VERSION "HNNBNNNYNNNNNNNNNNNNNNNNNNNNNNNNNNNNNNNNNN/4/%%%/4/'%**4NNN///"

NS_ :

BS_:

BU_: BAP_Tester Gateway_Max Getriebe_DQ Motor_konv Parksperre Schaltbetaetigung

BO_ 270 Getriebe_50: 48 Getriebe_DQ
 SG_ Getriebe_50_CRC : 0|8@1+ (1,0) [0|255] ""  Gateway_Max,Motor_konv
 SG_ Getriebe_50_BZ : 8|4@1+ (1,0) [0|15] ""  Gateway_Max,Motor_konv
 SG_ GE_MMom_Soll_02 : 12|10@1+ (1,-509) [-509|509] ""  Gateway_Max,Motor_konv
 SG_ GE_MMom_Vorhalt_02 : 22|10@1+ (1,-509) [-509|509] ""  Gateway_Max,Motor_konv
 SG_ GE_Uefkt : 32|10@1+ (0.1,0) [0.0|102.2] ""  Gateway_Max,Motor_konv
 SG_ GE2_Fahrstufe : 42|4@1+ (1.0,0.0) [0.0|15] ""  Gateway_Max,Motor_konv
 SG_ GE2_Ursache_Fahrstufe_N : 46|1@1+ (1.0,0.0) [0.0|1] ""  Gateway_Max
 SG_ GE_Schaltablauf : 47|2@1+ (1.0,0.0) [0.0|3] ""  Gateway_Max,Motor_konv
 SG_ GE_Uefkt_unplausibel : 49|1@1+ (1.0,0.0) [0.0|1] ""  Gateway_Max
 SG_ GE_MMom_Status_02 : 50|3@1+ (1.0,0.0) [0.0|7] ""  Gateway_Max,Motor_konv
 SG_ GE_Status_Kraftschluss : 53|3@1+ (1.0,0.0) [0.0|7] ""  Gateway_Max,Motor_konv
 SG_ GE_MMom_Status : 56|2@1+ (1.0,0.0) [0.0|3] ""  Gateway_Max,Motor_konv
 SG_ GE_Freig_MMom_Vorhalt : 58|1@1+ (1.0,0.0) [0.0|1] ""  Gateway_Max,Motor_konv
 SG_ GE_Verbot_Ausblendung : 59|1@1+ (1.0,0.0) [0.0|1] ""  Gateway_Max,Motor_konv
 SG_ GE_Zielgang : 60|4@1+ (1.0,0.0) [0.0|15] ""  Gateway_Max,Motor_konv
 SG_ GE_Fahrstufenwunsch : 72|4@1+ (1.0,0.0) [0.0|15] ""  Gateway_Max,Motor_konv
 SG_ GE_Drehzahlmesser_Daempfung : 76|1@1+ (1.0,0.0) [0.0|1] ""  Gateway_Max,Motor_konv
 SG_ GE_Schubabschalt_Unt : 77|1@1+ (1.0,0.0) [0.0|1] ""  Gateway_Max,Motor_konv
 SG_ GE_Freigabe_Synchro : 78|1@1+ (1.0,0.0) [0.0|1] ""  Gateway_Max,Motor_konv
 SG_ GE_Synchro_Wunschdrehz : 79|9@1+ (25,0) [25|12750] "Unit_MinutInver"  Gateway_Max,Motor_konv
 SG_ GE_Synchro_Zeit : 88|8@1+ (20,0) [0|5080] "Unit_MilliSecon"  Gateway_Max,Motor_konv
 SG_ GE_Mom_Begr_Gradient : 96|8@1+ (10,0) [0|2540] "Unit_NewtoMeterPerSecon"  Gateway_Max,Motor_konv
 SG_ GE_Anheb_Solldrehz_Leerlauf : 104|8@1+ (10,0) [0|2540] "Unit_MinutInver"  Gateway_Max,Motor_konv
 SG_ GE_Aufnahmemoment : 112|10@1+ (1,-509) [-509|509] ""  Gateway_Max,Motor_konv
 SG_ GE_Synchro_Status_02 : 122|4@1+ (1.0,0.0) [0.0|15] ""  Gateway_Max,Motor_konv
 SG_ GE_StartStopp_Info : 140|2@1+ (1.0,0.0) [0.0|3] ""  Gateway_Max,Motor_konv
 SG_ GE_Langfr_Schutzmom_02 : 142|9@1+ (1,0) [0|509] ""  Gateway_Max,Motor_konv
 SG_ GE_Entkopplung_Status : 151|2@1+ (1.0,0.0) [0.0|3] ""  Gateway_Max
 SG_ GE_Verlustmoment : 160|8@1+ (1,0) [0|254] ""  Gateway_Max,Motor_konv
 SG_ GE_Anf_Zylabsch : 168|2@1+ (1.0,0.0) [0.0|3] ""  Gateway_Max,Motor_konv
 SG_ GE_Grenzkriechmoment : 170|6@1+ (2,0) [0|122] ""  Gateway_Max
 SG_ GE_Eingangsdrehz : 176|14@1+ (1,0) [0|16381] "Unit_MinutInver"  Gateway_Max,Motor_konv
 SG_ GE_Notlauf : 190|1@1+ (1.0,0.0) [0.0|1] ""  Gateway_Max,Motor_konv
 SG_ GE_Freig_Langfr_Schutzmom : 191|1@1+ (1.0,0.0) [0.0|1] ""  Gateway_Max,Motor_konv
 SG_ GE_HYB_Fehlerstatus : 204|2@1+ (1.0,0.0) [0.0|3] ""  Gateway_Max
 SG_ GE_HYB_DZ_Eingriff : 206|2@1+ (1.0,0.0) [0.0|3] ""  Gateway_Max
 SG_ GE_HYB_Freigabe_K0 : 208|1@1+ (1.0,0.0) [0.0|1] ""  Gateway_Max
 SG_ GE_HYB_MaxMomK0 : 209|2@1+ (1.0,0.0) [0.0|3] ""  Gateway_Max
 SG_ GE_HYB_Freig_VM_EM_Stop : 211|1@1+ (1.0,0.0) [0.0|1] ""  Gateway_Max
 SG_ GE_HYB_Wiederstart : 212|1@1+ (1.0,0.0) [0.0|1] ""  Gateway_Max
 SG_ GE_HYB_Filt_MomAufbau : 213|3@1+ (1.0,0.0) [0.0|7] ""  Gateway_Max
 SG_ GE_HYB_nK0 : 216|8@1+ (25,0) [0|6350] "Unit_MinutInver"  Gateway_Max
 SG_ GE_HYB_EM_KompMom : 224|7@1+ (2,0) [0|254] "Unit_NewtoMeter"  Gateway_Max
 SG_ GE_HYB_IstStatus_K0 : 231|2@1+ (1.0,0.0) [0.0|3] ""  Gateway_Max
 SG_ GE_HYB_Wiederstartreserve : 233|7@1+ (2,0) [0|254] "Unit_NewtoMeter"  Gateway_Max
 SG_ GE_HYB_VM_Soll_Moment : 240|8@1+ (1.186,-50) [-50.000|250.058] "Unit_NewtoMeter"  Gateway_Max
 SG_ GE_HYB_Sportfaktor : 248|4@1+ (1.0,0.0) [0.0|15] ""  Gateway_Max
 SG_ GE_HYB_Freigabe_LL_Reg : 252|1@1+ (1.0,0.0) [0.0|1] ""  Gateway_Max
 SG_ GE_HYB_VM_akt_halten : 253|1@1+ (1.0,0.0) [0.0|1] ""  Gateway_Max
 SG_ GE_HYB_StartAnf : 254|1@1+ (1.0,0.0) [0.0|1] ""  Gateway_Max
 SG_ GE_HYB_VM_Startkontr : 255|1@1+ (1.0,0.0) [0.0|1] ""  Gateway_Max
 SG_ GE_Radmoment : 256|16@1+ (0.5,-16383) [-16383.0|16383.5] "Unit_NewtoMeter"  Gateway_Max,Motor_konv
 SG_ GE_Abtriebsdrehzahl : 272|16@1+ (0.1,-3276.65) [-3276.65|3276.65] "Unit_MinutInver"  Gateway_Max,Motor_konv
 SG_ GE_Eingangswellengradient : 288|16@1+ (0.25,-8191.5) [-8191.50|8191.75] "Unit_MeterInver"  Gateway_Max,Motor_konv

BO_ 509 Getriebe_51: 32 Getriebe_DQ
 SG_ Getriebe_51_CRC : 0|8@1+ (1,0) [0|255] ""  Gateway_Max,Motor_konv
 SG_ Getriebe_51_BZ : 8|4@1+ (1,0) [0|15] ""  Gateway_Max,Motor_konv
 SG_ GE_OBD_AbsperrVent : 12|4@1+ (1.0,0.0) [0.0|15] ""  Gateway_Max,Motor_konv
 SG_ GE_amax_moeglich : 16|9@1+ (0.024,-2.016) [-2.016|10.224] "Unit_MeterPerSeconSquar"  Gateway_Max,Motor_konv
 SG_ GE_Charisma_FahrPr : 25|4@1+ (1.0,0.0) [0.0|15] ""  Gateway_Max
 SG_ GE_Charisma_Status : 29|2@1+ (1.0,0.0) [0.0|3] ""  Gateway_Max
 SG_ GE_Freigabe_Verfallsinfo_WFS : 31|1@1+ (1.0,0.0) [0.0|1] ""  Gateway_Max,Motor_konv
 SG_ Freilauf_Charisma_FahrPr : 40|4@1+ (1.0,0.0) [0.0|15] ""  Gateway_Max
 SG_ Freilauf_Charisma_Status : 44|2@1+ (1.0,0.0) [0.0|3] ""  Gateway_Max
 SG_ GE_Freigabe_Info_WFS : 46|1@1+ (1.0,0.0) [0.0|1] ""  Gateway_Max,Motor_konv
 SG_ GE_Sperr_Info_WFS : 47|1@1+ (1.0,0.0) [0.0|1] ""  Gateway_Max,Motor_konv
 SG_ GE_Zustand_Kuppltemp : 48|2@1+ (1.0,0.0) [0.0|3] ""  Gateway_Max
 SG_ GE_Codierung_MSG : 50|1@1+ (1.0,0.0) [0.0|1] ""  Gateway_Max
 SG_ GE_LaunchControl : 51|1@1+ (1.0,0.0) [0.0|1] ""  Gateway_Max,Motor_konv
 SG_ GE_Heizwunsch : 52|2@1+ (1.0,0.0) [0.0|3] ""  Gateway_Max,Motor_konv
 SG_ GE_OBD_Status : 54|1@1+ (1.0,0.0) [0.0|1] ""  Gateway_Max,Motor_konv
 SG_ GE_LFR_Adaption : 55|1@1+ (1.0,0.0) [0.0|1] ""  Gateway_Max,Motor_konv
 SG_ GE_Sumpftemperatur : 56|8@1+ (1,-58) [-58|196] "Unit_DegreCelsi"  Gateway_Max,Motor_konv
 SG_ GE_Schleuderoeltemperatur : 64|8@1+ (1,-58) [-58|195] "Unit_DegreCelsi"  Gateway_Max
 SG_ GE_Weckleitung_aktiv : 72|1@1+ (1.0,0.0) [0.0|1] ""  Gateway_Max
 SG_ GE_Fahrprogramm : 76|4@1+ (1.0,0.0) [0.0|15] ""  Gateway_Max,Motor_konv
 SG_ GE_TippZustand : 80|2@1+ (1.0,0.0) [0.0|3] ""  Gateway_Max,Motor_konv
 SG_ GE_Freilauf_Status : 82|3@1+ (1.0,0.0) [0.0|7] ""  Gateway_Max,Motor_konv
 SG_ GE_Grundeinstellung : 85|1@1+ (1.0,0.0) [0.0|1] ""  Gateway_Max
 SG_ GE_Anschleppstart_Freigabe : 86|1@1+ (1.0,0.0) [0.0|1] ""  Gateway_Max,Motor_konv
 SG_ GE_Strombedarf_erh : 87|1@1+ (1.0,0.0) [0.0|1] ""  Gateway_Max
 SG_ GE_Parken_WFS_Status : 88|2@1+ (1.0,0.0) [0.0|3] ""  Gateway_Max
 SG_ FSA_Fehlerstatus_Parksperre : 90|2@1+ (1.0,0.0) [0.0|3] ""  Gateway_Max
 SG_ GE_SpannungsAnf : 97|2@1+ (1.0,0.0) [0.0|3] ""  Gateway_Max
 SG_ GE_QBit_Sumpftemperatur : 99|1@1+ (1.0,0.0) [0.0|1] ""  Gateway_Max
 SG_ GE_Grundeinstell_Drehrichtung_EM : 100|1@1+ (1.0,0.0) [0.0|1] ""  Gateway_Max
 SG_ GE_Veto_Rollfaehigkeit : 101|1@1+ (1.0,0.0) [0.0|1] ""  Gateway_Max
 SG_ GE_Parken_beibehalten_HMS : 102|2@1+ (1.0,0.0) [0.0|3] ""  Gateway_Max
 SG_ GE_Anforderung_HMS : 104|3@1+ (1.0,0.0) [0.0|7] ""  Gateway_Max
 SG_ GE_Betaetigung_Hold : 107|1@1+ (1.0,0.0) [0.0|1] ""  Gateway_Max

BO_ 2589283964 Getriebe_52: 16 Getriebe_DQ
 SG_ GE_OBD_Status_Auth : 12|1@1+ (1.0,0.0) [0.0|1] ""  Motor_konv
 SG_ GE_Indc_StChk : 13|1@1+ (1.0,0.0) [0.0|1] ""  Motor_konv
 SG_ GE_Indc_StFail : 14|1@1+ (1.0,0.0) [0.0|1] ""  Motor_konv
 SG_ SOK_Getriebe_52_Signatur : 64|64@1+ (1,0) [1|18446744073709551615] "Unit_None"  Motor_konv

BO_ 299 GRA_ACC_01: 8 Gateway_Max
 SG_ GRA_ACC_01_CRC : 0|8@1+ (1,0) [0|255] ""  Motor_konv
 SG_ GRA_ACC_01_BZ : 8|4@1+ (1,0) [0|15] ""  Motor_konv
 SG_ GRA_Hauptschalter : 12|1@1+ (1.0,0.0) [0.0|1] ""  Motor_konv
 SG_ GRA_Abbrechen : 13|1@1+ (1.0,0.0) [0.0|1] ""  Motor_konv
 SG_ GRA_Typ_Hauptschalter : 14|1@1+ (1.0,0.0) [0.0|1] ""  Motor_konv
 SG_ GRA_Limiter : 15|1@1+ (1.0,0.0) [0.0|1] ""  Motor_konv
 SG_ GRA_Tip_Setzen : 16|1@1+ (1.0,0.0) [0.0|1] ""  Motor_konv
 SG_ GRA_Tip_Hoch : 17|1@1+ (1.0,0.0) [0.0|1] ""  Motor_konv
 SG_ GRA_Tip_Runter : 18|1@1+ (1.0,0.0) [0.0|1] ""  Motor_konv
 SG_ GRA_Tip_Wiederaufnahme : 19|1@1+ (1.0,0.0) [0.0|1] ""  Motor_konv
 SG_ GRA_Verstellung_Zeitluecke : 20|2@1+ (1.0,0.0) [0.0|3] ""  Motor_konv
 SG_ GRA_Codierung : 22|2@1+ (1.0,0.0) [0.0|3] ""  Motor_konv
 SG_ GRA_Fehler : 24|1@1+ (1.0,0.0) [0.0|1] ""  Motor_konv
 SG_ GRA_LIM_Taste_verfuegbar : 25|1@1+ (1.0,0.0) [0.0|1] ""  Motor_konv
 SG_ GRA_Tip_Stufe_2 : 26|1@1+ (1.0,0.0) [0.0|1] ""  Motor_konv
 SG_ GRA_Typ_Bedienteil : 27|3@1+ (1.0,0.0) [0.0|7] ""  Motor_konv
 SG_ GRA_TravelAssist : 30|1@1+ (1.0,0.0) [0.0|1] ""  Vector__XXX
 SG_ GRA_PIT_Limiter : 31|1@1+ (1.0,0.0) [0.0|1] ""  Motor_konv
 SG_ GRA_reserveByte5 : 32|8@1+ (1.0,0.0) [0.0|255] ""  Vector__XXX
 SG_ GRA_reserveByte6 : 40|8@1+ (1.0,0.0) [0.0|255] ""  Vector__XXX
 SG_ GRA_reserveByte7 : 48|8@1+ (1.0,0.0) [0.0|255] ""  Vector__XXX
 SG_ GRA_reserveByte8 : 56|8@1+ (1.0,0.0) [0.0|255] ""  Vector__XXX

BO_ 18 GSG_WFS_Anfrage: 8 Getriebe_DQ
 SG_ WFS_GSG_RND : 0|32@1+ (1.0,0.0) [0.0|4294967295] ""  Gateway_Max
 SG_ WFS_GSG_CRC : 32|32@1+ (1.0,0.0) [0.0|4294967295] ""  Gateway_Max

BO_ 2589283397 GW_CVN_Komponentenfehler_02: 32 Gateway_Max
 SG_ GW_CAL_ID_Index_01 : 0|8@1+ (1.0,0.0) [0.0|255] ""  Motor_konv
 SG_ GW_CAL_ID_Index_02 : 8|8@1+ (1.0,0.0) [0.0|255] ""  Motor_konv
 SG_ GW_CAL_ID_Index_03 : 16|8@1+ (1.0,0.0) [0.0|255] ""  Motor_konv
 SG_ GW_CAL_ID_Index_04 : 24|8@1+ (1.0,0.0) [0.0|255] ""  Motor_konv
 SG_ GW_CAL_ID_Index_05 : 32|8@1+ (1.0,0.0) [0.0|255] ""  Motor_konv
 SG_ GW_CAL_ID_Index_06 : 40|8@1+ (1.0,0.0) [0.0|255] ""  Motor_konv
 SG_ GW_CAL_ID_Index_07 : 48|8@1+ (1.0,0.0) [0.0|255] ""  Motor_konv
 SG_ GW_CAL_ID_Index_08 : 56|8@1+ (1.0,0.0) [0.0|255] ""  Motor_konv
 SG_ GW_CAL_ID_Index_09 : 64|8@1+ (1.0,0.0) [0.0|255] ""  Motor_konv
 SG_ GW_CAL_ID_Index_10 : 72|8@1+ (1.0,0.0) [0.0|255] ""  Motor_konv
 SG_ GW_CAL_ID_Index_11 : 80|8@1+ (1.0,0.0) [0.0|255] ""  Motor_konv
 SG_ GW_CAL_ID_Index_12 : 88|8@1+ (1.0,0.0) [0.0|255] ""  Motor_konv
 SG_ GW_CAL_ID_Index_13 : 96|8@1+ (1.0,0.0) [0.0|255] ""  Motor_konv
 SG_ GW_CAL_ID_Index_14 : 104|8@1+ (1.0,0.0) [0.0|255] ""  Motor_konv
 SG_ GW_CAL_ID_Index_15 : 112|8@1+ (1.0,0.0) [0.0|255] ""  Motor_konv
 SG_ GW_CAL_ID_Index_16 : 120|8@1+ (1.0,0.0) [0.0|255] ""  Motor_konv
 SG_ GW_KomponentenFehler_01 : 128|2@1+ (1.0,0.0) [0.0|3] ""  Motor_konv
 SG_ GW_Komponentenfehler_02 : 130|2@1+ (1.0,0.0) [0.0|3] ""  Motor_konv
 SG_ GW_Komponentenfehler_03 : 132|2@1+ (1.0,0.0) [0.0|3] ""  Motor_konv
 SG_ GW_Komponentenfehler_04 : 134|2@1+ (1.0,0.0) [0.0|3] ""  Motor_konv
 SG_ GW_Komponentenfehler_05 : 136|2@1+ (1.0,0.0) [0.0|3] ""  Motor_konv
 SG_ GW_Komponentenfehler_06 : 138|2@1+ (1.0,0.0) [0.0|3] ""  Motor_konv
 SG_ GW_Komponentenfehler_07 : 140|2@1+ (1.0,0.0) [0.0|3] ""  Motor_konv
 SG_ GW_Komponentenfehler_08 : 142|2@1+ (1.0,0.0) [0.0|3] ""  Motor_konv
 SG_ GW_Komponentenfehler_09 : 144|2@1+ (1.0,0.0) [0.0|3] ""  Motor_konv
 SG_ GW_Komponentenfehler_10 : 146|2@1+ (1.0,0.0) [0.0|3] ""  Motor_konv
 SG_ GW_Komponentenfehler_11 : 148|2@1+ (1.0,0.0) [0.0|3] ""  Motor_konv
 SG_ GW_Komponentenfehler_12 : 150|2@1+ (1.0,0.0) [0.0|3] ""  Motor_konv
 SG_ GW_Komponentenfehler_13 : 152|2@1+ (1.0,0.0) [0.0|3] ""  Getriebe_DQ,Motor_konv
 SG_ GW_Komponentenfehler_14 : 154|2@1+ (1.0,0.0) [0.0|3] ""  Motor_konv
 SG_ GW_Komponentenfehler_15 : 156|2@1+ (1.0,0.0) [0.0|3] ""  Motor_konv
 SG_ GW_Komponentenfehler_16 : 158|2@1+ (1.0,0.0) [0.0|3] ""  Motor_konv
 SG_ GW_CVN : 160|32@1+ (1.0,0.0) [0.0|4294967295] ""  Motor_konv
 SG_ GW_Komponentenfehler_17 : 192|2@1+ (1.0,0.0) [0.0|3] ""  Motor_konv
 SG_ GW_Komponentenfehler_18 : 194|2@1+ (1.0,0.0) [0.0|3] ""  Motor_konv
 SG_ GW_Komponentenfehler_19 : 196|2@1+ (1.0,0.0) [0.0|3] ""  Motor_konv
 SG_ GW_Komponentenfehler_20 : 198|2@1+ (1.0,0.0) [0.0|3] ""  Motor_konv
 SG_ GW_Komponentenfehler_21 : 200|2@1+ (1.0,0.0) [0.0|3] ""  Motor_konv
 SG_ GW_Komponentenfehler_22 : 202|2@1+ (1.0,0.0) [0.0|3] ""  Motor_konv
 SG_ GW_Komponentenfehler_23 : 204|2@1+ (1.0,0.0) [0.0|3] ""  Motor_konv
 SG_ GW_Komponentenfehler_24 : 206|2@1+ (1.0,0.0) [0.0|3] ""  Motor_konv
 SG_ GW_Komponentenfehler_25 : 208|2@1+ (1.0,0.0) [0.0|3] ""  Motor_konv
 SG_ GW_Komponentenfehler_26 : 210|2@1+ (1.0,0.0) [0.0|3] ""  Motor_konv
 SG_ GW_Komponentenfehler_27 : 212|2@1+ (1.0,0.0) [0.0|3] ""  Motor_konv
 SG_ GW_Komponentenfehler_28 : 214|2@1+ (1.0,0.0) [0.0|3] ""  Motor_konv
 SG_ GW_Komponentenfehler_29 : 216|2@1+ (1.0,0.0) [0.0|3] ""  Motor_konv
 SG_ GW_Komponentenfehler_30 : 218|2@1+ (1.0,0.0) [0.0|3] ""  Motor_konv
 SG_ GW_Komponentenfehler_31 : 220|2@1+ (1.0,0.0) [0.0|3] ""  Motor_konv
 SG_ GW_Komponentenfehler_32 : 222|2@1+ (1.0,0.0) [0.0|3] ""  Motor_konv
 SG_ GW_Komponentenfehler_33 : 224|2@1+ (1.0,0.0) [0.0|3] ""  Motor_konv
 SG_ GW_Komponentenfehler_34 : 226|2@1+ (1.0,0.0) [0.0|3] ""  Motor_konv
 SG_ GW_Komponentenfehler_35 : 228|2@1+ (1.0,0.0) [0.0|3] ""  Motor_konv
 SG_ GW_Komponentenfehler_36 : 230|2@1+ (1.0,0.0) [0.0|3] ""  Motor_konv
 SG_ GW_Komponentenfehler_37 : 232|2@1+ (1.0,0.0) [0.0|3] ""  Motor_konv
 SG_ GW_Komponentenfehler_38 : 234|2@1+ (1.0,0.0) [0.0|3] ""  Motor_konv
 SG_ GW_Komponentenfehler_39 : 236|2@1+ (1.0,0.0) [0.0|3] ""  Motor_konv
 SG_ GW_Komponentenfehler_40 : 238|2@1+ (1.0,0.0) [0.0|3] ""  Motor_konv
 SG_ GW_Komponentenfehler_41 : 240|2@1+ (1.0,0.0) [0.0|3] ""  Motor_konv
 SG_ GW_Komponentenfehler_42 : 242|2@1+ (1.0,0.0) [0.0|3] ""  Motor_konv
 SG_ GW_Komponentenfehler_43 : 244|2@1+ (1.0,0.0) [0.0|3] ""  Motor_konv
 SG_ GW_Komponentenfehler_44 : 246|2@1+ (1.0,0.0) [0.0|3] ""  Motor_konv
 SG_ GW_Komponentenfehler_45 : 248|2@1+ (1.0,0.0) [0.0|3] ""  Motor_konv
 SG_ GW_Komponentenfehler_46 : 250|2@1+ (1.0,0.0) [0.0|3] ""  Motor_konv
 SG_ GW_Komponentenfehler_47 : 252|2@1+ (1.0,0.0) [0.0|3] ""  Motor_konv
 SG_ GW_Komponentenfehler_VLD : 254|1@1+ (1.0,0.0) [0.0|1] ""  Motor_konv
 SG_ GW_CVN_VLD : 255|1@1+ (1.0,0.0) [0.0|1] ""  Motor_konv

BO_ 2589283454 GW_CVN_Komponentenfehler_02_S000: 8 Gateway_Max
 SG_ SOK_GW_CVN_Komp_02_Signatur : 0|64@1+ (1,0) [1|18446744073709551615] "Unit_None"  Motor_konv

BO_ 2589284072 GW_CVN_Komponentenfehler_03: 32 Gateway_Max
 SG_ GW_Komponentenfehler_48 : 0|2@1+ (1.0,0.0) [0.0|3] ""  Motor_konv
 SG_ GW_Komponentenfehler_49 : 2|2@1+ (1.0,0.0) [0.0|3] ""  Motor_konv
 SG_ GW_Komponentenfehler_50 : 4|2@1+ (1.0,0.0) [0.0|3] ""  Motor_konv
 SG_ GW_Komponentenfehler_51 : 6|2@1+ (1.0,0.0) [0.0|3] ""  Motor_konv
 SG_ GW_Komponentenfehler_52 : 8|2@1+ (1.0,0.0) [0.0|3] ""  Motor_konv
 SG_ GW_Komponentenfehler_53 : 10|2@1+ (1.0,0.0) [0.0|3] ""  Motor_konv
 SG_ GW_Komponentenfehler_54 : 12|2@1+ (1.0,0.0) [0.0|3] ""  Motor_konv
 SG_ GW_Komponentenfehler_55 : 14|2@1+ (1.0,0.0) [0.0|3] ""  Motor_konv
 SG_ GW_Komponentenfehler_56 : 16|2@1+ (1.0,0.0) [0.0|3] ""  Motor_konv
 SG_ GW_Komponentenfehler_57 : 18|2@1+ (1.0,0.0) [0.0|3] ""  Motor_konv
 SG_ GW_Komponentenfehler_58 : 20|2@1+ (1.0,0.0) [0.0|3] ""  Motor_konv
 SG_ GW_Komponentenfehler_59 : 22|2@1+ (1.0,0.0) [0.0|3] ""  Motor_konv
 SG_ GW_Komponentenfehler_60 : 24|2@1+ (1.0,0.0) [0.0|3] ""  Motor_konv
 SG_ GW_Komponentenfehler_61 : 26|2@1+ (1.0,0.0) [0.0|3] ""  Motor_konv
 SG_ GW_Komponentenfehler_62 : 28|2@1+ (1.0,0.0) [0.0|3] ""  Motor_konv
 SG_ GW_Komponentenfehler_63 : 30|2@1+ (1.0,0.0) [0.0|3] ""  Motor_konv
 SG_ GW_Komponentenfehler_64 : 32|2@1+ (1.0,0.0) [0.0|3] ""  Motor_konv
 SG_ SOK_GW_CVN_Komp_03_Signatur : 192|64@1+ (1,0) [1|18446744073709551615] "Unit_None"  Motor_konv

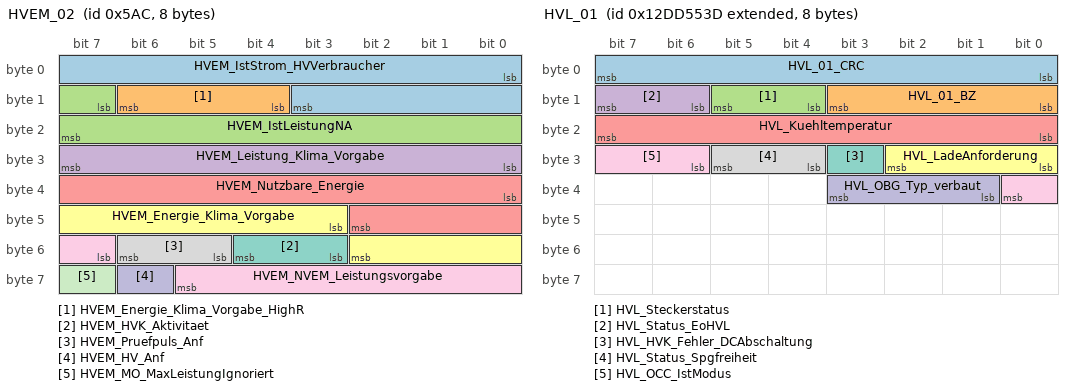
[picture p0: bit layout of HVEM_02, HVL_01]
BO_ 1452 HVEM_02: 8 Gateway_Max
 SG_ HVEM_IstStrom_HVVerbraucher : 0|12@1+ (0.1,-204.7) [-204.7|204.6] "Unit_Amper"  Vector__XXX
 SG_ HVEM_Energie_Klima_Vorgabe_HighR : 12|3@1+ (10,0) [0|50] "Unit_WattHour"  Vector__XXX
 SG_ HVEM_IstLeistungNA : 15|9@1+ (50,0) [0|25450] "Unit_Watt"  Vector__XXX
 SG_ HVEM_Leistung_Klima_Vorgabe : 24|8@1+ (50,0) [0|12650] "Unit_Watt"  Vector__XXX
 SG_ HVEM_Nutzbare_Energie : 32|11@1+ (50,0) [0|102200] "Unit_WattHour"  Vector__XXX
 SG_ HVEM_Energie_Klima_Vorgabe : 43|8@1+ (50,0) [0|12650] "Unit_WattHour"  Vector__XXX
 SG_ HVEM_HVK_Aktivitaet : 51|2@1+ (1.0,0.0) [0.0|3] ""  Vector__XXX
 SG_ HVEM_Pruefpuls_Anf : 53|2@1+ (1.0,0.0) [0.0|3] ""  Vector__XXX
 SG_ HVEM_NVEM_Leistungsvorgabe : 55|7@1+ (50,0) [0|6250] "Unit_Watt"  Vector__XXX
 SG_ HVEM_HV_Anf : 62|1@1+ (1.0,0.0) [0.0|1] ""  Vector__XXX
 SG_ HVEM_MO_MaxLeistungIgnoriert : 63|1@1+ (1.0,0.0) [0.0|1] ""  Vector__XXX

BO_ 1385 HVEM_04: 8 Gateway_Max
 SG_ HVEM_ZusatzMinLeistungNA_Anf : 0|9@1+ (50,0) [0|25450] "Unit_Watt"  Vector__XXX
 SG_ HVEM_Betriebsart : 9|3@1+ (1.0,0.0) [0.0|7] ""  Vector__XXX
 SG_ HVEM_NVLeistungEmpf : 12|4@1+ (100,0) [0|1500] "Unit_Watt"  Vector__XXX
 SG_ HVEM_DCDC_Freigabe : 16|1@1+ (1.0,0.0) [0.0|1] ""  Vector__XXX
 SG_ HVEM_KlimaMaxHVStrom : 17|5@1+ (1,0) [0|31] "Unit_Amper"  Vector__XXX
 SG_ HVEM_Ladesteckerentr_Anf : 23|1@1+ (1.0,0.0) [0.0|1] ""  Vector__XXX
 SG_ HVEM_LeistungsAnf : 24|1@1+ (1.0,0.0) [0.0|1] ""  Vector__XXX
 SG_ HVEM_Nachlad_Status : 25|2@1+ (1.0,0.0) [0.0|3] ""  Vector__XXX
 SG_ HVEM_Abschaltstatus : 27|3@1+ (1.0,0.0) [0.0|7] ""  Vector__XXX
 SG_ HVEM_Anf_ReichweiteNV : 30|2@1+ (1.0,0.0) [0.0|3] ""  Vector__XXX
 SG_ HVEM_WunschLeistungNA_Anf : 32|9@1+ (50,0) [0|25450] "Unit_Watt"  Vector__XXX
 SG_ HVEM_Text_1 : 41|1@1+ (1.0,0.0) [0.0|1] ""  Vector__XXX
 SG_ HVEM_Nachladen_Anf : 42|1@1+ (1.0,0.0) [0.0|1] ""  Vector__XXX
 SG_ HVEM_FreigabeKlimatisierung : 43|2@1+ (1.0,0.0) [0.0|3] ""  Vector__XXX
 SG_ HVEM_FreigabeBattHeizung : 45|2@1+ (1.0,0.0) [0.0|3] ""  Vector__XXX
 SG_ HVEM_MinLeistungNA_Anf : 47|9@1+ (50,0) [0|25450] "Unit_Watt"  Vector__XXX
 SG_ HVEM_Leistung_Bat_Kond_Vorgabe : 56|8@1+ (50,0) [0|12650] "Unit_Watt"  Vector__XXX

BO_ 1283 HVK_01: 8 Vector__XXX
 SG_ HVK_01_CRC : 0|8@1+ (1,0) [0|255] ""  Gateway_Max
 SG_ HVK_01_BZ : 8|4@1+ (1,0) [0|15] ""  Gateway_Max
 SG_ HVK_Istmodus_Anf : 12|1@1+ (1.0,0.0) [0.0|1] ""  Gateway_Max
 SG_ HVK_TN1_Sollmodus : 13|2@1+ (1.0,0.0) [0.0|3] ""  Gateway_Max
 SG_ HVK_Vorladung_aktiv : 15|1@1+ (1.0,0.0) [0.0|1] ""  Gateway_Max
 SG_ HVK_BMS_Sollmodus : 24|3@1+ (1.0,0.0) [0.0|7] ""  Gateway_Max
 SG_ HVK_DCDC_Sollmodus : 27|3@1+ (1.0,0.0) [0.0|7] ""  Gateway_Max
 SG_ HVK_EKK_Sollmodus : 30|3@1+ (1.0,0.0) [0.0|7] ""  Gateway_Max
 SG_ HVK_HVPTC_Sollmodus : 33|3@1+ (1.0,0.0) [0.0|7] ""  Gateway_Max
 SG_ HVK_HVLM_Sollmodus : 36|3@1+ (1.0,0.0) [0.0|7] ""  Gateway_Max
 SG_ HVK_HV_Netz_Warnungen : 39|2@1+ (1.0,0.0) [0.0|3] ""  Gateway_Max
 SG_ HV_Bordnetz_aktiv : 41|1@1+ (1.0,0.0) [0.0|1] ""  Gateway_Max
 SG_ HV_Bordnetz_Fehler : 42|1@1+ (1.0,0.0) [0.0|1] ""  Gateway_Max
 SG_ HVK_Gesamtst_Spgfreiheit : 43|2@1+ (1.0,0.0) [0.0|3] ""  Gateway_Max
 SG_ HVK_AktiveEntladung_Anf : 45|1@1+ (1.0,0.0) [0.0|1] ""  Gateway_Max
 SG_ HVK_HVEM_Freigabe : 46|2@1+ (1.0,0.0) [0.0|3] ""  Gateway_Max
 SG_ HVK_Notabschaltung_Anf : 48|2@1+ (1.0,0.0) [0.0|3] ""  Gateway_Max
 SG_ HVK_Iso_Messung_Start : 50|3@1+ (1.0,0.0) [0.0|7] ""  Gateway_Max
 SG_ HVK_Ladebereit : 53|3@1+ (1.0,0.0) [0.0|7] ""  Gateway_Max
 SG_ HVK_PPulsFreigabe : 56|2@1+ (1.0,0.0) [0.0|3] ""  Gateway_Max

BO_ 2331595857 HVK_04: 24 Vector__XXX
 SG_ HVK_BMS_DC_Ladeschuetze_Soll : 12|3@1+ (1.0,0.0) [0.0|7] ""  Gateway_Max
 SG_ HVK_BMS_Hauptschuetze_Soll : 15|3@1+ (1.0,0.0) [0.0|7] ""  Gateway_Max
 SG_ HVK_DC_PruefpulsStatus : 18|2@1+ (1.0,0.0) [0.0|3] ""  Gateway_Max

BO_ 2463978813 HVL_01: 8 Gateway_Max
 SG_ HVL_01_CRC : 0|8@1+ (1,0) [0|255] ""  Vector__XXX
 SG_ HVL_01_BZ : 8|4@1+ (1,0) [0|15] ""  Vector__XXX
 SG_ HVL_Steckerstatus : 12|2@1+ (1.0,0.0) [0.0|3] ""  Vector__XXX
 SG_ HVL_Status_EoHVL : 14|2@1+ (1.0,0.0) [0.0|3] ""  Vector__XXX
 SG_ HVL_Kuehltemperatur : 16|8@1+ (1,-40) [-40|213] "Unit_DegreCelsi"  Vector__XXX
 SG_ HVL_LadeAnforderung : 24|3@1+ (1.0,0.0) [0.0|7] ""  Vector__XXX
 SG_ HVL_HVK_Fehler_DCAbschaltung : 27|1@1+ (1.0,0.0) [0.0|1] ""  Vector__XXX
 SG_ HVL_Status_Spgfreiheit : 28|2@1+ (1.0,0.0) [0.0|3] ""  Vector__XXX
 SG_ HVL_OCC_IstModus : 30|3@1+ (1.0,0.0) [0.0|7] ""  Vector__XXX
 SG_ HVL_OBG_Typ_verbaut : 33|3@1+ (1.0,0.0) [0.0|7] ""  Vector__XXX

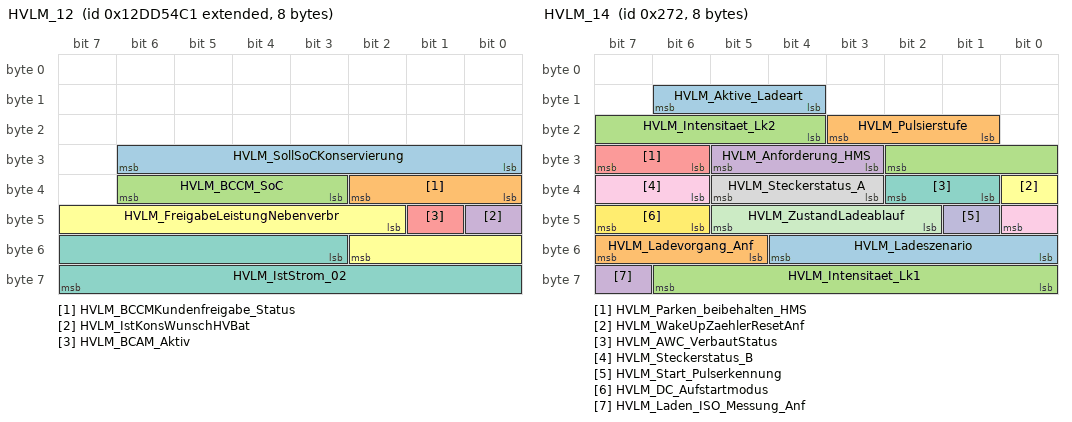
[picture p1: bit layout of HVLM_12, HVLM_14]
BO_ 2463978689 HVLM_12: 8 Gateway_Max
 SG_ HVLM_SollSoCKonservierung : 24|7@1+ (1,0) [0|100] "Unit_PerCent"  Vector__XXX
 SG_ HVLM_BCCMKundenfreigabe_Status : 32|3@1+ (1.0,0.0) [0.0|7] ""  Vector__XXX
 SG_ HVLM_BCCM_SoC : 35|4@1+ (5,50) [50|100] "Unit_PerCent"  Vector__XXX
 SG_ HVLM_IstKonsWunschHVBat : 40|1@1+ (1.0,0.0) [0.0|1] ""  Vector__XXX
 SG_ HVLM_BCAM_Aktiv : 41|1@1+ (1.0,0.0) [0.0|1] ""  Vector__XXX
 SG_ HVLM_FreigabeLeistungNebenverbr : 42|9@1+ (50,0) [0|25500] "Unit_Watt"  Vector__XXX
 SG_ HVLM_IstStrom_02 : 51|13@1+ (0.1,-409.4) [-409.4|409.5] "Unit_Amper"  Vector__XXX

BO_ 626 HVLM_14: 8 Gateway_Max
 SG_ HVLM_Aktive_Ladeart : 12|3@1+ (1.0,0.0) [0.0|7] ""  Vector__XXX
 SG_ HVLM_Pulsierstufe : 17|3@1+ (1.0,0.0) [0.0|7] ""  Vector__XXX
 SG_ HVLM_Intensitaet_Lk2 : 20|7@1+ (1,0) [0|100] "Unit_PerCent"  Vector__XXX
 SG_ HVLM_Anforderung_HMS : 27|3@1+ (1.0,0.0) [0.0|7] ""  Vector__XXX
 SG_ HVLM_Parken_beibehalten_HMS : 30|2@1+ (1.0,0.0) [0.0|3] ""  Vector__XXX
 SG_ HVLM_WakeUpZaehlerResetAnf : 32|1@1+ (1.0,0.0) [0.0|1] ""  Vector__XXX
 SG_ HVLM_AWC_VerbautStatus : 33|2@1+ (1.0,0.0) [0.0|3] ""  Vector__XXX
 SG_ HVLM_Steckerstatus_A : 35|3@1+ (1.0,0.0) [0.0|7] ""  Vector__XXX
 SG_ HVLM_Steckerstatus_B : 38|3@1+ (1.0,0.0) [0.0|7] ""  Vector__XXX
 SG_ HVLM_Start_Pulserkennung : 41|1@1+ (1.0,0.0) [0.0|1] ""  Vector__XXX
 SG_ HVLM_ZustandLadeablauf : 42|4@1+ (1.0,0.0) [0.0|15] ""  Vector__XXX
 SG_ HVLM_DC_Aufstartmodus : 46|2@1+ (1.0,0.0) [0.0|3] ""  Vector__XXX
 SG_ HVLM_Ladeszenario : 48|5@1+ (1.0,0.0) [0.0|31] ""  Vector__XXX
 SG_ HVLM_Ladevorgang_Anf : 53|3@1+ (1.0,0.0) [0.0|7] ""  Vector__XXX
 SG_ HVLM_Intensitaet_Lk1 : 56|7@1+ (1,0) [0|100] "Unit_PerCent"  Vector__XXX
 SG_ HVLM_Laden_ISO_Messung_Anf : 63|1@1+ (1.0,0.0) [0.0|1] ""  Vector__XXX

BO_ 268 IMMO_CORD_01: 8 Motor_konv
 SG_ ImoCord_Auth_Aufforderung_WFS : 63|1@1+ (1.0,0.0) [0.0|1] ""  Getriebe_DQ

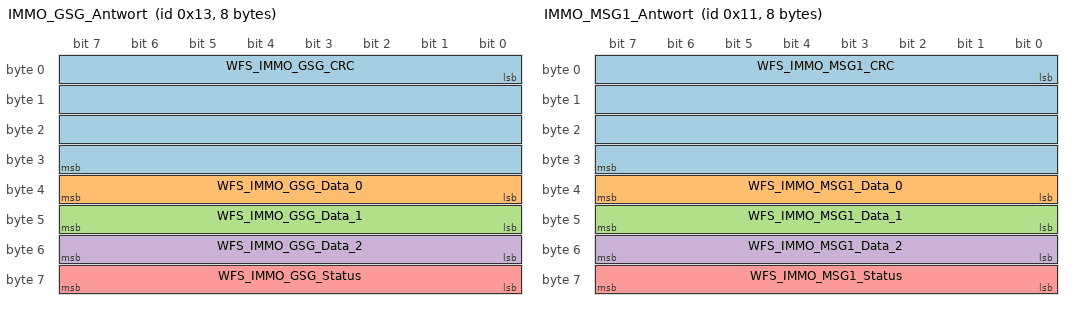
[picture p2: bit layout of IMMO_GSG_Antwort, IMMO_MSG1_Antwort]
BO_ 19 IMMO_GSG_Antwort: 8 Gateway_Max
 SG_ WFS_IMMO_GSG_CRC : 0|32@1+ (1.0,0.0) [0.0|4294967295] ""  Getriebe_DQ
 SG_ WFS_IMMO_GSG_Data_0 : 32|8@1+ (1.0,0.0) [0.0|255] ""  Getriebe_DQ
 SG_ WFS_IMMO_GSG_Data_1 : 40|8@1+ (1.0,0.0) [0.0|255] ""  Getriebe_DQ
 SG_ WFS_IMMO_GSG_Data_2 : 48|8@1+ (1.0,0.0) [0.0|255] ""  Getriebe_DQ
 SG_ WFS_IMMO_GSG_Status : 56|8@1+ (1,0) [0|255] ""  Getriebe_DQ

BO_ 17 IMMO_MSG1_Antwort: 8 Gateway_Max
 SG_ WFS_IMMO_MSG1_CRC : 0|32@1+ (1.0,0.0) [0.0|4294967295] ""  Motor_konv
 SG_ WFS_IMMO_MSG1_Data_0 : 32|8@1+ (1.0,0.0) [0.0|255] ""  Motor_konv
 SG_ WFS_IMMO_MSG1_Data_1 : 40|8@1+ (1.0,0.0) [0.0|255] ""  Motor_konv
 SG_ WFS_IMMO_MSG1_Data_2 : 48|8@1+ (1.0,0.0) [0.0|255] ""  Motor_konv
 SG_ WFS_IMMO_MSG1_Status : 56|8@1+ (1,0) [0|255] ""  Motor_konv

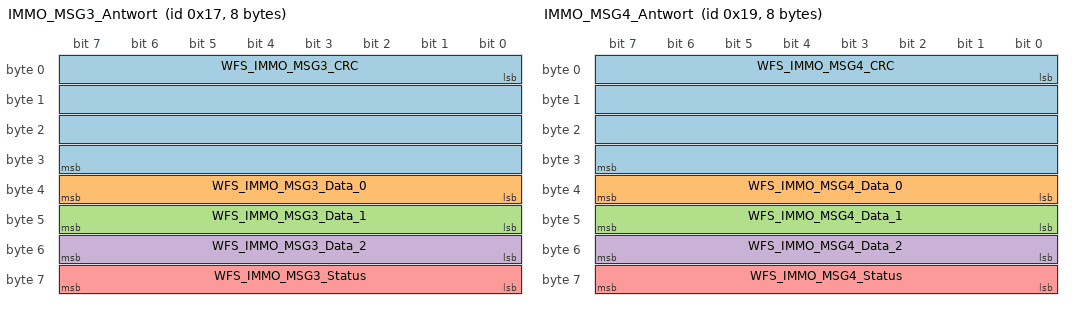
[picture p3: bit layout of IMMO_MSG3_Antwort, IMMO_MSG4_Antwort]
BO_ 23 IMMO_MSG3_Antwort: 8 Gateway_Max
 SG_ WFS_IMMO_MSG3_CRC : 0|32@1+ (1.0,0.0) [0.0|4294967295] ""  Vector__XXX
 SG_ WFS_IMMO_MSG3_Data_0 : 32|8@1+ (1.0,0.0) [0.0|255] ""  Vector__XXX
 SG_ WFS_IMMO_MSG3_Data_1 : 40|8@1+ (1.0,0.0) [0.0|255] ""  Vector__XXX
 SG_ WFS_IMMO_MSG3_Data_2 : 48|8@1+ (1.0,0.0) [0.0|255] ""  Vector__XXX
 SG_ WFS_IMMO_MSG3_Status : 56|8@1+ (1,0) [0|255] ""  Vector__XXX

BO_ 25 IMMO_MSG4_Antwort: 8 Gateway_Max
 SG_ WFS_IMMO_MSG4_CRC : 0|32@1+ (1.0,0.0) [0.0|4294967295] ""  Vector__XXX
 SG_ WFS_IMMO_MSG4_Data_0 : 32|8@1+ (1.0,0.0) [0.0|255] ""  Vector__XXX
 SG_ WFS_IMMO_MSG4_Data_1 : 40|8@1+ (1.0,0.0) [0.0|255] ""  Vector__XXX
 SG_ WFS_IMMO_MSG4_Data_2 : 48|8@1+ (1.0,0.0) [0.0|255] ""  Vector__XXX
 SG_ WFS_IMMO_MSG4_Status : 56|8@1+ (1,0) [0|255] ""  Vector__XXX

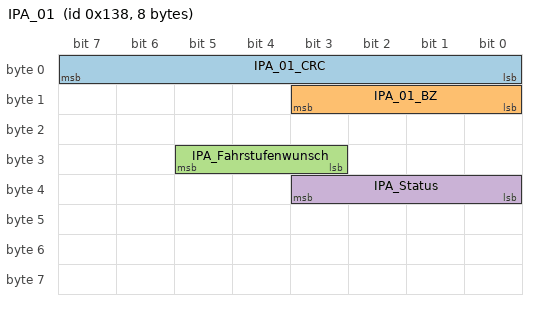
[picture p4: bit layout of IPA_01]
BO_ 312 IPA_01: 8 Gateway_Max
 SG_ IPA_01_CRC : 0|8@1+ (1,0) [0|255] ""  Getriebe_DQ,Motor_konv
 SG_ IPA_01_BZ : 8|4@1+ (1,0) [0|15] ""  Getriebe_DQ,Motor_konv
 SG_ IPA_Fahrstufenwunsch : 27|3@1+ (1.0,0.0) [0.0|7] ""  Getriebe_DQ
 SG_ IPA_Status : 32|4@1+ (1.0,0.0) [0.0|15] ""  Getriebe_DQ,Motor_konv

BO_ 2527679583 IPA_02: 8 Gateway_Max
 SG_ IPA_02_CRC : 0|8@1+ (1,0) [0|255] ""  Vector__XXX
 SG_ IPA_02_BZ : 8|4@1+ (1,0) [0|15] ""  Vector__XXX
 SG_ IPA_PL_Anzeige_links : 12|2@1+ (1.0,0.0) [0.0|3] ""  Vector__XXX
 SG_ IPA_PL_Anzeige_rechts : 14|2@1+ (1.0,0.0) [0.0|3] ""  Vector__XXX
 SG_ Parken_Seitenspiegel_Anf : 20|2@1+ (1.0,0.0) [0.0|3] ""  Vector__XXX
 SG_ Parken_ZV_Schliessen : 22|2@1+ (1.0,0.0) [0.0|3] ""  Vector__XXX
 SG_ Parken_aktives_System_02 : 24|5@1+ (1.0,0.0) [0.0|31] ""  Getriebe_DQ,Motor_konv
 SG_ Parken_ZR_Sondermodus_Anf : 29|2@1+ (1.0,0.0) [0.0|3] ""  Vector__XXX
 SG_ Parken_Schluesselsuche_Anf : 31|1@1+ (1.0,0.0) [0.0|1] ""  Vector__XXX
 SG_ Parken_FFB_LED_Anf : 32|2@1+ (1.0,0.0) [0.0|3] ""  Vector__XXX
 SG_ Parken_Wegfahrsperren_Anf : 34|2@1+ (1.0,0.0) [0.0|3] ""  Vector__XXX
 SG_ Parken_Aktivierungslicht_Anf : 36|1@1+ (1.0,0.0) [0.0|1] ""  Vector__XXX
 SG_ Parken_Fahrtrichtungslicht_Anf : 37|2@1+ (1.0,0.0) [0.0|3] ""  Vector__XXX
 SG_ Parken_Lichtnachlauf_Anf : 39|1@1+ (1.0,0.0) [0.0|1] ""  Vector__XXX
 SG_ IPA_Akustik_PL_gefunden : 45|1@1+ (1.0,0.0) [0.0|1] ""  Vector__XXX
 SG_ Parken_Blinker_li_Anf : 46|1@1+ (1.0,0.0) [0.0|1] ""  Vector__XXX
 SG_ Parken_Blinker_re_Anf : 47|1@1+ (1.0,0.0) [0.0|1] ""  Vector__XXX
 SG_ Parken_Fahrerhinweise_Anf : 51|1@1+ (1.0,0.0) [0.0|1] ""  Vector__XXX
 SG_ Parken_Bestaetigungsblinken_Anf : 52|2@1+ (1.0,0.0) [0.0|3] ""  Vector__XXX
 SG_ Parken_Fahrbereitschaftlicht_Anf : 54|1@1+ (1.0,0.0) [0.0|1] ""  Vector__XXX
 SG_ Parken_Lichtsteuerung_Anf : 55|1@1+ (1.0,0.0) [0.0|1] ""  Vector__XXX
 SG_ IPA_Anf_Meldungen : 56|8@1+ (1.0,0.0) [0.0|255] ""  Vector__XXX

BO_ 2589283690 IPB_03: 16 Gateway_Max
 SG_ LAD_OBD_Lampe_Anf : 23|1@1+ (1.0,0.0) [0.0|1] ""  Vector__XXX
 SG_ IPB_ThermAuslastungsgrad : 24|8@1+ (1,0) [0|100] "Unit_PerCent"  Vector__XXX
 SG_ TNV_Temperatur : 32|8@1+ (1,-40) [-40|213] "Unit_PerCent"  Vector__XXX
 SG_ IPB_Wasser_TEMP_EIN : 40|8@1+ (1,-40) [-40|213] "Unit_DegreCelsi"  Vector__XXX
 SG_ IPB_Wasser_TEMP_AUS : 48|8@1+ (1,-40) [-40|213] "Unit_DegreCelsi"  Vector__XXX
 SG_ HVLE_Temperatur : 56|8@1+ (1,-40) [-40|213] "Unit_DegreCelsi"  Vector__XXX
 SG_ HVLE_ThermAuslastungsgrad : 64|8@1+ (1,0) [0|100] "Unit_PerCent"  Vector__XXX
 SG_ HVLE_eTM_max_Vorlauftemperatur : 72|8@1+ (1,-40) [-40|213] "Unit_DegreCelsi"  Vector__XXX
 SG_ OBDProtocol_Ladegeraet : 88|8@1+ (1.0,0.0) [0.0|255] ""  Vector__XXX

BO_ 2589283695 IPB_03_SOK_Signatur: 8 Gateway_Max
 SG_ SOK_IPB_03_Signatur : 0|64@1+ (1,0) [1|18446744073709551615] "Unit_None"  Vector__XXX

BO_ 1892 ISO_AGA_Req: 8 Gateway_Max
 SG_ ISO_AGA_Req_Data : 0|64@1+ (1.0,0.0) [0.0|18446744073709551615] ""  Vector__XXX

BO_ 1998 ISO_AGA_Resp: 8 Vector__XXX
 SG_ ISO_AGA_Resp_Data : 0|64@1+ (1.0,0.0) [0.0|18446744073709551615] ""  Gateway_Max

BO_ 1792 ISO_Funktionaler_Req_All: 8 Gateway_Max
 SG_ ISO_ALL_01_Req_Data : 0|64@1+ (1.0,0.0) [0.0|18446744073709551615] ""  Getriebe_DQ,Motor_konv

BO_ 1820 ISO_Soundaktor_Req: 8 Gateway_Max
 SG_ ISO_Soundaktor_Req_Data : 0|64@1+ (1.0,0.0) [0.0|18446744073709551615] ""  Vector__XXX

BO_ 1926 ISO_Soundaktor_Resp: 8 Vector__XXX
 SG_ ISO_Soundaktor_Resp_Data : 0|64@1+ (1.0,0.0) [0.0|18446744073709551615] ""  Gateway_Max

BO_ 2549874812 ISOx_EMotor_01_Req: 8 Gateway_Max
 SG_ ISOx_EMotor_01_Req_Data : 0|64@1+ (1.0,0.0) [0.0|18446744073709551615] ""  Vector__XXX

BO_ 2621440124 ISOx_EMotor_01_Req_FD: 64 Gateway_Max
 SG_ ISOx_EMotor_01_Req_FD_Data : 0|512@1+ (1.0,0.0) [0.0|13407807929942597099574024998205846127479365820592393377723561443721764030073546976801874298166903427690031858186486050853753882811946569946433649006084095] ""  Vector__XXX

BO_ 2550005884 ISOx_EMotor_01_Resp: 8 Vector__XXX
 SG_ ISOx_EMotor_01_Resp_Data : 0|64@1+ (1.0,0.0) [0.0|18446744073709551615] ""  Gateway_Max

BO_ 2621571196 ISOx_EMotor_01_Resp_FD: 64 Vector__XXX
 SG_ ISOx_EMotor_01_Resp_FD_Data : 0|512@1+ (1.0,0.0) [0.0|13407807929942597099574024998205846127479365820592393377723561443721764030073546976801874298166903427690031858186486050853753882811946569946433649006084095] ""  Gateway_Max

BO_ 2549874872 ISOx_EMotor_02_Req: 8 Gateway_Max
 SG_ ISOx_EMotor_02_Req_Data : 0|64@1+ (1.0,0.0) [0.0|18446744073709551615] ""  Vector__XXX

BO_ 2621440184 ISOx_EMotor_02_Req_FD: 64 Gateway_Max
 SG_ ISOx_EMotor_02_Req_FD_Data : 0|512@1+ (1.0,0.0) [0.0|13407807929942597099574024998205846127479365820592393377723561443721764030073546976801874298166903427690031858186486050853753882811946569946433649006084095] ""  Vector__XXX

BO_ 2550005944 ISOx_EMotor_02_Resp: 8 Vector__XXX
 SG_ ISOx_EMotor_02_Resp_Data : 0|64@1+ (1.0,0.0) [0.0|18446744073709551615] ""  Gateway_Max

BO_ 2621571256 ISOx_EMotor_02_Resp_FD: 64 Vector__XXX
 SG_ ISOx_EMotor_02_Resp_FD_Data : 0|512@1+ (1.0,0.0) [0.0|13407807929942597099574024998205846127479365820592393377723561443721764030073546976801874298166903427690031858186486050853753882811946569946433649006084095] ""  Gateway_Max

BO_ 2621505536 ISOx_Funkt_Req_All_FD: 64 Gateway_Max
 SG_ ISOx_Funkt_Req_All_FD_Data : 0|512@1+ (1.0,0.0) [0.0|13407807929942597099574024998205846127479365820592393377723561443721764030073546976801874298166903427690031858186486050853753882811946569946433649006084095] ""  Getriebe_DQ,Motor_konv

BO_ 2549874807 ISOx_Getriebe_01_Req: 8 Gateway_Max
 SG_ ISOx_Getriebe_01_Req_Data : 0|64@1+ (1.0,0.0) [0.0|18446744073709551615] ""  Getriebe_DQ

BO_ 2621440119 ISOx_Getriebe_01_Req_FD: 64 Gateway_Max
 SG_ ISOx_Getriebe_01_Req_FD_Data : 0|512@1+ (1.0,0.0) [0.0|13407807929942597099574024998205846127479365820592393377723561443721764030073546976801874298166903427690031858186486050853753882811946569946433649006084095] ""  Getriebe_DQ

BO_ 2550005879 ISOx_Getriebe_01_Resp: 8 Getriebe_DQ
 SG_ ISOx_Getriebe_01_Resp_Data : 0|64@1+ (1.0,0.0) [0.0|18446744073709551615] ""  Gateway_Max

BO_ 2621571191 ISOx_Getriebe_01_Resp_FD: 64 Getriebe_DQ
 SG_ ISOx_Getriebe_01_Resp_FD_Data : 0|512@1+ (1.0,0.0) [0.0|13407807929942597099574024998205846127479365820592393377723561443721764030073546976801874298166903427690031858186486050853753882811946569946433649006084095] ""  Gateway_Max

BO_ 2550399033 ISOx_LCU_SMH_Req: 8 Gateway_Max
 SG_ ISOx_LCU_SMH_Req_Data : 0|64@1+ (1.0,0.0) [0.0|18446744073709551615] ""  Vector__XXX

BO_ 2621702201 ISOx_LCU_SMH_Req_FD: 64 Gateway_Max
 SG_ ISOx_LCU_SMH_Req_FD_Data : 0|512@1+ (1.0,0.0) [0.0|13407807929942597099574024998205846127479365820592393377723561443721764030073546976801874298166903427690031858186486050853753882811946569946433649006084095] ""  Vector__XXX

CM_ BO_ 2527679583 "ehemals ZFAS_01";
CM_ BO_ 2621505536 "VWAG Diagnose funktionaler Request auf CANFD";

CM_ SG_ 270 GE2_Fahrstufe "Fahrprogramm des Getriebes (redundantes Signal zu Getriebe_11.GE_Fahrstufe wg. Autosar-Modellierung notwendig)

Hinweis: Zwischenstellung '0x0' darf nur für Zustandswechsel P/R, R/N, N/D ausgegeben werden, nicht für D/S oder D/Tippgasse wegen Abschaltkr";
CM_ SG_ 270 GE2_Ursache_Fahrstufe_N "Zeigt an, warum Fahrstufe N angenommen wurde. So kann z.B. die Rollsicherung im Verlassenskonzept aktiv bleiben, wenn das Schalten nach N ohne Fahrerwunsch erfolgte (z.B. Fehlerreaktion).

ACHTUNG: Das Signal darf nur ausgewertet werden, wenn GE_Fahrstu";
CM_ SG_ 270 GE_Abtriebsdrehzahl "Mittlere abtriebsseitige Getriebedrehzahl";
CM_ SG_ 270 GE_Anf_Zylabsch "GE_Anforderung_Zylinderabschaltung
Getriebe-Koordination Zylinderumschaltung TMB / VMB (Teilmotorbetrieb / Vollmotorbetrieb)";
CM_ SG_ 270 GE_Anheb_Solldrehz_Leerlauf "Anforderung einer absoluten Leerlaufdrehzahl";
CM_ SG_ 270 GE_Aufnahmemoment "Zeigt das Drehmoment, mit dem das Getriebe den Motor an der Kurbelwelle belastet = Ölpumpenmoment + Kupplung-/Wandler-Moment.

Signal soll grundsätzlich im kompletten Fahrbetrieb bedient werden; in bestimmten Situationen kann vom GSG der Wert 1022 = 'We";
CM_ SG_ 270 GE_Drehzahlmesser_Daempfung "Beim DQ-Getriebe kann die Anzeigedämpfung des Drehzahlmessers beim Schalten geändert werden.";
CM_ SG_ 270 GE_Eingangsdrehz "Wird gesendet, um das Lastschlagverhalten bei Schaltvorgängen zu verbessern.";
CM_ SG_ 270 GE_Eingangswellengradient "Gradient der Eingangswellendrehzahl, wird in der Schaltung mit Fortschritt der Drehzahlüberführung auf den Drehzahlgradienten der kommenden Eingangswelle überführt.";
CM_ SG_ 270 GE_Entkopplung_Status "Rückmeldung zu MO_Entkopplung_Sollschlupf (das MSG kann damit anfordern, den Schlupf in der Fahr-/Wandlerkupplung zu erhöhen bzw. die Reglerparameter umzuschalten, um eine stärkere Entkopplung zu erreichen, damit Rucke aus dem Antrieb nicht im Fahrzeug sp";
CM_ SG_ 270 GE_Fahrstufenwunsch "Hiermit wird ein Fahrstufenwunsch, hervorgerufen durch eine Wählhebelbetätigung des Fahrers bei gleichzeitig getretenem Bremspedal, signalisiert.";
CM_ SG_ 270 GE_Freig_Langfr_Schutzmom "Freigabeflag für das langfristige Schutzmoment für
MLB: GE_Langfr_Schutzmom
MQB: GE_Langfr_Schutzmom_02
MLBevo: GE_Langfr_Schutzmom_02 und GE_Langfr_Schutzmom_Schub
";
CM_ SG_ 270 GE_Freig_MMom_Vorhalt "Freigabe für die Anforderung einer Momentenreserve durch das Getriebe über das Signal
MLB: GE_MMom_Vorhalt
MQB/MLBevo: GE_MMom_Vorhalt_02";
CM_ SG_ 270 GE_Freigabe_Synchro "Freigabe der Signale
'GE_Synchro_Wunschdrehz' und 'GE_Synchro_Zeit'";
CM_ SG_ 270 GE_Grenzkriechmoment "Das Grenzkriechmoment ist das max. Motormoment was von der Kupplung im Fahrzeugstillstand aufgenommen werden kann um z.B. das Fgz. am Berg zu halten oder das Ankriechen zu gewährleisten.

Achtung:
Einheitenloser CAN-Wert.
Faktor in MO_Faktor_Momente i";
CM_ SG_ 270 GE_HYB_DZ_Eingriff "Freigabebedingung für Drehzahleingriff-Hybrid";
CM_ SG_ 270 GE_HYB_EM_KompMom "K0 Kompensationsmoment, vom MSG immer einzukoordinieren ohne Filterung, VZ immer positiv";
CM_ SG_ 270 GE_HYB_Fehlerstatus "Hybrid-spezifische Fehlerstati
PQ3x: Fehlerstatus x1b signalisiert, dass der Druck zum Öffnen der K0 nicht ausreicht (nach Kl15 ein)
PL71: Fehlerstatus x1b signalisiert eine unzureichende Druckversorgung durch die EOP.
Fehlerstatus 1xb : Verhinderung u";
CM_ SG_ 270 GE_HYB_Filt_MomAufbau "Faktor, der im MSG zur Berechnung der Filterkonstanten für den Fahrerwunschmomentenaufbau im Impulsstart verwendet wird.";
CM_ SG_ 270 GE_HYB_Freig_VM_EM_Stop "Signalisiert Bereitschaft GSG, dass VM gestoppt werden darf (Soft Stop) oder dass EM gestoppt werden darf (Übergang EM-Fahren => EMFahrbereitschaft)";
CM_ SG_ 270 GE_HYB_Freigabe_K0 "PQ3x: Bit ist Zwangsanforderung für Status der K0
0 = K0 auf
1 = K0 zu
PL72: Übergang von 0 nach 1 (bzw von 1 nach 0) ist Teil des Wiederstart- (Stop-) Handshakes
0 = Freigabe K0 öffnen
1 = Freigabe K0 schließen";
CM_ SG_ 270 GE_HYB_Freigabe_LL_Reg "GSG gibt hier die Aktivierung einer DZ-Regelung von VM und/oder EM frei. (Verhinderung Selbstbeschleuniger)";
CM_ SG_ 270 GE_HYB_IstStatus_K0 "Status 'offen' muss eine voll geöffnete Kupplung sicherstellen. Der Zustand 'Übergang' zeigt eine unter Kupplungsmoment stehende schlupfende K0 an.";
CM_ SG_ 270 GE_HYB_MaxMomK0 "Reduktionsstufen abh. vom Projekt zur Reduktion des VM-Momentes als K0 Schutz.";
CM_ SG_ 270 GE_HYB_nK0 "Nur PQ3x Hybrid:
GSG teilt MSG mit, auf welcher DZ die EM nach schnellem Schließen der K0 und nach DZAngleichung durch das GSG landen wird.
Wenn Signal 'Wiederstart' nicht aktiv: EM-Drehzahl wird gespiegelt.
Wenn Signal 'Wiederstart' aktiv: DZ, auf der";
CM_ SG_ 270 GE_HYB_Sportfaktor "Sportlichkeitsfaktor Getriebe, zur Verwendung in der Hybrid-Fahrstrategie
0 = nicht sportlich
1..15 = sportlich";
CM_ SG_ 270 GE_HYB_StartAnf "Auslösen des VM_Wiederstart bei EM-Betrieb";
CM_ SG_ 270 GE_HYB_VM_akt_halten "Im elektrischen Fahren/Tipp: Übergang von 0 auf 1 zeigt VM-Startanforderung des GSG an.
Empfehlung GSG an MSG, dass VM aktiv gehalten werden soll. Verwendbar z.B. bei den Funktionen 'fast off (Gang halten)' oder bei 'Rückschaltung bei Bremsen'.";
CM_ SG_ 270 GE_HYB_VM_Soll_Moment "Verbrenner-Sollmoment, auf VM-Kurbelwelle bezogen, ohne Status-Bit (Rohwert 254 = kein_Eingriff), nur gültig wenn GE_HYB_Wiederstart == 1 && GE_HYB_IstStatus_K0 == 2";
CM_ SG_ 270 GE_HYB_VM_Startkontr "Freigabe der Wiederstartkontrolle";
CM_ SG_ 270 GE_HYB_Wiederstart "Getriebe zeigt an, ob Wiederstart aktiv ist.";
CM_ SG_ 270 GE_HYB_Wiederstartreserve "Reserve an EM_Moment im MSG bereitzustellen, die für eine EM_KompMom Anforderung immer gewährleistet sein muss.";
CM_ SG_ 270 GE_Langfr_Schutzmom_02 "Konventionelle Projekte: Begrenzung des Motormoments in positiver Richtung
Hybrid-Projekte: Begrenzung des Summenmoments der Antriebsmaschinen; in MQB Begrenzung betragsmäßig sowohl in positiver als auch in negativer Richtung; in MLBevo Begrenzung nur in";
CM_ SG_ 270 GE_MMom_Soll_02 "Momenteneingriff an den Motor.
Fordert vom MSG eine kurzfristige Reduzierung oder Anhebung des Moments.
Das Signal ist nur gültig in Kombination mit GE_MMom_Status (bei MQB) bzw. GE_MMom_Status_02 (bei MLBevo).

Achtung:
Einheitenloser Wert! Faktor i";
CM_ SG_ 270 GE_MMom_Status "Qualifiziert 
MLB: GE_MMom_Soll
MQB: GE_MMom_Soll_02";
CM_ SG_ 270 GE_MMom_Status_02 "Das Signal qualifiziert GE_MMom_Soll_02 und gibt an, wie der Wert aus GE_MMom_soll – vorbehaltlich der Umsetzbarkeit aufgrund motorinterner Restriktionen – umgesetzt werden soll.
Werte:
0= kein Eingriff
1=   absoluter reduzierender Eingriff auf Gesamt ";
CM_ SG_ 270 GE_MMom_Vorhalt_02 "Anforderung einer Momentenreserve durch das Getriebe, gilt nur mit Freigabe durch 
GE_Freig_MMom_Vorhalt

Anforderung wird als Absolut-Wert umgesetzt, nicht als Relativ-Wert/Delta zum aktuellen Ist-Moment (d. h. eine Momentenreserve wird eingestellt, w";
CM_ SG_ 270 GE_Mom_Begr_Gradient "255 =  keine Begrenzung (Initwert)

Mit diesem Signal fordert das GSG vom MSG  im positiven Momentenbereich (Getriebeeingangs- / Motorausgangsmoment > 0 Nm) Momenten-Erhöhungen aufgrund Fahrerwunsch-Änderungen im Gradient zu begrenzen.
(Änderungen aufg";
CM_ SG_ 270 GE_Notlauf "AL/DL: Signalisiert wenn sich das Getriebe (bei DL ein Teilgetriebe) im Notlauf befindet.
VL: Wird gesetzt wenn kein Kraftschluss möglich ist.";
CM_ SG_ 270 GE_Radmoment "Radmoment vom Getriebe";
CM_ SG_ 270 GE_Schaltablauf "Das Signal zeigt den aktuellen Status eines Schaltvorgangs.

Bei Signal = 0 liegt kein Schaltvorgang vor.
Bei Signal =2 liegt die Befüllphase der zuschaltenden Kupplung bzw. 
                      die Vorbereitungsphase dazu vor.

Mit den unterschie";
CM_ SG_ 270 GE_Schubabschalt_Unt "Signalisiert wenn aus der Sicht des Getriebes eine Schubabschaltung des Motors möglich ist. Bei aktiver Schubabschalt-Unterstützung wird sicher gestellt, dass die Kupplung nicht schlagartig geöffnet wird";
CM_ SG_ 270 GE_StartStopp_Info "Stopp-Freigabe und Start-Anforderung an den Start-Stopp-Koordinator";
CM_ SG_ 270 GE_Status_Kraftschluss "Zeigt den Ist-Status des Kraftschlusses im Getriebe.
(Anmerkung: meist wird damit der Zustand des Anfahrelements beschrieben, d.h. bei DL/DQ die Kupplung;  bei AQ/AL der Wandler incl. Überbrückungskupplung)
0 = offen, kein Kraftschluss
1 = offen mit Kr";
CM_ SG_ 270 GE_Synchro_Status_02 "Das Signal qualifiziert GE_Synchro_Wunschdrehz_02 und gibt an, wie GE_Synchro_Wunschdrehz_02 umgesetzt werden soll.

Werte:
0 - Kein Eingriff
1...4 - Drehzahleingriff wirkt auf Gesamtantrieb (MSG: Verwendung Param.Satz 1...4)
5 - Drehzahleingriff wir";
CM_ SG_ 270 GE_Synchro_Wunschdrehz "Wunschdrehzahl für Verbrennungsmotor bzw. E-Motor; Freigabe durch GE_Freigabe_Synchro (bei MLB und MQB), Freigabe und Steuerung durch GE_Synchro_Status (bei MLBevo).
Wenn kein Eingriff angefordert wird, soll Init = 0 = 0x0 gesendet werden.";
CM_ SG_ 270 GE_Synchro_Zeit "Signalisiert wie schnell die Wunschdrehzahl bei einem Synchronisations-Wunschdrehzahl-Eingriff aufgebaut werden soll. Die Zeitvorgabe 0x0 bedeutet so schnell wie möglich. Die geforderte Synchronisationszeit bleibt bis zum Abbruch oder erreichen der Zeit k";
CM_ SG_ 270 GE_Uefkt "Übertragungsfunktion des Getriebes
Drehzahlverhältnis = Eingangsdrehzahl / Ausgangsdrehzahl

AL: Wandlerverstärkung x Drehzahlverhältnis
VL: Drehzahlverhältnis
DL: Drehzahlverhältnis der aktiven und kraftschluß führenden Welle zum Abtrieb, bei Schalt";
CM_ SG_ 270 GE_Uefkt_unplausibel "Das Signal darf nur im Reku-Manager in Hybrid-Varianten verwendet werden.
Zeigt an, ob die Plausibilisierung Momenten-Verhältnis zu Drehzahl-Verhältnis i.O. ist.
Ein gesetztes Signal meldet eine unplausible GE_Uefkt bzw. GE_Uefkt_02.";
CM_ SG_ 270 GE_Verbot_Ausblendung "Verbot Einspritzausblendung für komfortable Schaltungen";
CM_ SG_ 270 GE_Verlustmoment "Achtung einheitenloser Wert !!
	Faktor in MO_Faktor_Momente (MLB) bzw. MO_Faktor_Momente_02 (MQB/MLBevo) in Motor_Code_01 beachten!

ab MQB/MLBevo:
	Das Signal enthält die berechneten Momentenverluste, welche innerhalb des Getriebegehäuses entstehen (";
CM_ SG_ 270 GE_Zielgang "VL-Getriebe:
Signalisiert den Zielgang im manuellen Modus während eines Schaltvorgangs bzw. die momentane simulierte Gangstufe wenn kein Schaltvorgang aktiv ist. In den Fahrprogrammen 'D' und 'S' ist die Übersetzung variabel und somit wird dauerhaft 'Ist";
CM_ SG_ 270 Getriebe_50_BZ "4bit Botschaftszähler, wird mit jeder Sendebotschaft inkrementiert";
CM_ SG_ 270 Getriebe_50_CRC "Für MLB:
Berechnung siehe Lastenheft 'Kommunikationsabsicherung für FlexRay und CAN'
Ab MQB und MLBevo:
Berechnung siehe Lastenheft 'End-to-End Kommunikationsabsicherung'

Endwerte siehe Begleitdokument 'S-PDU Kennungsfolgen'";

CM_ SG_ 509 Freilauf_Charisma_FahrPr "MLBevo: Aktuelles Fahrprogramm des Charisma-Teilnehmers (siehe Systemlastenheft Drive Select)
MQB: Istwert der Kennlinie (siehe Systemlastenheft MQB FPA)";
CM_ SG_ 509 Freilauf_Charisma_Status "Charisma Systemstatus des Charisma-Teilnehmers

Wert 0x3 ist nur für Fahrzeuge ab MQB relevant";
CM_ SG_ 509 FSA_Fehlerstatus_Parksperre "Fahrstufenauswahl: Signalisierung Funktionseinschränkung bzw. Defekt der Parksperre";
CM_ SG_ 509 GE_amax_moeglich "AL/DL: maximal mögliche Beschleunigung unter Berücksichtigung aller möglichen Gänge.

Eine Reduzierung des maximalen Motormoments durch Efficiency wird in dem Signal berücksichtigt.

VL: maximal mögliche Beschleunigung bei Nenndrehzahl (Efficency wird";
CM_ SG_ 509 GE_Anforderung_HMS "Anforderung an dem Haltemanager vom Automatikgetriebe";
CM_ SG_ 509 GE_Anschleppstart_Freigabe "Bilden einer Schleppstartfreigabe aus Fahrdynamiksicht. Schleppstartabbruch bei kritischer Fahrzeugstabilität";
CM_ SG_ 509 GE_Betaetigung_Hold "Anforderung des Getriebes zum Aktivieren der Holdfunktion 
";
CM_ SG_ 509 GE_Charisma_FahrPr "MLBevo: Aktuelles Fahrprogramm des Charisma-Teilnehmers (siehe Systemlastenheft Drive Select)
MQB: Istwert der Kennlinie (siehe Systemlastenheft MQB FPA)";
CM_ SG_ 509 GE_Charisma_Status "Charisma Systemstatus des Charisma-Teilnehmers

Wert 0x3 ist nur für Fahrzeuge ab MQB relevant";
CM_ SG_ 509 GE_Codierung_MSG "Statusausgabe der Diagnose für Falschverbau. Plausibilisierung der empfangenen Motor- und Getriebevariante mit der erwarteten Motor- und Getriebevarianten.";
CM_ SG_ 509 GE_Fahrprogramm "Signalisiert das Fahrprogramm  im Bezug auf
die Fahrstufe des Getriebes.

Audi/MQB:
Offroad

Bentley:
Snow
Gravel
Mud_Ruts
Sand_Dune

Touareg:
Offroad
Snow";
CM_ SG_ 509 GE_Freigabe_Info_WFS "WFS-Freigabeinformation";
CM_ SG_ 509 GE_Freigabe_Verfallsinfo_WFS "WFS";
CM_ SG_ 509 GE_Freilauf_Status "Freilauf-Status-Signal vom Frailauf-Master an aktive Freilauf-Teilnehmer. In diesem Signal zeigt der Freilauf-Master an, welchen aktuellen Status die Freilauf-Betriebsstrategie hat.";
CM_ SG_ 509 GE_Grundeinstell_Drehrichtung_EM "Anforderung des Getriebes, die E-Maschine während der Grundeinstellung rückwärts zu drehen.

ACHTUNG! Das Signal ist nur auszuwerten, wenn GE_Grundeinstellung == 1. Das Signal wird vom Getriebe nur in Fahrstufe P gesetzt.";
CM_ SG_ 509 GE_Grundeinstellung "Grundeinstellung des Getriebes ist aktiv

Hinweis:
Verwendung nur im MQB";
CM_ SG_ 509 GE_LaunchControl "Während einer LaunchControl-Anfahrt sendet das Getriebesteuergerät das Bit LaunchControl aktiv.
Die Bremse wertet dieses Bit aus, um während einer solchen Anfahrt die Regelgrenzen der Schlupfregelung zu erweitern.
Im Motor Nutzung zur Verbesserung des A";
CM_ SG_ 509 GE_LFR_Adaption "Qualifiziert das ausgegeben Motorbelastungsmoment (durch GE_Vorsteuermoment) für die Verwendung zur LFR (Leerlauffüllungsregelung) im Moto";
CM_ SG_ 509 GE_OBD_AbsperrVent "Das Getriebesteuergerät führt eine elektrische Diagnose des von ihm angesteuerten Absperrventils für den Öl-Wasser-Wärmetauscher durch und übermittelt das Ergebnis an das MSG (Standard-4Bit-OBD-Status, nicht alle Zustände müssen genutzt werden; so sind z.";
CM_ SG_ 509 GE_OBD_Status "Dieses Bit steuert die MIL-Lampe an (Motorsteuergerät reicht diese Info an Kombi weiter).";
CM_ SG_ 509 GE_Parken_beibehalten_HMS "Anforderung seitens Parksperrenmaster (GSG/ASG), das Lösen der Parkbremse zu verhindern.";
CM_ SG_ 509 GE_Parken_WFS_Status "Rückmeldung des Status der angeforderten erneuten Authentifikation durch ZFAS";
CM_ SG_ 509 GE_QBit_Sumpftemperatur "Qualifizierungs-Bit für GE_Sumpftemperatur, gesetzt bei Ersatzwert, Init oder Fehler.";
CM_ SG_ 509 GE_Schleuderoeltemperatur "Die Temperatur des Schleuderöls durch die K0 wird vom Getriebe modelliert. 
Das Schleuderöl aus der K0 trifft beim DQ400e von innen auf den Rotor der E-Maschine und sorgt für eine Erwärmung/Kühlung des Rotors.";
CM_ SG_ 509 GE_SpannungsAnf "Forderung des GSGs zur Spannungsanhebung.";
CM_ SG_ 509 GE_Sperr_Info_WFS "WFS-Sperrinformation";
CM_ SG_ 509 GE_Strombedarf_erh "Das GSG teilt dem MSG einen aufgrund der Kühlung erhöhten Strombedarf mit, damit gleichzeitig die Kühler-Lüfter-Ansteuerung kurzzeitig reduziert wird.

Signal wird bisher nur im MQB-PHEV verwendet.";
CM_ SG_ 509 GE_Sumpftemperatur "Getriebesumpftemperatur wird über den Temperatursensor auf der Getriebeplatine ermittelt. Die absolute Sumpftemperatur wird vom Motor empfangen, um entsprechende Kühlleistung für das Getriebe einzustellen.";
CM_ SG_ 509 GE_TippZustand "Zeigt den Tippzustand in eine Fahrstufe und ein Fahrprogramm via Paddles oder Schaltbetätigung an.
Das Signal ist gültig in Kombination mit GE_Fahrstufe und GE_Fahrprogramm.

MLBevo:
DL und AL: nur Tipp_in_permanent
PDK2: Tipp_in_temporaer und Tipp_i";
CM_ SG_ 509 GE_Veto_Rollfaehigkeit "Der Schaltbetätigungsmaster kann mit diesem Signal die Rollfähigkeit bei Zündung aus ('N-Haltephase'/'Waschstraßenfunktion') situationsabhängig verhindern, z.B. bei einem Defekt der P-Taste.";
CM_ SG_ 509 GE_Weckleitung_aktiv "Rückmeldung an Motor, dass Weckleitung aktiv";
CM_ SG_ 509 GE_Zustand_Kuppltemp "Dieses Signal gibt den Temperaturzustand der Kupplung im DQ-Getriebe (z. Zt. DQ2x0, DQ500) an das ACC-System.";
CM_ SG_ 509 Getriebe_51_BZ "4bit Botschaftszähler, wird mit jeder Sendebotschaft inkrementiert";
CM_ SG_ 509 Getriebe_51_CRC "Für MLB:
Berechnung siehe Lastenheft 'Kommunikationsabsicherung für FlexRay und CAN'
Ab MQB und MLBevo:
Berechnung siehe Lastenheft 'End-to-End Kommunikationsabsicherung'

Endwerte siehe Begleitdokument 'S-PDU Kennungsfolgen'";

CM_ SG_ 2589283964 GE_Indc_StChk "'Test Not Completed This Operation Cycle' (TNCTOC)-Information zur  Inducement-Anforderung von GE";
CM_ SG_ 2589283964 GE_Indc_StFail "'Test Failed' (TF)-Information zur Inducement-Anforderung von GE";
CM_ SG_ 2589283964 GE_OBD_Status_Auth "Ansteuerung der MIL-Lampe über den MIL-Master (Motorsteuergerät)
Redundantes Signal (SOK gesichert) zu GE_OBD_Status";
CM_ SG_ 2589283964 SOK_Getriebe_52_Signatur "Signatur im Rahmen der durch SOK geschützen Broadcast-Kommunikation

Geschützte Funktion: OBD-Malfunction Indicator Light (MIL)
Geschützte PDU: Getriebe_52";

CM_ SG_ 299 GRA_Abbrechen "GRA : aus mit speichern
ACC : Soft aus";
CM_ SG_ 299 GRA_ACC_01_BZ "4bit Botschaftszaehler, wird mit jeder Sendebotschaft inkrementiert";
CM_ SG_ 299 GRA_ACC_01_CRC "Für MLB:
'Berechnung siehe Lastenheft 'Kommunikationsabsicherung für FlexRay und CAN''

Ab MQB und MLBevo:
'Berechnung siehe Lastenheft 'End-to-End Kommunikationsabsicherung''

Endwerte siehe Begleitdokument 'S-PDU Kennungsfolgen'";
CM_ SG_ 299 GRA_Codierung "Das Signal zeigt an, ob das Sende-SG (SMLS/MFL) auf GRA- oder ACC-Bedienteil codiert ist:
0: kein GRA- oder ACC Bedienteil
1: GRA-Bedienteil
2: ACC-Bedienteil
3: Limiter_Only-Bedienteil";
CM_ SG_ 299 GRA_Fehler "Das Signal zeigt an, dass das Sende-SG (SMLS/MFG) einen Defekt des GRA-Bedienteils erkannt hat und hierzu ein FSPE abgelegt wurde.";
CM_ SG_ 299 GRA_Hauptschalter "Stellung des GRA/ACC-Hauptschalters: 
Bei gerastetem Hauptschalter:
0: Hauptschalter aus
1: Hauptschalter ein
Bei getastetem Hauptschalter:
0: Taster nicht betätigt
1: Taster betätigt";
CM_ SG_ 299 GRA_LIM_Taste_verfuegbar "Das Signal zeigt an, ob eine Limiter-Umschalttaste am jeweiligen GRA/ACC-Bedienelement vorhanden ist.";
CM_ SG_ 299 GRA_Limiter "Stellung des Limiter-Tasters";
CM_ SG_ 299 GRA_PIT_Limiter "Stellung der Taste PIT-Speed-Limiter";
CM_ SG_ 299 GRA_reserveByte5 "Zweck: Befüllen der reservierten Bitpositionen mit 0 (wg. LIN-Teilnehmer MFL)";
CM_ SG_ 299 GRA_reserveByte6 "Zweck: Befüllen der reservierten Bitpositionen mit 0 (wg. LIN-Teilnehmer MFL)";
CM_ SG_ 299 GRA_reserveByte7 "Zweck: Befüllen der reservierten Bitpositionen mit 0 (wg. LIN-Teilnehmer MFL)";
CM_ SG_ 299 GRA_reserveByte8 "Zweck: Befüllen der reservierten Bitpositionen mit 0 (wg. LIN-Teilnehmer MFL)";
CM_ SG_ 299 GRA_Tip_Hoch "Tippschalter Tip Up / Geschwindigkeit erhöhen";
CM_ SG_ 299 GRA_Tip_Runter "Tippschalter Tip Down / Geschwindigkeit reduzieren";
CM_ SG_ 299 GRA_Tip_Setzen "Tippschalter Set";
CM_ SG_ 299 GRA_Tip_Stufe_2 "Signal zeigt an, dass der zweistufige GRA/ACC-Hebel (8_Positions_Bedienteil) in der 2. Tip-Stufe betätigt wird. Das Signal wird nur gleichzeitig mit dem Signal GRA_Tip_Hoch oder GRA_Tip_Runter gesetzt, wobei die Bits GRA_Tip_Hoch bzw. GRA_Tip_Runter die R";
CM_ SG_ 299 GRA_Tip_Wiederaufnahme "Tippschalter Wiederaufnahme";
CM_ SG_ 299 GRA_TravelAssist "Taste für TravelAssist";
CM_ SG_ 299 GRA_Typ_Bedienteil "Das Signal kennzeichnet die Variante des GRA/ACC-Bedienteils:
0: Init
1: 4-Positionen-Bedienteil (z.B. GRA im Blinkerhebel)
2: 6-Positionen-Bedienteil (GRA/ACC-Bedienteil mit separaten Stellungen für Set/Resume/TipUp/TipDown) 
3: 8-Positionen-Bediente";
CM_ SG_ 299 GRA_Typ_Hauptschalter "Variante des GRA/ACC-Hauptschalters:
0: gerasteter Hauptschalter (bzw. Taster mit Speicherung des Status im SMLS (PAG))
1: getasteter Hauptschalter, keine Speicherung des Status im SMLS";
CM_ SG_ 299 GRA_Verstellung_Zeitluecke "Verstellung der Zeitlücke für ACC

DIST -1 = Zeitluecke um 1 Stufe kleiner
DIST +1 = Zeitluecke um 1 Stufe groeßer
DIST Toggle = Zeitlücke um 1 Stufe kleiner, von kleinster Stufe auf größte Stufe";

CM_ SG_ 2589283397 GW_CAL_ID_Index_01 "CAL-ID ASCII-Zeichen";
CM_ SG_ 2589283397 GW_CAL_ID_Index_02 "CAL-ID ASCII-Zeichen";
CM_ SG_ 2589283397 GW_CAL_ID_Index_03 "CAL-ID ASCII-Zeichen";
CM_ SG_ 2589283397 GW_CAL_ID_Index_04 "CAL-ID ASCII-Zeichen";
CM_ SG_ 2589283397 GW_CAL_ID_Index_05 "CAL-ID ASCII-Zeichen";
CM_ SG_ 2589283397 GW_CAL_ID_Index_06 "CAL-ID ASCII-Zeichen";
CM_ SG_ 2589283397 GW_CAL_ID_Index_07 "CAL-ID ASCII-Zeichen";
CM_ SG_ 2589283397 GW_CAL_ID_Index_08 "CAL-ID ASCII-Zeichen";
CM_ SG_ 2589283397 GW_CAL_ID_Index_09 "CAL-ID ASCII-Zeichen";
CM_ SG_ 2589283397 GW_CAL_ID_Index_10 "CAL-ID ASCII-Zeichen";
CM_ SG_ 2589283397 GW_CAL_ID_Index_11 "CAL-ID ASCII-Zeichen";
CM_ SG_ 2589283397 GW_CAL_ID_Index_12 "CAL-ID ASCII-Zeichen";
CM_ SG_ 2589283397 GW_CAL_ID_Index_13 "CAL-ID ASCII-Zeichen";
CM_ SG_ 2589283397 GW_CAL_ID_Index_14 "CAL-ID ASCII-Zeichen";
CM_ SG_ 2589283397 GW_CAL_ID_Index_15 "CAL-ID ASCII-Zeichen";
CM_ SG_ 2589283397 GW_CAL_ID_Index_16 "CAL-ID ASCII-Zeichen";
CM_ SG_ 2589283397 GW_CVN "OBD-CVN (Checksumme gemäß OBD-Anforderungen)";
CM_ SG_ 2589283397 GW_CVN_VLD "Valid-Bit der Calibration-Verification-Number (CVN bzw. Checksumme)";
CM_ SG_ 2589283397 GW_KomponentenFehler_01 "MLBevo: 
GW_Komponetenfehler (EEPROM, ROM, RAM, WD)

MQB2020: 
GW_Komponentenfehler_01";
CM_ SG_ 2589283397 GW_Komponentenfehler_02 "MQB2020: 
GW_Komponentenfehler_02";
CM_ SG_ 2589283397 GW_Komponentenfehler_03 "MQB2020: 
GW_Komponentenfehler_03";
CM_ SG_ 2589283397 GW_Komponentenfehler_04 "MQB2020: 
GW_Komponentenfehler_04";
CM_ SG_ 2589283397 GW_Komponentenfehler_05 "MQB2020: 
GW_Komponentenfehler_05";
CM_ SG_ 2589283397 GW_Komponentenfehler_06 "MQB2020: 
GW_Komponentenfehler_06";
CM_ SG_ 2589283397 GW_Komponentenfehler_07 "MQB2020: 
GW_Komponentenfehler_07";
CM_ SG_ 2589283397 GW_Komponentenfehler_08 "MQB2020: 
GW_Komponentenfehler_08";
CM_ SG_ 2589283397 GW_Komponentenfehler_09 "MQB2020: 
GW_Komponentenfehler_09";
CM_ SG_ 2589283397 GW_Komponentenfehler_10 "MQB2020: 
GW_Komponentenfehler_10";
CM_ SG_ 2589283397 GW_Komponentenfehler_11 "MQB2020: 
GW_Komponentenfehler_11";
CM_ SG_ 2589283397 GW_Komponentenfehler_12 "MQB2020: 
GW_Komponentenfehler_12";
CM_ SG_ 2589283397 GW_Komponentenfehler_13 "MQB2020: 
GW_Komponentenfehler_13";
CM_ SG_ 2589283397 GW_Komponentenfehler_14 "MQB2020: 
GW_Komponentenfehler_14";
CM_ SG_ 2589283397 GW_Komponentenfehler_15 "MQB2020: 
GW_Komponentenfehler_15";
CM_ SG_ 2589283397 GW_Komponentenfehler_16 "MQB2020: 
GW_Komponentenfehler_16";
CM_ SG_ 2589283397 GW_Komponentenfehler_17 "MQB2020: 
GW_Komponentenfehler_17";
CM_ SG_ 2589283397 GW_Komponentenfehler_18 "MQB2020: 
GW_Komponentenfehler_18";
CM_ SG_ 2589283397 GW_Komponentenfehler_19 "MQB2020: 
GW_Komponentenfehler_19";
CM_ SG_ 2589283397 GW_Komponentenfehler_20 "MQB2020: 
GW_Komponentenfehler_20";
CM_ SG_ 2589283397 GW_Komponentenfehler_21 "MQB2020: 
GW_Komponentenfehler_21";
CM_ SG_ 2589283397 GW_Komponentenfehler_22 "MQB2020: 
GW_Komponentenfehler_22";
CM_ SG_ 2589283397 GW_Komponentenfehler_23 "MQB2020: 
GW_Komponentenfehler_23";
CM_ SG_ 2589283397 GW_Komponentenfehler_24 "MQB2020: 
GW_Komponentenfehler_24";
CM_ SG_ 2589283397 GW_Komponentenfehler_25 "MQB2020: 
GW_Komponentenfehler_25";
CM_ SG_ 2589283397 GW_Komponentenfehler_26 "MQB2020: 
GW_Komponentenfehler_26";
CM_ SG_ 2589283397 GW_Komponentenfehler_27 "MQB2020: 
GW_Komponentenfehler_27";
CM_ SG_ 2589283397 GW_Komponentenfehler_28 "MQB2020: 
GW_Komponentenfehler_28";
CM_ SG_ 2589283397 GW_Komponentenfehler_29 "MQB2020: 
GW_Komponentenfehler_29";
CM_ SG_ 2589283397 GW_Komponentenfehler_30 "MQB2020: 
GW_Komponentenfehler_30";
CM_ SG_ 2589283397 GW_Komponentenfehler_31 "MQB2020: 
GW_Komponentenfehler_31";
CM_ SG_ 2589283397 GW_Komponentenfehler_32 "MQB2020: 
GW_Komponentenfehler_32";
CM_ SG_ 2589283397 GW_Komponentenfehler_33 "MQB2020: 
GW_Komponentenfehler_33";
CM_ SG_ 2589283397 GW_Komponentenfehler_34 "MQB2020: 
GW_Komponentenfehler_34";
CM_ SG_ 2589283397 GW_Komponentenfehler_35 "MQB2020: 
GW_Komponentenfehler_35";
CM_ SG_ 2589283397 GW_Komponentenfehler_36 "MQB2020: 
GW_Komponentenfehler_36";
CM_ SG_ 2589283397 GW_Komponentenfehler_37 "MQB2020: 
GW_Komponentenfehler_37";
CM_ SG_ 2589283397 GW_Komponentenfehler_38 "MQB2020: 
GW_Komponentenfehler_38";
CM_ SG_ 2589283397 GW_Komponentenfehler_39 "MQB2020: 
GW_Komponentenfehler_39";
CM_ SG_ 2589283397 GW_Komponentenfehler_40 "MQB2020: 
GW_Komponentenfehler_40";
CM_ SG_ 2589283397 GW_Komponentenfehler_41 "MQB2020: 
GW_Komponentenfehler_41";
CM_ SG_ 2589283397 GW_Komponentenfehler_42 "MQB2020: 
GW_Komponentenfehler_42";
CM_ SG_ 2589283397 GW_Komponentenfehler_43 "MQB2020: 
GW_Komponentenfehler_43";
CM_ SG_ 2589283397 GW_Komponentenfehler_44 "MQB2020: 
GW_Komponentenfehler_44";
CM_ SG_ 2589283397 GW_Komponentenfehler_45 "MQBw_Baseline: 
GW_Komponentenfehler_45";
CM_ SG_ 2589283397 GW_Komponentenfehler_46 "MQBw_Baseline: 
GW_Komponentenfehler_46";
CM_ SG_ 2589283397 GW_Komponentenfehler_47 "MQBw_Baseline: 
GW_Komponentenfehler_47";
CM_ SG_ 2589283397 GW_Komponentenfehler_VLD "Valid-Bit der OBD-Komponentenfehler. Das Bit wird beim Fehlerspeicher löschen zurückgenommen und erst wieder gesetzt, wenn der Fehlerspeicher vollständig gelöscht wurde. Der Primary-OBD-ECU soll damit mitgeteilt werden, ob sie den Inhalten der Komponenten";

CM_ SG_ 2589283454 SOK_GW_CVN_Komp_02_Signatur "Signatur im Rahmen der durch SOK geschützen Broadcast-Kommunikation

Geschützte Funktion: OBD-Malfunction Indicator Light (MIL)
Geschützte PDU: GW_CVN_Komponentenfehler_02";

CM_ SG_ 2589284072 GW_Komponentenfehler_48 "MQBw_Baseline: 
GW_Komponentenfehler_48";
CM_ SG_ 2589284072 GW_Komponentenfehler_49 "MQBw_Baseline: 
GW_Komponentenfehler_49";
CM_ SG_ 2589284072 GW_Komponentenfehler_50 "MQBw_Baseline: 
GW_Komponentenfehler_50";
CM_ SG_ 2589284072 GW_Komponentenfehler_51 "MQBw_Baseline: 
GW_Komponentenfehler_51";
CM_ SG_ 2589284072 GW_Komponentenfehler_52 "MQBw_Baseline: 
GW_Komponentenfehler_52";
CM_ SG_ 2589284072 GW_Komponentenfehler_53 "MQBw_Baseline: 
GW_Komponentenfehler_53";
CM_ SG_ 2589284072 GW_Komponentenfehler_54 "MQBw_Baseline: 
GW_Komponentenfehler_54";
CM_ SG_ 2589284072 GW_Komponentenfehler_55 "MQBw_Baseline: 
GW_Komponentenfehler_55";
CM_ SG_ 2589284072 GW_Komponentenfehler_56 "MQBw_Baseline: 
GW_Komponentenfehler_56";
CM_ SG_ 2589284072 GW_Komponentenfehler_57 "MQBw_Baseline: 
GW_Komponentenfehler_57";
CM_ SG_ 2589284072 GW_Komponentenfehler_58 "MQBw_Baseline: 
GW_Komponentenfehler_58";
CM_ SG_ 2589284072 GW_Komponentenfehler_59 "MQBw_Baseline: 
GW_Komponentenfehler_59";
CM_ SG_ 2589284072 GW_Komponentenfehler_60 "MQBw_Baseline: 
GW_Komponentenfehler_60";
CM_ SG_ 2589284072 GW_Komponentenfehler_61 "MQBw_Baseline: 
GW_Komponentenfehler_61";
CM_ SG_ 2589284072 GW_Komponentenfehler_62 "MQBw_Baseline: 
GW_Komponentenfehler_62";
CM_ SG_ 2589284072 GW_Komponentenfehler_63 "MQBw_Baseline: 
GW_Komponentenfehler_63";
CM_ SG_ 2589284072 GW_Komponentenfehler_64 "MQBw_Baseline: 
GW_Komponentenfehler_64";
CM_ SG_ 2589284072 SOK_GW_CVN_Komp_03_Signatur "Signatur im Rahmen der durch SOK geschützen Broadcast-Kommunikation

Geschützte Funktion: OBD-Malfunction Indicator Light (MIL)
Geschützte PDU: GW_CVN_Komponentenfehler_03";

CM_ SG_ 1452 HVEM_Energie_Klima_Vorgabe "HVEM-Energievorgabe für Klima-Vorkonditionierung";
CM_ SG_ 1452 HVEM_Energie_Klima_Vorgabe_HighR "Erweiterte Auflösung von 10Wh für Signal HVEM_Energie_Klima_Vorgabe.
Signalwert wird zu HVEM_Energie_Klima_Vorgabe Addiert";
CM_ SG_ 1452 HVEM_HV_Anf "HV Anforderung des HV Energiemanagements an das MSG";
CM_ SG_ 1452 HVEM_HVK_Aktivitaet "Dem HVEM sind HV-Komponenten zugeordnet.  Das HVEM übermittelt an den HVK ein 
Hochvolt –Aktivitätsstatus dieser HV-Komponenten.";
CM_ SG_ 1452 HVEM_IstLeistungNA "aktuelle Leistungsaufnahme der Nebenaggregate";
CM_ SG_ 1452 HVEM_IstStrom_HVVerbraucher "Iststromaufnahme der elektrischen Nebenaggregate aus dem HV Zwischenkreis";
CM_ SG_ 1452 HVEM_Leistung_Klima_Vorgabe "Leistungsvorgabe Thermo (für Kühlen und Heizen)";
CM_ SG_ 1452 HVEM_MO_MaxLeistungIgnoriert "Rueckmeldung des HVEM ob die vorgegebene MaxLeistung vom MSG eingehalten wird.";
CM_ SG_ 1452 HVEM_Nutzbare_Energie "Nutzbare Energie welche für Komfortfunktionen vom HVEM freigegeben wird.";
CM_ SG_ 1452 HVEM_NVEM_Leistungsvorgabe "Leistungsvorgabe des HVEM an das NVEM";
CM_ SG_ 1452 HVEM_Pruefpuls_Anf "Prüfpulsanforderung an den HV-Koordinator";

CM_ SG_ 1385 HVEM_Abschaltstatus "Status der Reduzierungsstufen der Klimakomponenten beim Laden

0 = 100% (keine Reduzierung)
1 = 75%
2 = 50%
3 = 25%
7 = Init";
CM_ SG_ 1385 HVEM_Anf_ReichweiteNV "Anforderung an NV-EM zur Erhöhung der Reichweite den Energieverbrauch auf der NV-Seite zu reduzieren.";
CM_ SG_ 1385 HVEM_Betriebsart "Information über die seitens HVEM aktive Betriebsart für die Leistungsverteilung";
CM_ SG_ 1385 HVEM_DCDC_Freigabe "Freigabe des DCDC wenn das Fzg nicht Fahrbereit ist.";
CM_ SG_ 1385 HVEM_FreigabeBattHeizung "Freigabe des HVEM für die Batterieheizung";
CM_ SG_ 1385 HVEM_FreigabeKlimatisierung "Klimatisierung freigeben";
CM_ SG_ 1385 HVEM_KlimaMaxHVStrom "Kommuniziert dem Klimasteuergerät den max. Aufnahmestrom";
CM_ SG_ 1385 HVEM_Ladesteckerentr_Anf "Anforderung Ladestecker entriegeln nach ZV Auf Befehl";
CM_ SG_ 1385 HVEM_Leistung_Bat_Kond_Vorgabe "elektr. Leistungsvorgabe Thermo Batterie";
CM_ SG_ 1385 HVEM_LeistungsAnf "Anforderung an NV-EM zur Erhöhung der Performance den Energieverbrauch auf der NV-Seite zu reduzieren.";
CM_ SG_ 1385 HVEM_MinLeistungNA_Anf "Leistungsanforderung des HVEM in Richtung Antrieb. Diese Leistung muss der Antrieb für hochpriorisierte HV-Funktionen vorhalten.";
CM_ SG_ 1385 HVEM_Nachlad_Status "Status der Umsetzung der Nachladeanforderung der NV-Seite.";
CM_ SG_ 1385 HVEM_Nachladen_Anf "Anforderung für HV Laden bei gestecktem Stecker und deaktivierter Ladeanforderung";
CM_ SG_ 1385 HVEM_NVLeistungEmpf "Maximaler Sollwert der aktuellen Leistung der NV-Seite des DCDC-Wandlers.";
CM_ SG_ 1385 HVEM_Text_1 "Meldung bei einem Anzeige SOC<10% ('Achtung Batterie laden. Funktionen eingeschränkt')";
CM_ SG_ 1385 HVEM_WunschLeistungNA_Anf "Niederpriorisierte Leistungsanforderung an das Antriebssystem.
Diese Wunsch-Leistung ist immer größer gleich der geforderten Min-Leistung.";
CM_ SG_ 1385 HVEM_ZusatzMinLeistungNA_Anf "Zusätzliche Leistungsanfrage des HVEM an das Antriebsystem in kritischen Energiezuständen für hoch priorisierte Systemanforderungen während der Fahrbereitschaft.";

CM_ SG_ 1283 HV_Bordnetz_aktiv "Signalisiert ein aktives Hochvoltbordnetz. Für die Belastbarkeit des HV-Netzes müssen Strom- bzw. Leistungsgrenzen eingehalten werden";
CM_ SG_ 1283 HV_Bordnetz_Fehler "Status ob im  HV-Netz ein Fehler detektiert wurde.";
CM_ SG_ 1283 HVK_01_CRC "Für MLB:
'Berechnung siehe Lastenheft 'Kommunikationsabsicherung für FlexRay und CAN''

Ab MQB und MLBevo:
'Berechnung siehe Lastenheft 'End-to-End Kommunikationsabsicherung''

Endwerte siehe Begleitdokument 'S-PDU Kennungsfolgen'";
CM_ SG_ 1283 HVK_AktiveEntladung_Anf "Anforderung zum aktiven Entladen des HV-Netzes, während der Abschaltung des HV-Netz.";
CM_ SG_ 1283 HVK_BMS_Sollmodus "Angeforderter Sollmodus der HV-Batterie:
0 : HV_Off                                
1 : HV_On (HS geschlossen)                
2 : nicht belegbar                        
3 : AC-Laden_erw (HS +AC_2-Schütze geschlossen)                         
4 : AC-";
CM_ SG_ 1283 HVK_DCDC_Sollmodus "angeforderte Soll-Betriebsart des DC/DC-Wandlers: 
0: Standby; Kommunikation aktiv
1: Zwischenkreis des HV-Netzes wird vorgeladen; HV-Netz wird aktiviert und darf nicht  
    belastet werden.
2: Tiefsetzen (HV --> BN 14,4V)
    Sollwertvorgabe projek";
CM_ SG_ 1283 HVK_EKK_Sollmodus "Sollmodus elektrischer Klimakompressor";
CM_ SG_ 1283 HVK_Gesamtst_Spgfreiheit "Status des HV-Systems";
CM_ SG_ 1283 HVK_HV_Netz_Warnungen "Anforderung Warnung/Fehler HV-System im Kombi
0: Keine Warnung/Init
1:Anforderung_Anzeige_Warnung_HV-Netz (gelbes Symbol)
2:Anforderung_Anzeige_Fehler_HV-Netz (rotes Symbol)
3:Anforderung_Anzeige_Warnung_Kein_Wiederstart_möglich";
CM_ SG_ 1283 HVK_HVEM_Freigabe "Der HVK gibt das HVEM frei, um das HV-Netz unter Einhaltung von Leistungsgrenzen in Anspruch zu nehmen.";
CM_ SG_ 1283 HVK_HVLM_Sollmodus "Angeforderter Sollmodus des Lademanagers.";
CM_ SG_ 1283 HVK_HVPTC_Sollmodus "Sollmodus HV-PTC
0 : keine Freigabe
1 : Freigabe
2 : Freigabe_ausgesetzt
3 : nicht belegbar
4 : nicht belegbar
5 : nicht belegbar
6 : nicht belegbar
7 : Init   (CAN-Initialisierung)   

Info: 'nicht belegbar' d.h. Sollmodus nicht relevant für HV";
CM_ SG_ 1283 HVK_Iso_Messung_Start "Anforderung an die isolationswiderstandsüberwachenden HV-Komponenten zur Durchführung der Isolations-Widerstandsmessung.";
CM_ SG_ 1283 HVK_Istmodus_Anf "HVK-Anforderung an alle HV-Komponenten deren Istmodus im schnellen Zyklus (Inhibitzeit) zu senden.";
CM_ SG_ 1283 HVK_Ladebereit "Information an das Lademanagement, dass das HV-System aus Sicht des HVKs bereitgestellt werden kann.";
CM_ SG_ 1283 HVK_Notabschaltung_Anf "Aufforderung zur schnellstmöglichen Abschaltung des HV-Netzes aufgrund HV-Sicherheit";
CM_ SG_ 1283 HVK_PPulsFreigabe "Prüfpuls-Freigabe seitens Hochvoltkoordinator";
CM_ SG_ 1283 HVK_TN1_Sollmodus "Angeforderter Sollmodus der Steuereinheit für das Schütze des Teilnetz1 'Ladepfad':
0 : HV_Off                                
1 : HV_On (Schütz geschlossen)                
2 : reserviert
3 : Init   (CAN-Initialisierung)";
CM_ SG_ 1283 HVK_Vorladung_aktiv "Systeminformation, dass aktiv vorgeladen wird";

CM_ SG_ 2331595857 HVK_BMS_DC_Ladeschuetze_Soll "Sollmodus DC-Ladeschütze";
CM_ SG_ 2331595857 HVK_BMS_Hauptschuetze_Soll "Sollmodus der Hauptschuetze";
CM_ SG_ 2331595857 HVK_DC_PruefpulsStatus "0 = DCDC Pruefpuls inaktiv
1 = DCDC stellt Pruefpuls ein
2 = DCDC Pruefspannung erreicht";

CM_ SG_ 2463978813 HVL_01_BZ "4bit Botschaftszähler, wird mit jeder Sendebotschaft inkrementiert";
CM_ SG_ 2463978813 HVL_01_CRC "Für MLB:
Berechnung siehe Lastenheft 'Kommunikationsabsicherung für FlexRay und CAN'
Ab MQB und MLBevo:
Berechnung siehe Lastenheft 'End-to-End Kommunikationsabsicherung'

Endwerte siehe Begleitdokument 'S-PDU Kennungsfolgen'";
CM_ SG_ 2463978813 HVL_HVK_Fehler_DCAbschaltung "Status der Anforderung einer DC-Laden-Notabschaltung";
CM_ SG_ 2463978813 HVL_Kuehltemperatur "Istwert der OCC-Kühlkanaltemperatur";
CM_ SG_ 2463978813 HVL_LadeAnforderung "FuSi-Abgesicherte Ladeanforderung an den HVK";
CM_ SG_ 2463978813 HVL_OBG_Typ_verbaut "Typ des verbauten Onboard-Gleichrichters";
CM_ SG_ 2463978813 HVL_OCC_IstModus "aktueller Funktionszustand des OCC";
CM_ SG_ 2463978813 HVL_Status_EoHVL "Erkennung einer offenen HV-Leitung (EoHVL), bewertet anhand einer Spannungsgrenze";
CM_ SG_ 2463978813 HVL_Status_Spgfreiheit "Status der Spannungsfreiheit für den Onboard Charge Client";
CM_ SG_ 2463978813 HVL_Steckerstatus "Stellt den Status des Ladesteckers hinsichtlich Präsenz zur Verfügung";

CM_ SG_ 2463978689 HVLM_BCAM_Aktiv "Dieses Signal gibt den Aktivierungsstatus des Battery Charging Care Modes an und gehört zum HV-Laden";
CM_ SG_ 2463978689 HVLM_BCCM_SoC "Dieser Parameter bestimmt die Ladeschwelle des Battery Charging Care Modes und gehört zum HV-Laden";
CM_ SG_ 2463978689 HVLM_BCCMKundenfreigabe_Status "Dieses Signal zeigt an, ob der Kunde der Konditionierung seiner HV-Batterie und der damit verbundenen Reduzierung deren Ladezustands zugestimmt hat.";
CM_ SG_ 2463978689 HVLM_FreigabeLeistungNebenverbr "gibt die Leistung an die durch das HVEM verteilt werden kann";
CM_ SG_ 2463978689 HVLM_IstKonsWunschHVBat "Dieses Signal zeigt an, ob der Kunde wünscht, dass die HV-Batterie für eine lange Standzeit auf einen sehr batterieschonenden Ladezustand entladen wird.";
CM_ SG_ 2463978689 HVLM_IstStrom_02 "Momentaner Ladestrom unabhängig vom Lademodus (AC oder DC) in 0,1A";
CM_ SG_ 2463978689 HVLM_SollSoCKonservierung "Dieser Parameter bestimmt den Ladezustand, auf den die HV-Batterie entladen wird, wenn der Kunde die Konservierung für eine sehr lange Standzeit wünscht.";

CM_ SG_ 626 HVLM_Aktive_Ladeart "informs about the used charging infrastructure - AC - DC - AWC.";
CM_ SG_ 626 HVLM_Anforderung_HMS "Anforderung zur Verriegelung des Triebstrangs";
CM_ SG_ 626 HVLM_AWC_VerbautStatus "Verbausignalisierung vom HVLM der optionalen Komponente AWC";
CM_ SG_ 626 HVLM_DC_Aufstartmodus "Aufstartmodus zum Aktivieren des HV-Modus für DC-Laden";
CM_ SG_ 626 HVLM_Intensitaet_Lk1 "Über dieses Signal wird eine Information über die Beleuchtungsintensität an der LED der Ladeklappe 1 gesendet.";
CM_ SG_ 626 HVLM_Intensitaet_Lk2 "Über dieses Signal wird eine Information über die Beleuchtungsintensität an der LED der Ladeklappe 2 gesendet.";
CM_ SG_ 626 HVLM_Laden_ISO_Messung_Anf "Messung des Isolationswiderstandes des Ladesystems (Fzg und Ladesäule) während des Ladevorganges durch das Fahrzeug
0= Anforderung
1= keine_Anforderung";
CM_ SG_ 626 HVLM_Ladeszenario "Über dieses Signal wird das einzustellende Szenario für die Visualisierung gesendet.";
CM_ SG_ 626 HVLM_Ladevorgang_Anf "Art der angeforderten Ladeart 
0 = Laden_nicht_angefordert
1 = AC_Laden_Angefordert
2 = DC_Laden_Angefordert
3 = AC_und_DC_Angefordert
4 = Induktiv_Laden_Angef
5 = AC_und_Induktiv_Angef
6 = DC_und_Induktiv_Angef
7 = AC_DC_und_Induktiv_Angef";
CM_ SG_ 626 HVLM_Parken_beibehalten_HMS "Anforderung den Triebstrang verriegelt zu halten";
CM_ SG_ 626 HVLM_Pulsierstufe "Über dieses Signal wird eine Information über die Frequenz der Ladedosen LED bei verschiedenen Leuchtmustern gesendet.";
CM_ SG_ 626 HVLM_Start_Pulserkennung "Startanforderung für die Pulserkennung";
CM_ SG_ 626 HVLM_Steckerstatus_A "Gibt den Steckerstatus aus der Ladedose A an";
CM_ SG_ 626 HVLM_Steckerstatus_B "Gibt den Steckerstatus aus der Ladedose B an";
CM_ SG_ 626 HVLM_WakeUpZaehlerResetAnf "Dieses Signal kann den Wakeup-Verhinderungszähler zurücksetzen";
CM_ SG_ 626 HVLM_ZustandLadeablauf "Zustand im Ablauf des Ladevorganges
0 = Init
1 = Standby_Ladevorbedingungen erfuellt
2 = Standby_Ladevorbedingungen_nicht_erfuellt
3 = Fehler
4 = Laden_starten
5 = Laden_beenden
6 = HVBatterie_Laden
7 = HVBatterie_Entladen
8 = Erhaltungsladen";

CM_ SG_ 268 ImoCord_Auth_Aufforderung_WFS "WFS-Anforderung";

CM_ SG_ 19 WFS_IMMO_GSG_Data_0 "Zusatzinformation der WFS-Freigabe für GSG (z.B. Freigabe mit Geschw. Limitierung)";
CM_ SG_ 19 WFS_IMMO_GSG_Data_1 "Zusatzinformation der WFS-Freigabe für GSG (z.B. Freigabe mit Geschw. Limitierung)";
CM_ SG_ 19 WFS_IMMO_GSG_Data_2 "Zusatzinformation der WFS-Freigabe für GSG (z.B. Freigabe mit Geschw. Limitierung)";

CM_ SG_ 17 WFS_IMMO_MSG1_Data_0 "Zusatzinformation der WFS-Freigabe (z.B. Freigabe mit Geschw. Limitierung)";
CM_ SG_ 17 WFS_IMMO_MSG1_Data_1 "Zusatzinformation der WFS-Freigabe für MSG1/LE4 (z.B. Freigabe mit Geschw. Limitierung)";
CM_ SG_ 17 WFS_IMMO_MSG1_Data_2 "Zusatzinformation der WFS-Freigabe für MSG1/LE4 (z.B. Freigabe mit Geschw. Limitierung)";

CM_ SG_ 23 WFS_IMMO_MSG3_Data_0 "Zusatzinformation der WFS-Freigabe für MSG3/LE2 (z.B. Freigabe mit Geschw. Limitierung)";
CM_ SG_ 23 WFS_IMMO_MSG3_Data_1 "Zusatzinformation der WFS-Freigabe für MSG3/LE2 (z.B. Freigabe mit Geschw. Limitierung)";
CM_ SG_ 23 WFS_IMMO_MSG3_Data_2 "Zusatzinformation der WFS-Freigabe für MSG3/LE2 (z.B. Freigabe mit Geschw. Limitierung)";

CM_ SG_ 25 WFS_IMMO_MSG4_Data_0 "Zusatzinformation der WFS-Freigabe für MSG4/LE1 (z.B. Freigabe mit Geschw. Limitierung)";
CM_ SG_ 25 WFS_IMMO_MSG4_Data_1 "Zusatzinformation der WFS-Freigabe für MSG4/LE1 (z.B. Freigabe mit Geschw. Limitierung)";
CM_ SG_ 25 WFS_IMMO_MSG4_Data_2 "Zusatzinformation der WFS-Freigabe für MSG4/LE1 (z.B. Freigabe mit Geschw. Limitierung)";

CM_ SG_ 312 IPA_01_BZ "Fehlende Beschreibung (Import)";
CM_ SG_ 312 IPA_01_CRC "Für MLB:
'Berechnung siehe Lastenheft 'Kommunikationsabsicherung für FlexRay und CAN''

Ab MQB und MLBevo:
'Berechnung siehe Lastenheft 'End-to-End Kommunikationsabsicherung''

Endwerte siehe Begleitdokument 'S-PDU Kennungsfolgen'";
CM_ SG_ 312 IPA_Fahrstufenwunsch "Flankengesteuerter Fahrstufenwunsch von IPA/PiloPa an das Getriebe";
CM_ SG_ 312 IPA_Status "Zustand der IPA-Statusmaschine";

CM_ SG_ 2527679583 IPA_02_BZ "4bit Botschaftszähler, wird mit jeder Sendebotschaft inkrementiert";
CM_ SG_ 2527679583 IPA_02_CRC "Für MLB:
Berechnung siehe Lastenheft 'Kommunikationsabsicherung für FlexRay und CAN'
Ab MQB und MLBevo:
Berechnung siehe Lastenheft 'End-to-End Kommunikationsabsicherung'

Endwerte siehe Begleitdokument 'S-PDU Kennungsfolgen'";
CM_ SG_ 2527679583 IPA_Akustik_PL_gefunden "Signalisiert ein akustische Benachrichtigung, dass Parklücken gefunden wurden.";
CM_ SG_ 2527679583 IPA_Anf_Meldungen "Das Signal fordert die Anzeige einer Meldung an. Jedem Signalwert ist eine Meldung zugeordnet. Das Signal ist derzeit für die Funktionen IPA/RPA und TPA implementiert.";
CM_ SG_ 2527679583 IPA_PL_Anzeige_links "Zeigt an, ob auf der linken Seite eine Parklücke erkannt wurde.";
CM_ SG_ 2527679583 IPA_PL_Anzeige_rechts "Zeigt an, ob auf der rechten Seite eine Parklücke erkannt wurde.";
CM_ SG_ 2527679583 Parken_aktives_System_02 "zeigt an welches parkendes System aktiv ist";
CM_ SG_ 2527679583 Parken_Aktivierungslicht_Anf "Anforderung des Aktivierungslichts nach erfolgreicher Aktivierungshandlung seitens Pilotiertem Parken.";
CM_ SG_ 2527679583 Parken_Bestaetigungsblinken_Anf "Anforderung seitens Pilotiertem Parken für ein Erfolgsblinken nach dem Erreichen der Zielposition bzw. für ein Abbruchsblinken bei Eintreten einer Abbruchsbedingung.";
CM_ SG_ 2527679583 Parken_Blinker_li_Anf "Anforderung seitens Parkens für 'Links blinken'";
CM_ SG_ 2527679583 Parken_Blinker_re_Anf "Anforderung seitens Parken für 'Rechts blinken'";
CM_ SG_ 2527679583 Parken_Fahrbereitschaftlicht_Anf "Anforderung des Fahrbereitschaftslichts";
CM_ SG_ 2527679583 Parken_Fahrerhinweise_Anf "Anforderung zur erneuten Lampenaufprüfung und Anzeige von Warnhinweisen nach einem pilotierten Ausparkvorgang.";
CM_ SG_ 2527679583 Parken_Fahrtrichtungslicht_Anf "Anforderung seitens Pilotiertem Parken für die Anzeige der initialen Fahrtrichtung nach Systemaktivierung.";
CM_ SG_ 2527679583 Parken_FFB_LED_Anf "Statusinformation des Pilotierten Parkens für die Ansteuerung der LED auf der Funkfernbedienung.";
CM_ SG_ 2527679583 Parken_Lichtnachlauf_Anf "Anforderung des Lichtnachlaufs beim BCM1 (analog Verlassenskonzept) für das Pilotierte Parken. ";
CM_ SG_ 2527679583 Parken_Lichtsteuerung_Anf "Anforderung zum Setzen des Lichtmodus des Fahrzeuges von der Parkfunktion";
CM_ SG_ 2527679583 Parken_Schluesselsuche_Anf "Ansteuerung der Schlüsselsuche für das pilotierte Parken.";
CM_ SG_ 2527679583 Parken_Seitenspiegel_Anf "Anforderung für Seitenspiegel an- oder abklappen beim PiloPa";
CM_ SG_ 2527679583 Parken_Wegfahrsperren_Anf "Ansteuerung der Wegfahrsperren Komponenten für das pilotierte Parken.  ";
CM_ SG_ 2527679583 Parken_ZR_Sondermodus_Anf "Anforderung Sondermodus, um beim „pilotierten Parken“ spezielle Funktionsanpassungen im Infotainment-Bereich zu ermöglichen (u.a. schnellerer Startup, Abschaltung BT)";
CM_ SG_ 2527679583 Parken_ZV_Schliessen "Anforderung für Zentralverriegelung verriegeln oder safen beim PiloPa";

CM_ SG_ 2589283690 HVLE_eTM_max_Vorlauftemperatur "Vorlauftemperatur gemäß der Ladegerätkühlung";
CM_ SG_ 2589283690 HVLE_Temperatur "Isttemperatur SAC";
CM_ SG_ 2589283690 HVLE_ThermAuslastungsgrad "Thermischer Auslastungsgrad des Ladegeräts für die Kühlanforderung";
CM_ SG_ 2589283690 IPB_ThermAuslastungsgrad "Thermischer Auslastungsgrad der IPB";
CM_ SG_ 2589283690 IPB_Wasser_TEMP_AUS "Wassertemperatur Auslass IPB";
CM_ SG_ 2589283690 IPB_Wasser_TEMP_EIN "Wassertemperatur Einlass IPB";
CM_ SG_ 2589283690 LAD_OBD_Lampe_Anf "Anforderung MIL (MalfunctionIndicationLamp) von Ladegerät (Motorsteuergerät reicht diese Info an Kombi weiter).";
CM_ SG_ 2589283690 OBDProtocol_Ladegeraet "Bestätigung des aktuell umgesetzten Scan Tool Protokolls";
CM_ SG_ 2589283690 TNV_Temperatur "Momentanwert: Temperatur des Traktionsnetzverteilers";

CM_ SG_ 2589283695 SOK_IPB_03_Signatur "Signatur im Rahmen der durch SOK geschützen Broadcast-Kommunikation

Geschützte Funktion: OBD-Malfunction Indicator Light (MIL)
Geschützte PDU: IPB_03";

CM_ SG_ 1892 ISO_AGA_Req_Data "Diagnose Request Aussensoundaktuator";

CM_ SG_ 1998 ISO_AGA_Resp_Data "Diagnose Response Aussensoundaktuator";

CM_ SG_ 1792 ISO_ALL_01_Req_Data "Funktionaler Request ALL";

CM_ SG_ 1820 ISO_Soundaktor_Req_Data "Diagnose Request Soundaktuator innen";

CM_ SG_ 1926 ISO_Soundaktor_Resp_Data "Diagnose Response Soundaktuator innen";

CM_ SG_ 2549874812 ISOx_EMotor_01_Req_Data "Diagnose Request Leistungselektronik E-Maschine 1";

CM_ SG_ 2621440124 ISOx_EMotor_01_Req_FD_Data "Diagnose Request";

CM_ SG_ 2550005884 ISOx_EMotor_01_Resp_Data "Diagnose Response Leistungselektronik E-Maschine 1";

CM_ SG_ 2621571196 ISOx_EMotor_01_Resp_FD_Data "Diagnose Response";

CM_ SG_ 2549874872 ISOx_EMotor_02_Req_Data "OffBoard Tester Diagnose Request EMotor_02";

CM_ SG_ 2621440184 ISOx_EMotor_02_Req_FD_Data "Diagnose Request";

CM_ SG_ 2550005944 ISOx_EMotor_02_Resp_Data "Diagnose Response Leistungselektronik E-Maschine 2";

CM_ SG_ 2621571256 ISOx_EMotor_02_Resp_FD_Data "Diagnose Response";

CM_ SG_ 2621505536 ISOx_Funkt_Req_All_FD_Data "OffBoard Tester funktionaler Diagnose Request ALL CANFD";

CM_ SG_ 2549874807 ISOx_Getriebe_01_Req_Data "OffBoard Tester Diagnose Request Getriebe_01";

CM_ SG_ 2621440119 ISOx_Getriebe_01_Req_FD_Data "Diagnose Request Getriebe_01";

CM_ SG_ 2550005879 ISOx_Getriebe_01_Resp_Data "OffBoard Tester Diagnose Response Getriebe_01";

CM_ SG_ 2621571191 ISOx_Getriebe_01_Resp_FD_Data "Diagnose Response Getriebe_01";

CM_ SG_ 2550399033 ISOx_LCU_SMH_Req_Data "OffBoard Tester Diagnose Request LCU_SMH";

CM_ SG_ 2621702201 ISOx_LCU_SMH_Req_FD_Data "OffBoard Tester Diagnose Response LCU_SMH";
BA_DEF_REL_ BU_SG_REL_  "GenSigTimeoutTime" INT 0 65535;
BA_DEF_ BO_  "DiagRequest" ENUM "No", "Yes";
BA_DEF_ BO_  "DiagResponse" ENUM "No", "Yes";
BA_DEF_ BO_  "DiagState" ENUM "No", "Yes";
BA_DEF_ BO_  "GenMsgChkConstant" HEX 0 4095;
BA_DEF_ BO_  "GenMsgCycleTime" INT 0 65535;
BA_DEF_ BO_  "GenMsgCycleTimeFast" INT 0 65535;
BA_DEF_ BO_  "GenMsgDelayTime" INT 0 100000;
BA_DEF_ BO_  "GenMsgILSupport" ENUM "No", "Yes";
BA_DEF_ BO_  "GenMsgNrOfRepetition" INT 0 100;
BA_DEF_ BO_  "GenMsgPDUConstants" STRING;
BA_DEF_ BO_  "GenMsgSendType" ENUM "Cyclic", "not_used", "not_used", "not_used", "not_used", "not_used", "not_used", "IfActive", "NoMsgSendType";
BA_DEF_ BO_  "GenMsgStartDelayTime" INT 0 100000;
BA_DEF_ BO_  "NmMessage" ENUM "No", "Yes";
BA_DEF_ BO_  "NmhMessage" ENUM "No", "Yes";
BA_DEF_ BO_  "MsgType" ENUM "Application", "NM ", "NMH", "TP2.0", "ISO-TP ", "BAP", "EID", "KS", "XCP_PRE_CONFIGURED", "XCP_RUNTIME_CONFIGURED";
BA_DEF_ BO_  "VAGTP20_API" HEX 0 255;
BA_DEF_ BO_  "VAGTP20_DynConnection" ENUM "No", "Yes";
BA_DEF_ BO_  "VAGTP20_DynSetup" ENUM "No", "Yes";
BA_DEF_ BO_  "VAGTP20_StatConnection" ENUM "No", "Yes";
BA_DEF_ BO_  "CANFD_BRS" ENUM "0", "1";
BA_DEF_ BO_  "VFrameFormat" ENUM "StandardCAN", "ExtendedCAN", "reserved", "reserved", "reserved", "reserved", "reserved", "reserved", "reserved", "reserved", "reserved", "reserved", "reserved", "reserved", "StandardCAN_FD", "ExtendedCAN_FD";
BA_DEF_ SG_  "GenSigActiveRepetitions" INT -2147483648 2147483647;
BA_DEF_ SG_  "GenSigInactiveValue" INT -2147483648 2147483647;
BA_DEF_ SG_  "GenSigSendType" ENUM "Cyclic", "OnWrite", "OnWriteWithRepetition", "OnChange", "OnChangeWithRepetition", "IfActive", "IfActiveWithRepetition", "NoSigSendType", "OnChangeAndIfActive", "OnChangeAndIfActiveWithRepetition";
BA_DEF_ SG_  "GenSigStartValue" INT -2147483648 2147483647;
BA_DEF_ SG_  "NWM-WakeupAllowed" ENUM "No", "Yes";
BA_DEF_ SG_  "GenSigFuncType" ENUM "NoFunction", "MsgCounter", "CRC-8", "XOR", "XOR-2", "DatedBit", "SW-Kl15", "CHK", "Constant", "Protocol", "CRC-8-SAE_J1850", "CRC-32", "DataLength", "DataID", "MsgCounter16", "SOK-Signatur", "Cluster";
BA_DEF_ SG_  "GenSigSwitchedByIgnition" ENUM "No", "Yes";
BA_DEF_ SG_  "Fehlerwert" HEX 0 2147483647;
BA_DEF_ SG_  "GenSigMissingSourceValue" HEX 0 2147483647;
BA_DEF_DEF_REL_  "GenSigTimeoutTime" 0;
BA_DEF_DEF_  "DiagRequest" "No";
BA_DEF_DEF_  "DiagResponse" "No";
BA_DEF_DEF_  "DiagState" "No";
BA_DEF_DEF_  "GenMsgChkConstant" 0;
BA_DEF_DEF_  "GenMsgCycleTime" 0;
BA_DEF_DEF_  "GenMsgCycleTimeFast" 0;
BA_DEF_DEF_  "GenMsgDelayTime" 0;
BA_DEF_DEF_  "GenMsgILSupport" "No";
BA_DEF_DEF_  "GenMsgNrOfRepetition" 0;
BA_DEF_DEF_  "GenMsgPDUConstants" "";
BA_DEF_DEF_  "GenMsgSendType" "NoMsgSendType";
BA_DEF_DEF_  "GenMsgStartDelayTime" 0;
BA_DEF_DEF_  "NmMessage" "No";
BA_DEF_DEF_  "NmhMessage" "No";
BA_DEF_DEF_  "MsgType" "Application";
BA_DEF_DEF_  "VAGTP20_API" 0;
BA_DEF_DEF_  "VAGTP20_DynConnection" "No";
BA_DEF_DEF_  "VAGTP20_DynSetup" "No";
BA_DEF_DEF_  "VAGTP20_StatConnection" "No";
BA_DEF_DEF_  "CANFD_BRS" "1";
BA_DEF_DEF_  "VFrameFormat" "StandardCAN";
BA_DEF_DEF_  "GenSigActiveRepetitions" 0;
BA_DEF_DEF_  "GenSigInactiveValue" 0;
BA_DEF_DEF_  "GenSigSendType" "NoSigSendType";
BA_DEF_DEF_  "GenSigStartValue" 0;
BA_DEF_DEF_  "NWM-WakeupAllowed" "No";
BA_DEF_DEF_  "GenSigFuncType" "NoFunction";
BA_DEF_DEF_  "GenSigSwitchedByIgnition" "Yes";
BA_DEF_DEF_  "Fehlerwert" 0;
BA_DEF_DEF_  "GenSigMissingSourceValue" 0;
BA_ "GenMsgCycleTime" BO_ 270 10;
BA_ "GenMsgILSupport" BO_ 270 1;
BA_ "GenMsgPDUConstants" BO_ 270 "0xd9,0xed,0xb6,0x03,0xa2,0x1c,0x8d,0x13,0xc1,0xc6,0xcd,0x23,0xfb,0x78,0x6d,0x7a";
BA_ "GenMsgSendType" BO_ 270 0;
BA_ "VFrameFormat" BO_ 270 14;
BA_ "GenMsgCycleTime" BO_ 509 100;
BA_ "GenMsgCycleTimeFast" BO_ 509 10;
BA_ "GenMsgDelayTime" BO_ 509 10;
BA_ "GenMsgILSupport" BO_ 509 1;
BA_ "GenMsgNrOfRepetition" BO_ 509 3;
BA_ "GenMsgPDUConstants" BO_ 509 "0xb3,0xeb,0xe1,0xf7,0xba,0x9e,0x5f,0xd9,0xc2,0xec,0xf6,0xe9,0x24,0x18,0x48,0xed";
BA_ "GenMsgSendType" BO_ 509 0;
BA_ "VFrameFormat" BO_ 509 14;
BA_ "GenMsgCycleTime" BO_ 2589283964 500;
BA_ "GenMsgILSupport" BO_ 2589283964 1;
BA_ "GenMsgSendType" BO_ 2589283964 0;
BA_ "VFrameFormat" BO_ 2589283964 15;
BA_ "GenMsgCycleTime" BO_ 299 30;
BA_ "GenMsgILSupport" BO_ 299 1;
BA_ "GenMsgPDUConstants" BO_ 299 "0x6a,0x38,0xb4,0x27,0x22,0xef,0xe1,0xbb,0xf8,0x80,0x84,0x49,0xc7,0x9e,0x1e,0x2b";
BA_ "GenMsgSendType" BO_ 299 0;
BA_ "VFrameFormat" BO_ 299 14;
BA_ "GenMsgILSupport" BO_ 18 1;
BA_ "VFrameFormat" BO_ 18 14;
BA_ "GenMsgCycleTime" BO_ 2589283397 500;
BA_ "GenMsgDelayTime" BO_ 2589283397 100;
BA_ "GenMsgILSupport" BO_ 2589283397 1;
BA_ "GenMsgSendType" BO_ 2589283397 0;
BA_ "VFrameFormat" BO_ 2589283397 15;
BA_ "GenMsgCycleTime" BO_ 2589283454 500;
BA_ "GenMsgDelayTime" BO_ 2589283454 100;
BA_ "GenMsgSendType" BO_ 2589283454 0;
BA_ "VFrameFormat" BO_ 2589283454 15;
BA_ "GenMsgCycleTime" BO_ 2589284072 500;
BA_ "GenMsgDelayTime" BO_ 2589284072 100;
BA_ "GenMsgILSupport" BO_ 2589284072 1;
BA_ "GenMsgSendType" BO_ 2589284072 0;
BA_ "VFrameFormat" BO_ 2589284072 15;
BA_ "GenMsgCycleTime" BO_ 1452 100;
BA_ "GenMsgILSupport" BO_ 1452 1;
BA_ "GenMsgSendType" BO_ 1452 0;
BA_ "VFrameFormat" BO_ 1452 14;
BA_ "GenMsgCycleTime" BO_ 1385 500;
BA_ "GenMsgDelayTime" BO_ 1385 50;
BA_ "GenMsgILSupport" BO_ 1385 1;
BA_ "GenMsgSendType" BO_ 1385 0;
BA_ "VFrameFormat" BO_ 1385 14;
BA_ "GenMsgCycleTime" BO_ 1283 100;
BA_ "GenMsgDelayTime" BO_ 1283 10;
BA_ "GenMsgILSupport" BO_ 1283 1;
BA_ "GenMsgPDUConstants" BO_ 1283 "0xed,0xd6,0x96,0x63,0xa5,0x12,0xd5,0x9a,0x1e,0x0d,0x24,0xcd,0x8c,0xa6,0x2f,0x41";
BA_ "GenMsgSendType" BO_ 1283 0;
BA_ "VFrameFormat" BO_ 1283 14;
BA_ "GenMsgCycleTime" BO_ 2331595857 100;
BA_ "GenMsgDelayTime" BO_ 2331595857 10;
BA_ "GenMsgILSupport" BO_ 2331595857 1;
BA_ "GenMsgSendType" BO_ 2331595857 0;
BA_ "VFrameFormat" BO_ 2331595857 15;
BA_ "GenMsgCycleTime" BO_ 2463978813 100;
BA_ "GenMsgDelayTime" BO_ 2463978813 10;
BA_ "GenMsgILSupport" BO_ 2463978813 1;
BA_ "GenMsgPDUConstants" BO_ 2463978813 "0x1d,0x82,0x7b,0x79,0xa5,0xee,0x3a,0xb9,0xb7,0xf9,0xe4,0x67,0x7f,0x97,0x11,0xad";
BA_ "GenMsgSendType" BO_ 2463978813 0;
BA_ "VFrameFormat" BO_ 2463978813 15;
BA_ "GenMsgCycleTime" BO_ 2463978689 100;
BA_ "GenMsgILSupport" BO_ 2463978689 1;
BA_ "GenMsgSendType" BO_ 2463978689 0;
BA_ "VFrameFormat" BO_ 2463978689 15;
BA_ "GenMsgCycleTime" BO_ 626 100;
BA_ "GenMsgDelayTime" BO_ 626 10;
BA_ "GenMsgILSupport" BO_ 626 1;
BA_ "GenMsgSendType" BO_ 626 0;
BA_ "VFrameFormat" BO_ 626 14;
BA_ "GenMsgILSupport" BO_ 268 1;
BA_ "VFrameFormat" BO_ 268 14;
BA_ "GenMsgILSupport" BO_ 19 1;
BA_ "VFrameFormat" BO_ 19 14;
BA_ "GenMsgILSupport" BO_ 17 1;
BA_ "VFrameFormat" BO_ 17 14;
BA_ "GenMsgILSupport" BO_ 23 1;
BA_ "VFrameFormat" BO_ 23 14;
BA_ "GenMsgILSupport" BO_ 25 1;
BA_ "VFrameFormat" BO_ 25 14;
BA_ "GenMsgCycleTime" BO_ 312 100;
BA_ "GenMsgILSupport" BO_ 312 1;
BA_ "GenMsgPDUConstants" BO_ 312 "0x77,0x4e,0x14,0x87,0xf2,0xf8,0xb2,0x61,0xf6,0xa4,0x52,0x94,0xd4,0x81,0x2a,0xb1";
BA_ "GenMsgSendType" BO_ 312 0;
BA_ "VFrameFormat" BO_ 312 14;
BA_ "GenMsgCycleTime" BO_ 2527679583 1000;
BA_ "GenMsgCycleTimeFast" BO_ 2527679583 100;
BA_ "GenMsgDelayTime" BO_ 2527679583 50;
BA_ "GenMsgILSupport" BO_ 2527679583 1;
BA_ "GenMsgNrOfRepetition" BO_ 2527679583 5;
BA_ "GenMsgPDUConstants" BO_ 2527679583 "0xc6,0x7f,0x85,0xb6,0xe6,0xae,0xf8,0x26,0xb0,0x8c,0x19,0x10,0x5b,0x33,0x64,0x6c";
BA_ "GenMsgSendType" BO_ 2527679583 0;
BA_ "VFrameFormat" BO_ 2527679583 15;
BA_ "GenMsgCycleTime" BO_ 2589283690 500;
BA_ "GenMsgILSupport" BO_ 2589283690 1;
BA_ "GenMsgSendType" BO_ 2589283690 0;
BA_ "VFrameFormat" BO_ 2589283690 15;
BA_ "GenMsgCycleTime" BO_ 2589283695 500;
BA_ "GenMsgSendType" BO_ 2589283695 0;
BA_ "VFrameFormat" BO_ 2589283695 15;
BA_ "DiagRequest" BO_ 1892 1;
BA_ "MsgType" BO_ 1892 4;
BA_ "VFrameFormat" BO_ 1892 14;
BA_ "DiagResponse" BO_ 1998 1;
BA_ "MsgType" BO_ 1998 4;
BA_ "VFrameFormat" BO_ 1998 14;
BA_ "DiagState" BO_ 1792 1;
BA_ "MsgType" BO_ 1792 4;
BA_ "VFrameFormat" BO_ 1792 14;
BA_ "DiagRequest" BO_ 1820 1;
BA_ "MsgType" BO_ 1820 4;
BA_ "VFrameFormat" BO_ 1820 14;
BA_ "DiagResponse" BO_ 1926 1;
BA_ "MsgType" BO_ 1926 4;
BA_ "VFrameFormat" BO_ 1926 14;
BA_ "DiagRequest" BO_ 2549874812 1;
BA_ "MsgType" BO_ 2549874812 4;
BA_ "VFrameFormat" BO_ 2549874812 15;
BA_ "DiagRequest" BO_ 2621440124 1;
BA_ "MsgType" BO_ 2621440124 4;
BA_ "VFrameFormat" BO_ 2621440124 15;
BA_ "DiagResponse" BO_ 2550005884 1;
BA_ "MsgType" BO_ 2550005884 4;
BA_ "VFrameFormat" BO_ 2550005884 15;
BA_ "DiagResponse" BO_ 2621571196 1;
BA_ "MsgType" BO_ 2621571196 4;
BA_ "VFrameFormat" BO_ 2621571196 15;
BA_ "DiagRequest" BO_ 2549874872 1;
BA_ "MsgType" BO_ 2549874872 4;
BA_ "VFrameFormat" BO_ 2549874872 15;
BA_ "DiagRequest" BO_ 2621440184 1;
BA_ "MsgType" BO_ 2621440184 4;
BA_ "VFrameFormat" BO_ 2621440184 15;
BA_ "DiagResponse" BO_ 2550005944 1;
BA_ "MsgType" BO_ 2550005944 4;
BA_ "VFrameFormat" BO_ 2550005944 15;
BA_ "DiagResponse" BO_ 2621571256 1;
BA_ "MsgType" BO_ 2621571256 4;
BA_ "VFrameFormat" BO_ 2621571256 15;
BA_ "DiagState" BO_ 2621505536 1;
BA_ "MsgType" BO_ 2621505536 4;
BA_ "VFrameFormat" BO_ 2621505536 15;
BA_ "DiagRequest" BO_ 2549874807 1;
BA_ "MsgType" BO_ 2549874807 4;
BA_ "VFrameFormat" BO_ 2549874807 15;
BA_ "DiagRequest" BO_ 2621440119 1;
BA_ "MsgType" BO_ 2621440119 4;
BA_ "VFrameFormat" BO_ 2621440119 15;
BA_ "DiagResponse" BO_ 2550005879 1;
BA_ "MsgType" BO_ 2550005879 4;
BA_ "VFrameFormat" BO_ 2550005879 15;
BA_ "DiagResponse" BO_ 2621571191 1;
BA_ "MsgType" BO_ 2621571191 4;
BA_ "VFrameFormat" BO_ 2621571191 15;
BA_ "DiagRequest" BO_ 2550399033 1;
BA_ "MsgType" BO_ 2550399033 4;
BA_ "VFrameFormat" BO_ 2550399033 15;
BA_ "DiagRequest" BO_ 2621702201 1;
BA_ "MsgType" BO_ 2621702201 4;
BA_ "VFrameFormat" BO_ 2621702201 15;
BA_ "GenSigSendType" SG_ 270 GE2_Fahrstufe 0;
BA_ "GenSigStartValue" SG_ 270 GE2_Fahrstufe 1;
BA_ "GenSigSwitchedByIgnition" SG_ 270 GE2_Fahrstufe 0;
BA_ "Fehlerwert" SG_ 270 GE2_Fahrstufe 15;
BA_ "GenSigSendType" SG_ 270 GE2_Ursache_Fahrstufe_N 0;
BA_ "GenSigSwitchedByIgnition" SG_ 270 GE2_Ursache_Fahrstufe_N 0;
BA_ "GenSigSendType" SG_ 270 GE_Abtriebsdrehzahl 0;
BA_ "GenSigStartValue" SG_ 270 GE_Abtriebsdrehzahl 65534;
BA_ "GenSigSwitchedByIgnition" SG_ 270 GE_Abtriebsdrehzahl 0;
BA_ "Fehlerwert" SG_ 270 GE_Abtriebsdrehzahl 65535;
BA_ "GenSigSendType" SG_ 270 GE_Anf_Zylabsch 0;
BA_ "GenSigSwitchedByIgnition" SG_ 270 GE_Anf_Zylabsch 0;
BA_ "GenSigSendType" SG_ 270 GE_Anheb_Solldrehz_Leerlauf 0;
BA_ "GenSigSwitchedByIgnition" SG_ 270 GE_Anheb_Solldrehz_Leerlauf 0;
BA_ "Fehlerwert" SG_ 270 GE_Anheb_Solldrehz_Leerlauf 255;
BA_ "GenSigSendType" SG_ 270 GE_Aufnahmemoment 0;
BA_ "GenSigStartValue" SG_ 270 GE_Aufnahmemoment 1022;
BA_ "GenSigSwitchedByIgnition" SG_ 270 GE_Aufnahmemoment 0;
BA_ "Fehlerwert" SG_ 270 GE_Aufnahmemoment 1023;
BA_ "GenSigSendType" SG_ 270 GE_Drehzahlmesser_Daempfung 0;
BA_ "GenSigSwitchedByIgnition" SG_ 270 GE_Drehzahlmesser_Daempfung 0;
BA_ "GenSigSendType" SG_ 270 GE_Eingangsdrehz 0;
BA_ "GenSigStartValue" SG_ 270 GE_Eingangsdrehz 16382;
BA_ "GenSigSwitchedByIgnition" SG_ 270 GE_Eingangsdrehz 0;
BA_ "Fehlerwert" SG_ 270 GE_Eingangsdrehz 16383;
BA_ "GenSigSendType" SG_ 270 GE_Eingangswellengradient 0;
BA_ "GenSigStartValue" SG_ 270 GE_Eingangswellengradient 65534;
BA_ "GenSigSwitchedByIgnition" SG_ 270 GE_Eingangswellengradient 0;
BA_ "Fehlerwert" SG_ 270 GE_Eingangswellengradient 65535;
BA_ "GenSigSendType" SG_ 270 GE_Entkopplung_Status 0;
BA_ "GenSigSwitchedByIgnition" SG_ 270 GE_Entkopplung_Status 0;
BA_ "GenSigSendType" SG_ 270 GE_Fahrstufenwunsch 0;
BA_ "GenSigStartValue" SG_ 270 GE_Fahrstufenwunsch 1;
BA_ "GenSigSwitchedByIgnition" SG_ 270 GE_Fahrstufenwunsch 0;
BA_ "Fehlerwert" SG_ 270 GE_Fahrstufenwunsch 15;
BA_ "GenSigSendType" SG_ 270 GE_Freig_Langfr_Schutzmom 0;
BA_ "GenSigSwitchedByIgnition" SG_ 270 GE_Freig_Langfr_Schutzmom 0;
BA_ "GenSigSendType" SG_ 270 GE_Freig_MMom_Vorhalt 0;
BA_ "GenSigSwitchedByIgnition" SG_ 270 GE_Freig_MMom_Vorhalt 0;
BA_ "GenSigSendType" SG_ 270 GE_Freigabe_Synchro 0;
BA_ "GenSigSwitchedByIgnition" SG_ 270 GE_Freigabe_Synchro 0;
BA_ "GenSigSendType" SG_ 270 GE_Grenzkriechmoment 0;
BA_ "GenSigStartValue" SG_ 270 GE_Grenzkriechmoment 62;
BA_ "GenSigSwitchedByIgnition" SG_ 270 GE_Grenzkriechmoment 0;
BA_ "Fehlerwert" SG_ 270 GE_Grenzkriechmoment 63;
BA_ "GenSigSendType" SG_ 270 GE_HYB_DZ_Eingriff 0;
BA_ "GenSigSwitchedByIgnition" SG_ 270 GE_HYB_DZ_Eingriff 0;
BA_ "GenSigSendType" SG_ 270 GE_HYB_EM_KompMom 0;
BA_ "GenSigSwitchedByIgnition" SG_ 270 GE_HYB_EM_KompMom 0;
BA_ "GenSigSendType" SG_ 270 GE_HYB_Fehlerstatus 0;
BA_ "GenSigSwitchedByIgnition" SG_ 270 GE_HYB_Fehlerstatus 0;
BA_ "GenSigSendType" SG_ 270 GE_HYB_Filt_MomAufbau 0;
BA_ "GenSigSwitchedByIgnition" SG_ 270 GE_HYB_Filt_MomAufbau 0;
BA_ "GenSigSendType" SG_ 270 GE_HYB_Freig_VM_EM_Stop 0;
BA_ "GenSigSwitchedByIgnition" SG_ 270 GE_HYB_Freig_VM_EM_Stop 0;
BA_ "GenSigSendType" SG_ 270 GE_HYB_Freigabe_K0 0;
BA_ "GenSigSwitchedByIgnition" SG_ 270 GE_HYB_Freigabe_K0 0;
BA_ "GenSigSendType" SG_ 270 GE_HYB_Freigabe_LL_Reg 0;
BA_ "GenSigStartValue" SG_ 270 GE_HYB_Freigabe_LL_Reg 1;
BA_ "GenSigSwitchedByIgnition" SG_ 270 GE_HYB_Freigabe_LL_Reg 0;
BA_ "GenSigSendType" SG_ 270 GE_HYB_IstStatus_K0 0;
BA_ "GenSigSwitchedByIgnition" SG_ 270 GE_HYB_IstStatus_K0 0;
BA_ "Fehlerwert" SG_ 270 GE_HYB_IstStatus_K0 3;
BA_ "GenSigSendType" SG_ 270 GE_HYB_MaxMomK0 0;
BA_ "GenSigSwitchedByIgnition" SG_ 270 GE_HYB_MaxMomK0 0;
BA_ "GenSigSendType" SG_ 270 GE_HYB_nK0 0;
BA_ "GenSigSwitchedByIgnition" SG_ 270 GE_HYB_nK0 0;
BA_ "Fehlerwert" SG_ 270 GE_HYB_nK0 255;
BA_ "GenSigSendType" SG_ 270 GE_HYB_Sportfaktor 0;
BA_ "GenSigSwitchedByIgnition" SG_ 270 GE_HYB_Sportfaktor 0;
BA_ "GenSigSendType" SG_ 270 GE_HYB_StartAnf 0;
BA_ "GenSigSwitchedByIgnition" SG_ 270 GE_HYB_StartAnf 0;
BA_ "GenSigSendType" SG_ 270 GE_HYB_VM_akt_halten 0;
BA_ "GenSigSwitchedByIgnition" SG_ 270 GE_HYB_VM_akt_halten 0;
BA_ "GenSigSendType" SG_ 270 GE_HYB_VM_Soll_Moment 0;
BA_ "GenSigStartValue" SG_ 270 GE_HYB_VM_Soll_Moment 254;
BA_ "GenSigSwitchedByIgnition" SG_ 270 GE_HYB_VM_Soll_Moment 0;
BA_ "Fehlerwert" SG_ 270 GE_HYB_VM_Soll_Moment 255;
BA_ "GenSigSendType" SG_ 270 GE_HYB_VM_Startkontr 0;
BA_ "GenSigSwitchedByIgnition" SG_ 270 GE_HYB_VM_Startkontr 0;
BA_ "GenSigSendType" SG_ 270 GE_HYB_Wiederstart 0;
BA_ "GenSigSwitchedByIgnition" SG_ 270 GE_HYB_Wiederstart 0;
BA_ "GenSigSendType" SG_ 270 GE_HYB_Wiederstartreserve 0;
BA_ "GenSigSwitchedByIgnition" SG_ 270 GE_HYB_Wiederstartreserve 0;
BA_ "GenSigSendType" SG_ 270 GE_Langfr_Schutzmom_02 0;
BA_ "GenSigStartValue" SG_ 270 GE_Langfr_Schutzmom_02 510;
BA_ "GenSigSwitchedByIgnition" SG_ 270 GE_Langfr_Schutzmom_02 0;
BA_ "Fehlerwert" SG_ 270 GE_Langfr_Schutzmom_02 511;
BA_ "GenSigSendType" SG_ 270 GE_MMom_Soll_02 0;
BA_ "GenSigStartValue" SG_ 270 GE_MMom_Soll_02 1022;
BA_ "GenSigSwitchedByIgnition" SG_ 270 GE_MMom_Soll_02 0;
BA_ "Fehlerwert" SG_ 270 GE_MMom_Soll_02 1023;
BA_ "GenSigSendType" SG_ 270 GE_MMom_Status 0;
BA_ "GenSigSwitchedByIgnition" SG_ 270 GE_MMom_Status 0;
BA_ "GenSigSendType" SG_ 270 GE_MMom_Status_02 0;
BA_ "GenSigSwitchedByIgnition" SG_ 270 GE_MMom_Status_02 0;
BA_ "GenSigSendType" SG_ 270 GE_MMom_Vorhalt_02 0;
BA_ "GenSigStartValue" SG_ 270 GE_MMom_Vorhalt_02 1022;
BA_ "GenSigSwitchedByIgnition" SG_ 270 GE_MMom_Vorhalt_02 0;
BA_ "Fehlerwert" SG_ 270 GE_MMom_Vorhalt_02 1023;
BA_ "GenSigSendType" SG_ 270 GE_Mom_Begr_Gradient 0;
BA_ "GenSigStartValue" SG_ 270 GE_Mom_Begr_Gradient 255;
BA_ "GenSigSwitchedByIgnition" SG_ 270 GE_Mom_Begr_Gradient 0;
BA_ "GenSigSendType" SG_ 270 GE_Notlauf 0;
BA_ "GenSigSwitchedByIgnition" SG_ 270 GE_Notlauf 0;
BA_ "GenSigSendType" SG_ 270 GE_Radmoment 0;
BA_ "GenSigStartValue" SG_ 270 GE_Radmoment 65534;
BA_ "GenSigSwitchedByIgnition" SG_ 270 GE_Radmoment 0;
BA_ "Fehlerwert" SG_ 270 GE_Radmoment 65535;
BA_ "GenSigSendType" SG_ 270 GE_Schaltablauf 0;
BA_ "GenSigSwitchedByIgnition" SG_ 270 GE_Schaltablauf 0;
BA_ "GenSigSendType" SG_ 270 GE_Schubabschalt_Unt 0;
BA_ "GenSigSwitchedByIgnition" SG_ 270 GE_Schubabschalt_Unt 0;
BA_ "GenSigSendType" SG_ 270 GE_StartStopp_Info 0;
BA_ "GenSigSwitchedByIgnition" SG_ 270 GE_StartStopp_Info 0;
BA_ "GenSigSendType" SG_ 270 GE_Status_Kraftschluss 0;
BA_ "GenSigSwitchedByIgnition" SG_ 270 GE_Status_Kraftschluss 0;
BA_ "GenSigSendType" SG_ 270 GE_Synchro_Status_02 0;
BA_ "GenSigSwitchedByIgnition" SG_ 270 GE_Synchro_Status_02 0;
BA_ "GenSigSendType" SG_ 270 GE_Synchro_Wunschdrehz 0;
BA_ "GenSigSwitchedByIgnition" SG_ 270 GE_Synchro_Wunschdrehz 0;
BA_ "Fehlerwert" SG_ 270 GE_Synchro_Wunschdrehz 511;
BA_ "GenSigSendType" SG_ 270 GE_Synchro_Zeit 0;
BA_ "GenSigSwitchedByIgnition" SG_ 270 GE_Synchro_Zeit 0;
BA_ "Fehlerwert" SG_ 270 GE_Synchro_Zeit 255;
BA_ "GenSigSendType" SG_ 270 GE_Uefkt 0;
BA_ "GenSigSwitchedByIgnition" SG_ 270 GE_Uefkt 0;
BA_ "Fehlerwert" SG_ 270 GE_Uefkt 1023;
BA_ "GenSigSendType" SG_ 270 GE_Uefkt_unplausibel 0;
BA_ "GenSigSwitchedByIgnition" SG_ 270 GE_Uefkt_unplausibel 0;
BA_ "GenSigSendType" SG_ 270 GE_Verbot_Ausblendung 0;
BA_ "GenSigSwitchedByIgnition" SG_ 270 GE_Verbot_Ausblendung 0;
BA_ "GenSigSendType" SG_ 270 GE_Verlustmoment 0;
BA_ "GenSigSwitchedByIgnition" SG_ 270 GE_Verlustmoment 0;
BA_ "Fehlerwert" SG_ 270 GE_Verlustmoment 255;
BA_ "GenSigSendType" SG_ 270 GE_Zielgang 0;
BA_ "GenSigSwitchedByIgnition" SG_ 270 GE_Zielgang 0;
BA_ "Fehlerwert" SG_ 270 GE_Zielgang 15;
BA_ "GenSigSendType" SG_ 270 Getriebe_50_BZ 0;
BA_ "GenSigFuncType" SG_ 270 Getriebe_50_BZ 1;
BA_ "GenSigSwitchedByIgnition" SG_ 270 Getriebe_50_BZ 0;
BA_ "GenSigSendType" SG_ 270 Getriebe_50_CRC 0;
BA_ "GenSigFuncType" SG_ 270 Getriebe_50_CRC 2;
BA_ "GenSigSwitchedByIgnition" SG_ 270 Getriebe_50_CRC 0;
BA_ "GenSigSendType" SG_ 509 Freilauf_Charisma_FahrPr 0;
BA_ "GenSigSwitchedByIgnition" SG_ 509 Freilauf_Charisma_FahrPr 0;
BA_ "GenSigSendType" SG_ 509 Freilauf_Charisma_Status 0;
BA_ "GenSigSwitchedByIgnition" SG_ 509 Freilauf_Charisma_Status 0;
BA_ "GenSigSendType" SG_ 509 FSA_Fehlerstatus_Parksperre 0;
BA_ "GenSigSwitchedByIgnition" SG_ 509 FSA_Fehlerstatus_Parksperre 0;
BA_ "GenSigSendType" SG_ 509 GE_amax_moeglich 0;
BA_ "GenSigStartValue" SG_ 509 GE_amax_moeglich 84;
BA_ "GenSigSwitchedByIgnition" SG_ 509 GE_amax_moeglich 0;
BA_ "GenSigSendType" SG_ 509 GE_Anforderung_HMS 4;
BA_ "GenSigSendType" SG_ 509 GE_Anschleppstart_Freigabe 4;
BA_ "GenSigSwitchedByIgnition" SG_ 509 GE_Anschleppstart_Freigabe 0;
BA_ "GenSigSendType" SG_ 509 GE_Betaetigung_Hold 3;
BA_ "GenSigSwitchedByIgnition" SG_ 509 GE_Betaetigung_Hold 0;
BA_ "GenSigSendType" SG_ 509 GE_Charisma_FahrPr 0;
BA_ "GenSigSwitchedByIgnition" SG_ 509 GE_Charisma_FahrPr 0;
BA_ "GenSigSendType" SG_ 509 GE_Charisma_Status 0;
BA_ "GenSigSwitchedByIgnition" SG_ 509 GE_Charisma_Status 0;
BA_ "GenSigSendType" SG_ 509 GE_Codierung_MSG 0;
BA_ "GenSigSwitchedByIgnition" SG_ 509 GE_Codierung_MSG 0;
BA_ "GenSigSendType" SG_ 509 GE_Fahrprogramm 4;
BA_ "GenSigSwitchedByIgnition" SG_ 509 GE_Fahrprogramm 0;
BA_ "GenSigSendType" SG_ 509 GE_Freigabe_Info_WFS 3;
BA_ "GenSigSwitchedByIgnition" SG_ 509 GE_Freigabe_Info_WFS 0;
BA_ "GenSigSendType" SG_ 509 GE_Freigabe_Verfallsinfo_WFS 3;
BA_ "GenSigSwitchedByIgnition" SG_ 509 GE_Freigabe_Verfallsinfo_WFS 0;
BA_ "GenSigSendType" SG_ 509 GE_Freilauf_Status 4;
BA_ "GenSigSwitchedByIgnition" SG_ 509 GE_Freilauf_Status 0;
BA_ "Fehlerwert" SG_ 509 GE_Freilauf_Status 7;
BA_ "GenSigSendType" SG_ 509 GE_Grundeinstell_Drehrichtung_EM 4;
BA_ "GenSigSwitchedByIgnition" SG_ 509 GE_Grundeinstell_Drehrichtung_EM 0;
BA_ "GenSigSendType" SG_ 509 GE_Grundeinstellung 4;
BA_ "GenSigSwitchedByIgnition" SG_ 509 GE_Grundeinstellung 0;
BA_ "GenSigSendType" SG_ 509 GE_Heizwunsch 0;
BA_ "GenSigStartValue" SG_ 509 GE_Heizwunsch 1;
BA_ "GenSigSwitchedByIgnition" SG_ 509 GE_Heizwunsch 0;
BA_ "GenSigSendType" SG_ 509 GE_LaunchControl 0;
BA_ "GenSigSwitchedByIgnition" SG_ 509 GE_LaunchControl 0;
BA_ "GenSigSendType" SG_ 509 GE_LFR_Adaption 0;
BA_ "GenSigSwitchedByIgnition" SG_ 509 GE_LFR_Adaption 0;
BA_ "GenSigSendType" SG_ 509 GE_OBD_AbsperrVent 0;
BA_ "GenSigSwitchedByIgnition" SG_ 509 GE_OBD_AbsperrVent 0;
BA_ "GenSigSendType" SG_ 509 GE_OBD_Status 0;
BA_ "GenSigSwitchedByIgnition" SG_ 509 GE_OBD_Status 0;
BA_ "GenSigSendType" SG_ 509 GE_Parken_beibehalten_HMS 0;
BA_ "GenSigStartValue" SG_ 509 GE_Parken_beibehalten_HMS 2;
BA_ "GenSigSwitchedByIgnition" SG_ 509 GE_Parken_beibehalten_HMS 0;
BA_ "Fehlerwert" SG_ 509 GE_Parken_beibehalten_HMS 3;
BA_ "GenSigSendType" SG_ 509 GE_Parken_WFS_Status 3;
BA_ "GenSigSwitchedByIgnition" SG_ 509 GE_Parken_WFS_Status 0;
BA_ "GenSigSendType" SG_ 509 GE_QBit_Sumpftemperatur 0;
BA_ "GenSigStartValue" SG_ 509 GE_QBit_Sumpftemperatur 1;
BA_ "GenSigSwitchedByIgnition" SG_ 509 GE_QBit_Sumpftemperatur 0;
BA_ "GenSigSendType" SG_ 509 GE_Schleuderoeltemperatur 0;
BA_ "GenSigStartValue" SG_ 509 GE_Schleuderoeltemperatur 254;
BA_ "GenSigSwitchedByIgnition" SG_ 509 GE_Schleuderoeltemperatur 0;
BA_ "Fehlerwert" SG_ 509 GE_Schleuderoeltemperatur 255;
BA_ "GenSigSendType" SG_ 509 GE_SpannungsAnf 0;
BA_ "GenSigSwitchedByIgnition" SG_ 509 GE_SpannungsAnf 0;
BA_ "GenSigSendType" SG_ 509 GE_Sperr_Info_WFS 3;
BA_ "GenSigSwitchedByIgnition" SG_ 509 GE_Sperr_Info_WFS 0;
BA_ "GenSigSendType" SG_ 509 GE_Strombedarf_erh 3;
BA_ "GenSigSwitchedByIgnition" SG_ 509 GE_Strombedarf_erh 0;
BA_ "GenSigSendType" SG_ 509 GE_Sumpftemperatur 0;
BA_ "GenSigSwitchedByIgnition" SG_ 509 GE_Sumpftemperatur 0;
BA_ "Fehlerwert" SG_ 509 GE_Sumpftemperatur 255;
BA_ "GenSigSendType" SG_ 509 GE_TippZustand 4;
BA_ "GenSigSwitchedByIgnition" SG_ 509 GE_TippZustand 0;
BA_ "GenSigSendType" SG_ 509 GE_Veto_Rollfaehigkeit 0;
BA_ "GenSigSwitchedByIgnition" SG_ 509 GE_Veto_Rollfaehigkeit 0;
BA_ "GenSigSendType" SG_ 509 GE_Weckleitung_aktiv 0;
BA_ "GenSigSwitchedByIgnition" SG_ 509 GE_Weckleitung_aktiv 0;
BA_ "GenSigSendType" SG_ 509 GE_Zustand_Kuppltemp 0;
BA_ "GenSigSwitchedByIgnition" SG_ 509 GE_Zustand_Kuppltemp 0;
BA_ "GenSigSendType" SG_ 509 Getriebe_51_BZ 0;
BA_ "GenSigFuncType" SG_ 509 Getriebe_51_BZ 1;
BA_ "GenSigSwitchedByIgnition" SG_ 509 Getriebe_51_BZ 0;
BA_ "GenSigSendType" SG_ 509 Getriebe_51_CRC 0;
BA_ "GenSigFuncType" SG_ 509 Getriebe_51_CRC 2;
BA_ "GenSigSwitchedByIgnition" SG_ 509 Getriebe_51_CRC 0;
BA_ "GenSigSendType" SG_ 2589283964 GE_Indc_StChk 0;
BA_ "GenSigStartValue" SG_ 2589283964 GE_Indc_StChk 1;
BA_ "GenSigSwitchedByIgnition" SG_ 2589283964 GE_Indc_StChk 0;
BA_ "GenSigSendType" SG_ 2589283964 GE_Indc_StFail 0;
BA_ "GenSigSwitchedByIgnition" SG_ 2589283964 GE_Indc_StFail 0;
BA_ "GenSigSendType" SG_ 2589283964 GE_OBD_Status_Auth 0;
BA_ "GenSigSwitchedByIgnition" SG_ 2589283964 GE_OBD_Status_Auth 0;
BA_ "GenSigSendType" SG_ 2589283964 SOK_Getriebe_52_Signatur 0;
BA_ "GenSigFuncType" SG_ 2589283964 SOK_Getriebe_52_Signatur 15;
BA_ "GenSigSwitchedByIgnition" SG_ 2589283964 SOK_Getriebe_52_Signatur 0;
BA_ "GenSigSendType" SG_ 299 GRA_Abbrechen 0;
BA_ "GenSigSendType" SG_ 299 GRA_ACC_01_BZ 0;
BA_ "GenSigFuncType" SG_ 299 GRA_ACC_01_BZ 1;
BA_ "GenSigSendType" SG_ 299 GRA_ACC_01_CRC 0;
BA_ "GenSigFuncType" SG_ 299 GRA_ACC_01_CRC 2;
BA_ "GenSigSendType" SG_ 299 GRA_Codierung 0;
BA_ "GenSigSendType" SG_ 299 GRA_Fehler 0;
BA_ "Fehlerwert" SG_ 299 GRA_Fehler 1;
BA_ "GenSigSendType" SG_ 299 GRA_Hauptschalter 0;
BA_ "GenSigSendType" SG_ 299 GRA_LIM_Taste_verfuegbar 0;
BA_ "GenSigFuncType" SG_ 299 GRA_LIM_Taste_verfuegbar 8;
BA_ "GenSigSendType" SG_ 299 GRA_Limiter 0;
BA_ "GenSigSendType" SG_ 299 GRA_PIT_Limiter 0;
BA_ "GenSigSwitchedByIgnition" SG_ 299 GRA_PIT_Limiter 0;
BA_ "GenSigSendType" SG_ 299 GRA_reserveByte5 0;
BA_ "GenSigSendType" SG_ 299 GRA_reserveByte6 0;
BA_ "GenSigSendType" SG_ 299 GRA_reserveByte7 0;
BA_ "GenSigSendType" SG_ 299 GRA_reserveByte8 0;
BA_ "GenSigSendType" SG_ 299 GRA_Tip_Hoch 0;
BA_ "GenSigSendType" SG_ 299 GRA_Tip_Runter 0;
BA_ "GenSigSendType" SG_ 299 GRA_Tip_Setzen 0;
BA_ "GenSigSendType" SG_ 299 GRA_Tip_Stufe_2 0;
BA_ "GenSigSendType" SG_ 299 GRA_Tip_Wiederaufnahme 0;
BA_ "GenSigSendType" SG_ 299 GRA_TravelAssist 0;
BA_ "GenSigSwitchedByIgnition" SG_ 299 GRA_TravelAssist 0;
BA_ "GenSigSendType" SG_ 299 GRA_Typ_Bedienteil 0;
BA_ "GenSigSendType" SG_ 299 GRA_Typ_Hauptschalter 0;
BA_ "GenSigSendType" SG_ 299 GRA_Verstellung_Zeitluecke 0;
BA_ "GenSigSwitchedByIgnition" SG_ 18 WFS_GSG_CRC 0;
BA_ "GenSigSendType" SG_ 18 WFS_GSG_RND 1;
BA_ "GenSigSwitchedByIgnition" SG_ 18 WFS_GSG_RND 0;
BA_ "GenSigSendType" SG_ 2589283397 GW_CAL_ID_Index_01 0;
BA_ "GenSigStartValue" SG_ 2589283397 GW_CAL_ID_Index_01 63;
BA_ "GenSigSwitchedByIgnition" SG_ 2589283397 GW_CAL_ID_Index_01 0;
BA_ "GenSigSendType" SG_ 2589283397 GW_CAL_ID_Index_02 0;
BA_ "GenSigStartValue" SG_ 2589283397 GW_CAL_ID_Index_02 63;
BA_ "GenSigSwitchedByIgnition" SG_ 2589283397 GW_CAL_ID_Index_02 0;
BA_ "GenSigSendType" SG_ 2589283397 GW_CAL_ID_Index_03 0;
BA_ "GenSigStartValue" SG_ 2589283397 GW_CAL_ID_Index_03 63;
BA_ "GenSigSwitchedByIgnition" SG_ 2589283397 GW_CAL_ID_Index_03 0;
BA_ "GenSigSendType" SG_ 2589283397 GW_CAL_ID_Index_04 0;
BA_ "GenSigStartValue" SG_ 2589283397 GW_CAL_ID_Index_04 63;
BA_ "GenSigSwitchedByIgnition" SG_ 2589283397 GW_CAL_ID_Index_04 0;
BA_ "GenSigSendType" SG_ 2589283397 GW_CAL_ID_Index_05 0;
BA_ "GenSigStartValue" SG_ 2589283397 GW_CAL_ID_Index_05 63;
BA_ "GenSigSwitchedByIgnition" SG_ 2589283397 GW_CAL_ID_Index_05 0;
BA_ "GenSigSendType" SG_ 2589283397 GW_CAL_ID_Index_06 0;
BA_ "GenSigStartValue" SG_ 2589283397 GW_CAL_ID_Index_06 63;
BA_ "GenSigSwitchedByIgnition" SG_ 2589283397 GW_CAL_ID_Index_06 0;
BA_ "GenSigSendType" SG_ 2589283397 GW_CAL_ID_Index_07 0;
BA_ "GenSigStartValue" SG_ 2589283397 GW_CAL_ID_Index_07 63;
BA_ "GenSigSwitchedByIgnition" SG_ 2589283397 GW_CAL_ID_Index_07 0;
BA_ "GenSigSendType" SG_ 2589283397 GW_CAL_ID_Index_08 0;
BA_ "GenSigStartValue" SG_ 2589283397 GW_CAL_ID_Index_08 63;
BA_ "GenSigSwitchedByIgnition" SG_ 2589283397 GW_CAL_ID_Index_08 0;
BA_ "GenSigSendType" SG_ 2589283397 GW_CAL_ID_Index_09 0;
BA_ "GenSigStartValue" SG_ 2589283397 GW_CAL_ID_Index_09 63;
BA_ "GenSigSwitchedByIgnition" SG_ 2589283397 GW_CAL_ID_Index_09 0;
BA_ "GenSigSendType" SG_ 2589283397 GW_CAL_ID_Index_10 0;
BA_ "GenSigStartValue" SG_ 2589283397 GW_CAL_ID_Index_10 63;
BA_ "GenSigSwitchedByIgnition" SG_ 2589283397 GW_CAL_ID_Index_10 0;
BA_ "GenSigSendType" SG_ 2589283397 GW_CAL_ID_Index_11 0;
BA_ "GenSigStartValue" SG_ 2589283397 GW_CAL_ID_Index_11 63;
BA_ "GenSigSwitchedByIgnition" SG_ 2589283397 GW_CAL_ID_Index_11 0;
BA_ "GenSigSendType" SG_ 2589283397 GW_CAL_ID_Index_12 0;
BA_ "GenSigStartValue" SG_ 2589283397 GW_CAL_ID_Index_12 63;
BA_ "GenSigSwitchedByIgnition" SG_ 2589283397 GW_CAL_ID_Index_12 0;
BA_ "GenSigSendType" SG_ 2589283397 GW_CAL_ID_Index_13 0;
BA_ "GenSigStartValue" SG_ 2589283397 GW_CAL_ID_Index_13 63;
BA_ "GenSigSwitchedByIgnition" SG_ 2589283397 GW_CAL_ID_Index_13 0;
BA_ "GenSigSendType" SG_ 2589283397 GW_CAL_ID_Index_14 0;
BA_ "GenSigStartValue" SG_ 2589283397 GW_CAL_ID_Index_14 63;
BA_ "GenSigSwitchedByIgnition" SG_ 2589283397 GW_CAL_ID_Index_14 0;
BA_ "GenSigSendType" SG_ 2589283397 GW_CAL_ID_Index_15 0;
BA_ "GenSigStartValue" SG_ 2589283397 GW_CAL_ID_Index_15 63;
BA_ "GenSigSwitchedByIgnition" SG_ 2589283397 GW_CAL_ID_Index_15 0;
BA_ "GenSigSendType" SG_ 2589283397 GW_CAL_ID_Index_16 0;
BA_ "GenSigStartValue" SG_ 2589283397 GW_CAL_ID_Index_16 63;
BA_ "GenSigSwitchedByIgnition" SG_ 2589283397 GW_CAL_ID_Index_16 0;
BA_ "GenSigSendType" SG_ 2589283397 GW_CVN 0;
BA_ "GenSigSwitchedByIgnition" SG_ 2589283397 GW_CVN 0;
BA_ "GenSigSendType" SG_ 2589283397 GW_CVN_VLD 0;
BA_ "GenSigSwitchedByIgnition" SG_ 2589283397 GW_CVN_VLD 0;
BA_ "GenSigSendType" SG_ 2589283397 GW_KomponentenFehler_01 3;
BA_ "GenSigStartValue" SG_ 2589283397 GW_KomponentenFehler_01 2;
BA_ "GenSigSwitchedByIgnition" SG_ 2589283397 GW_KomponentenFehler_01 0;
BA_ "GenSigSendType" SG_ 2589283397 GW_Komponentenfehler_02 3;
BA_ "GenSigStartValue" SG_ 2589283397 GW_Komponentenfehler_02 2;
BA_ "GenSigSwitchedByIgnition" SG_ 2589283397 GW_Komponentenfehler_02 0;
BA_ "GenSigSendType" SG_ 2589283397 GW_Komponentenfehler_03 3;
BA_ "GenSigStartValue" SG_ 2589283397 GW_Komponentenfehler_03 2;
BA_ "GenSigSwitchedByIgnition" SG_ 2589283397 GW_Komponentenfehler_03 0;
BA_ "GenSigSendType" SG_ 2589283397 GW_Komponentenfehler_04 3;
BA_ "GenSigStartValue" SG_ 2589283397 GW_Komponentenfehler_04 2;
BA_ "GenSigSwitchedByIgnition" SG_ 2589283397 GW_Komponentenfehler_04 0;
BA_ "GenSigSendType" SG_ 2589283397 GW_Komponentenfehler_05 3;
BA_ "GenSigStartValue" SG_ 2589283397 GW_Komponentenfehler_05 2;
BA_ "GenSigSwitchedByIgnition" SG_ 2589283397 GW_Komponentenfehler_05 0;
BA_ "GenSigSendType" SG_ 2589283397 GW_Komponentenfehler_06 3;
BA_ "GenSigStartValue" SG_ 2589283397 GW_Komponentenfehler_06 2;
BA_ "GenSigSwitchedByIgnition" SG_ 2589283397 GW_Komponentenfehler_06 0;
BA_ "GenSigSendType" SG_ 2589283397 GW_Komponentenfehler_07 3;
BA_ "GenSigStartValue" SG_ 2589283397 GW_Komponentenfehler_07 2;
BA_ "GenSigSwitchedByIgnition" SG_ 2589283397 GW_Komponentenfehler_07 0;
BA_ "GenSigSendType" SG_ 2589283397 GW_Komponentenfehler_08 3;
BA_ "GenSigStartValue" SG_ 2589283397 GW_Komponentenfehler_08 2;
BA_ "GenSigSwitchedByIgnition" SG_ 2589283397 GW_Komponentenfehler_08 0;
BA_ "GenSigSendType" SG_ 2589283397 GW_Komponentenfehler_09 3;
BA_ "GenSigStartValue" SG_ 2589283397 GW_Komponentenfehler_09 2;
BA_ "GenSigSwitchedByIgnition" SG_ 2589283397 GW_Komponentenfehler_09 0;
BA_ "GenSigSendType" SG_ 2589283397 GW_Komponentenfehler_10 3;
BA_ "GenSigStartValue" SG_ 2589283397 GW_Komponentenfehler_10 2;
BA_ "GenSigSwitchedByIgnition" SG_ 2589283397 GW_Komponentenfehler_10 0;
BA_ "GenSigSendType" SG_ 2589283397 GW_Komponentenfehler_11 3;
BA_ "GenSigStartValue" SG_ 2589283397 GW_Komponentenfehler_11 2;
BA_ "GenSigSwitchedByIgnition" SG_ 2589283397 GW_Komponentenfehler_11 0;
BA_ "GenSigSendType" SG_ 2589283397 GW_Komponentenfehler_12 3;
BA_ "GenSigStartValue" SG_ 2589283397 GW_Komponentenfehler_12 2;
BA_ "GenSigSwitchedByIgnition" SG_ 2589283397 GW_Komponentenfehler_12 0;
BA_ "GenSigSendType" SG_ 2589283397 GW_Komponentenfehler_13 3;
BA_ "GenSigStartValue" SG_ 2589283397 GW_Komponentenfehler_13 2;
BA_ "GenSigSwitchedByIgnition" SG_ 2589283397 GW_Komponentenfehler_13 0;
BA_ "GenSigSendType" SG_ 2589283397 GW_Komponentenfehler_14 3;
BA_ "GenSigStartValue" SG_ 2589283397 GW_Komponentenfehler_14 2;
BA_ "GenSigSwitchedByIgnition" SG_ 2589283397 GW_Komponentenfehler_14 0;
BA_ "GenSigSendType" SG_ 2589283397 GW_Komponentenfehler_15 3;
BA_ "GenSigStartValue" SG_ 2589283397 GW_Komponentenfehler_15 2;
BA_ "GenSigSwitchedByIgnition" SG_ 2589283397 GW_Komponentenfehler_15 0;
BA_ "GenSigSendType" SG_ 2589283397 GW_Komponentenfehler_16 3;
BA_ "GenSigStartValue" SG_ 2589283397 GW_Komponentenfehler_16 2;
BA_ "GenSigSwitchedByIgnition" SG_ 2589283397 GW_Komponentenfehler_16 0;
BA_ "GenSigSendType" SG_ 2589283397 GW_Komponentenfehler_17 3;
BA_ "GenSigStartValue" SG_ 2589283397 GW_Komponentenfehler_17 2;
BA_ "GenSigSwitchedByIgnition" SG_ 2589283397 GW_Komponentenfehler_17 0;
BA_ "GenSigSendType" SG_ 2589283397 GW_Komponentenfehler_18 3;
BA_ "GenSigStartValue" SG_ 2589283397 GW_Komponentenfehler_18 2;
BA_ "GenSigSwitchedByIgnition" SG_ 2589283397 GW_Komponentenfehler_18 0;
BA_ "GenSigSendType" SG_ 2589283397 GW_Komponentenfehler_19 3;
BA_ "GenSigStartValue" SG_ 2589283397 GW_Komponentenfehler_19 2;
BA_ "GenSigSwitchedByIgnition" SG_ 2589283397 GW_Komponentenfehler_19 0;
BA_ "GenSigSendType" SG_ 2589283397 GW_Komponentenfehler_20 3;
BA_ "GenSigStartValue" SG_ 2589283397 GW_Komponentenfehler_20 2;
BA_ "GenSigSwitchedByIgnition" SG_ 2589283397 GW_Komponentenfehler_20 0;
BA_ "GenSigSendType" SG_ 2589283397 GW_Komponentenfehler_21 3;
BA_ "GenSigStartValue" SG_ 2589283397 GW_Komponentenfehler_21 2;
BA_ "GenSigSwitchedByIgnition" SG_ 2589283397 GW_Komponentenfehler_21 0;
BA_ "GenSigSendType" SG_ 2589283397 GW_Komponentenfehler_22 3;
BA_ "GenSigStartValue" SG_ 2589283397 GW_Komponentenfehler_22 2;
BA_ "GenSigSwitchedByIgnition" SG_ 2589283397 GW_Komponentenfehler_22 0;
BA_ "GenSigSendType" SG_ 2589283397 GW_Komponentenfehler_23 3;
BA_ "GenSigStartValue" SG_ 2589283397 GW_Komponentenfehler_23 2;
BA_ "GenSigSwitchedByIgnition" SG_ 2589283397 GW_Komponentenfehler_23 0;
BA_ "GenSigSendType" SG_ 2589283397 GW_Komponentenfehler_24 3;
BA_ "GenSigStartValue" SG_ 2589283397 GW_Komponentenfehler_24 2;
BA_ "GenSigSwitchedByIgnition" SG_ 2589283397 GW_Komponentenfehler_24 0;
BA_ "GenSigSendType" SG_ 2589283397 GW_Komponentenfehler_25 3;
BA_ "GenSigStartValue" SG_ 2589283397 GW_Komponentenfehler_25 2;
BA_ "GenSigSwitchedByIgnition" SG_ 2589283397 GW_Komponentenfehler_25 0;
BA_ "GenSigSendType" SG_ 2589283397 GW_Komponentenfehler_26 3;
BA_ "GenSigStartValue" SG_ 2589283397 GW_Komponentenfehler_26 2;
BA_ "GenSigSwitchedByIgnition" SG_ 2589283397 GW_Komponentenfehler_26 0;
BA_ "GenSigSendType" SG_ 2589283397 GW_Komponentenfehler_27 3;
BA_ "GenSigStartValue" SG_ 2589283397 GW_Komponentenfehler_27 2;
BA_ "GenSigSwitchedByIgnition" SG_ 2589283397 GW_Komponentenfehler_27 0;
BA_ "GenSigSendType" SG_ 2589283397 GW_Komponentenfehler_28 3;
BA_ "GenSigStartValue" SG_ 2589283397 GW_Komponentenfehler_28 2;
BA_ "GenSigSwitchedByIgnition" SG_ 2589283397 GW_Komponentenfehler_28 0;
BA_ "GenSigSendType" SG_ 2589283397 GW_Komponentenfehler_29 3;
BA_ "GenSigStartValue" SG_ 2589283397 GW_Komponentenfehler_29 2;
BA_ "GenSigSwitchedByIgnition" SG_ 2589283397 GW_Komponentenfehler_29 0;
BA_ "GenSigSendType" SG_ 2589283397 GW_Komponentenfehler_30 3;
BA_ "GenSigStartValue" SG_ 2589283397 GW_Komponentenfehler_30 2;
BA_ "GenSigSwitchedByIgnition" SG_ 2589283397 GW_Komponentenfehler_30 0;
BA_ "GenSigSendType" SG_ 2589283397 GW_Komponentenfehler_31 3;
BA_ "GenSigStartValue" SG_ 2589283397 GW_Komponentenfehler_31 2;
BA_ "GenSigSwitchedByIgnition" SG_ 2589283397 GW_Komponentenfehler_31 0;
BA_ "GenSigSendType" SG_ 2589283397 GW_Komponentenfehler_32 3;
BA_ "GenSigStartValue" SG_ 2589283397 GW_Komponentenfehler_32 2;
BA_ "GenSigSwitchedByIgnition" SG_ 2589283397 GW_Komponentenfehler_32 0;
BA_ "GenSigSendType" SG_ 2589283397 GW_Komponentenfehler_33 3;
BA_ "GenSigStartValue" SG_ 2589283397 GW_Komponentenfehler_33 2;
BA_ "GenSigSwitchedByIgnition" SG_ 2589283397 GW_Komponentenfehler_33 0;
BA_ "GenSigSendType" SG_ 2589283397 GW_Komponentenfehler_34 3;
BA_ "GenSigStartValue" SG_ 2589283397 GW_Komponentenfehler_34 2;
BA_ "GenSigSwitchedByIgnition" SG_ 2589283397 GW_Komponentenfehler_34 0;
BA_ "GenSigSendType" SG_ 2589283397 GW_Komponentenfehler_35 3;
BA_ "GenSigStartValue" SG_ 2589283397 GW_Komponentenfehler_35 2;
BA_ "GenSigSwitchedByIgnition" SG_ 2589283397 GW_Komponentenfehler_35 0;
BA_ "GenSigSendType" SG_ 2589283397 GW_Komponentenfehler_36 3;
BA_ "GenSigStartValue" SG_ 2589283397 GW_Komponentenfehler_36 2;
BA_ "GenSigSwitchedByIgnition" SG_ 2589283397 GW_Komponentenfehler_36 0;
BA_ "GenSigSendType" SG_ 2589283397 GW_Komponentenfehler_37 3;
BA_ "GenSigStartValue" SG_ 2589283397 GW_Komponentenfehler_37 2;
BA_ "GenSigSwitchedByIgnition" SG_ 2589283397 GW_Komponentenfehler_37 0;
BA_ "GenSigSendType" SG_ 2589283397 GW_Komponentenfehler_38 3;
BA_ "GenSigStartValue" SG_ 2589283397 GW_Komponentenfehler_38 2;
BA_ "GenSigSwitchedByIgnition" SG_ 2589283397 GW_Komponentenfehler_38 0;
BA_ "GenSigSendType" SG_ 2589283397 GW_Komponentenfehler_39 3;
BA_ "GenSigStartValue" SG_ 2589283397 GW_Komponentenfehler_39 2;
BA_ "GenSigSwitchedByIgnition" SG_ 2589283397 GW_Komponentenfehler_39 0;
BA_ "GenSigSendType" SG_ 2589283397 GW_Komponentenfehler_40 3;
BA_ "GenSigStartValue" SG_ 2589283397 GW_Komponentenfehler_40 2;
BA_ "GenSigSwitchedByIgnition" SG_ 2589283397 GW_Komponentenfehler_40 0;
BA_ "GenSigSendType" SG_ 2589283397 GW_Komponentenfehler_41 3;
BA_ "GenSigStartValue" SG_ 2589283397 GW_Komponentenfehler_41 2;
BA_ "GenSigSwitchedByIgnition" SG_ 2589283397 GW_Komponentenfehler_41 0;
BA_ "GenSigSendType" SG_ 2589283397 GW_Komponentenfehler_42 3;
BA_ "GenSigStartValue" SG_ 2589283397 GW_Komponentenfehler_42 2;
BA_ "GenSigSwitchedByIgnition" SG_ 2589283397 GW_Komponentenfehler_42 0;
BA_ "GenSigSendType" SG_ 2589283397 GW_Komponentenfehler_43 3;
BA_ "GenSigStartValue" SG_ 2589283397 GW_Komponentenfehler_43 2;
BA_ "GenSigSwitchedByIgnition" SG_ 2589283397 GW_Komponentenfehler_43 0;
BA_ "GenSigSendType" SG_ 2589283397 GW_Komponentenfehler_44 3;
BA_ "GenSigStartValue" SG_ 2589283397 GW_Komponentenfehler_44 2;
BA_ "GenSigSwitchedByIgnition" SG_ 2589283397 GW_Komponentenfehler_44 0;
BA_ "GenSigSendType" SG_ 2589283397 GW_Komponentenfehler_45 3;
BA_ "GenSigStartValue" SG_ 2589283397 GW_Komponentenfehler_45 2;
BA_ "GenSigSwitchedByIgnition" SG_ 2589283397 GW_Komponentenfehler_45 0;
BA_ "GenSigSendType" SG_ 2589283397 GW_Komponentenfehler_46 3;
BA_ "GenSigStartValue" SG_ 2589283397 GW_Komponentenfehler_46 2;
BA_ "GenSigSwitchedByIgnition" SG_ 2589283397 GW_Komponentenfehler_46 0;
BA_ "GenSigSendType" SG_ 2589283397 GW_Komponentenfehler_47 3;
BA_ "GenSigStartValue" SG_ 2589283397 GW_Komponentenfehler_47 2;
BA_ "GenSigSwitchedByIgnition" SG_ 2589283397 GW_Komponentenfehler_47 0;
BA_ "GenSigSendType" SG_ 2589283397 GW_Komponentenfehler_VLD 0;
BA_ "GenSigSwitchedByIgnition" SG_ 2589283397 GW_Komponentenfehler_VLD 0;
BA_ "GenSigSendType" SG_ 2589283454 SOK_GW_CVN_Komp_02_Signatur 0;
BA_ "GenSigFuncType" SG_ 2589283454 SOK_GW_CVN_Komp_02_Signatur 15;
BA_ "GenSigSwitchedByIgnition" SG_ 2589283454 SOK_GW_CVN_Komp_02_Signatur 0;
BA_ "GenSigSendType" SG_ 2589284072 GW_Komponentenfehler_48 3;
BA_ "GenSigStartValue" SG_ 2589284072 GW_Komponentenfehler_48 2;
BA_ "GenSigSwitchedByIgnition" SG_ 2589284072 GW_Komponentenfehler_48 0;
BA_ "GenSigSendType" SG_ 2589284072 GW_Komponentenfehler_49 3;
BA_ "GenSigStartValue" SG_ 2589284072 GW_Komponentenfehler_49 2;
BA_ "GenSigSwitchedByIgnition" SG_ 2589284072 GW_Komponentenfehler_49 0;
BA_ "GenSigSendType" SG_ 2589284072 GW_Komponentenfehler_50 3;
BA_ "GenSigStartValue" SG_ 2589284072 GW_Komponentenfehler_50 2;
BA_ "GenSigSwitchedByIgnition" SG_ 2589284072 GW_Komponentenfehler_50 0;
BA_ "GenSigSendType" SG_ 2589284072 GW_Komponentenfehler_51 3;
BA_ "GenSigStartValue" SG_ 2589284072 GW_Komponentenfehler_51 2;
BA_ "GenSigSwitchedByIgnition" SG_ 2589284072 GW_Komponentenfehler_51 0;
BA_ "GenSigSendType" SG_ 2589284072 GW_Komponentenfehler_52 3;
BA_ "GenSigStartValue" SG_ 2589284072 GW_Komponentenfehler_52 2;
BA_ "GenSigSwitchedByIgnition" SG_ 2589284072 GW_Komponentenfehler_52 0;
BA_ "GenSigSendType" SG_ 2589284072 GW_Komponentenfehler_53 3;
BA_ "GenSigStartValue" SG_ 2589284072 GW_Komponentenfehler_53 2;
BA_ "GenSigSwitchedByIgnition" SG_ 2589284072 GW_Komponentenfehler_53 0;
BA_ "GenSigSendType" SG_ 2589284072 GW_Komponentenfehler_54 3;
BA_ "GenSigStartValue" SG_ 2589284072 GW_Komponentenfehler_54 2;
BA_ "GenSigSwitchedByIgnition" SG_ 2589284072 GW_Komponentenfehler_54 0;
BA_ "GenSigSendType" SG_ 2589284072 GW_Komponentenfehler_55 3;
BA_ "GenSigStartValue" SG_ 2589284072 GW_Komponentenfehler_55 2;
BA_ "GenSigSwitchedByIgnition" SG_ 2589284072 GW_Komponentenfehler_55 0;
BA_ "GenSigSendType" SG_ 2589284072 GW_Komponentenfehler_56 3;
BA_ "GenSigStartValue" SG_ 2589284072 GW_Komponentenfehler_56 2;
BA_ "GenSigSwitchedByIgnition" SG_ 2589284072 GW_Komponentenfehler_56 0;
BA_ "GenSigSendType" SG_ 2589284072 GW_Komponentenfehler_57 3;
BA_ "GenSigStartValue" SG_ 2589284072 GW_Komponentenfehler_57 2;
BA_ "GenSigSwitchedByIgnition" SG_ 2589284072 GW_Komponentenfehler_57 0;
BA_ "GenSigSendType" SG_ 2589284072 GW_Komponentenfehler_58 3;
BA_ "GenSigStartValue" SG_ 2589284072 GW_Komponentenfehler_58 2;
BA_ "GenSigSwitchedByIgnition" SG_ 2589284072 GW_Komponentenfehler_58 0;
BA_ "GenSigSendType" SG_ 2589284072 GW_Komponentenfehler_59 3;
BA_ "GenSigStartValue" SG_ 2589284072 GW_Komponentenfehler_59 2;
BA_ "GenSigSwitchedByIgnition" SG_ 2589284072 GW_Komponentenfehler_59 0;
BA_ "GenSigSendType" SG_ 2589284072 GW_Komponentenfehler_60 3;
BA_ "GenSigStartValue" SG_ 2589284072 GW_Komponentenfehler_60 2;
BA_ "GenSigSwitchedByIgnition" SG_ 2589284072 GW_Komponentenfehler_60 0;
BA_ "GenSigSendType" SG_ 2589284072 GW_Komponentenfehler_61 3;
BA_ "GenSigStartValue" SG_ 2589284072 GW_Komponentenfehler_61 2;
BA_ "GenSigSwitchedByIgnition" SG_ 2589284072 GW_Komponentenfehler_61 0;
BA_ "GenSigSendType" SG_ 2589284072 GW_Komponentenfehler_62 3;
BA_ "GenSigStartValue" SG_ 2589284072 GW_Komponentenfehler_62 2;
BA_ "GenSigSwitchedByIgnition" SG_ 2589284072 GW_Komponentenfehler_62 0;
BA_ "GenSigSendType" SG_ 2589284072 GW_Komponentenfehler_63 3;
BA_ "GenSigStartValue" SG_ 2589284072 GW_Komponentenfehler_63 2;
BA_ "GenSigSwitchedByIgnition" SG_ 2589284072 GW_Komponentenfehler_63 0;
BA_ "GenSigSendType" SG_ 2589284072 GW_Komponentenfehler_64 3;
BA_ "GenSigStartValue" SG_ 2589284072 GW_Komponentenfehler_64 2;
BA_ "GenSigSwitchedByIgnition" SG_ 2589284072 GW_Komponentenfehler_64 0;
BA_ "GenSigSendType" SG_ 2589284072 SOK_GW_CVN_Komp_03_Signatur 0;
BA_ "GenSigFuncType" SG_ 2589284072 SOK_GW_CVN_Komp_03_Signatur 15;
BA_ "GenSigSwitchedByIgnition" SG_ 2589284072 SOK_GW_CVN_Komp_03_Signatur 0;
BA_ "GenSigSendType" SG_ 1452 HVEM_Energie_Klima_Vorgabe 0;
BA_ "GenSigStartValue" SG_ 1452 HVEM_Energie_Klima_Vorgabe 254;
BA_ "GenSigSwitchedByIgnition" SG_ 1452 HVEM_Energie_Klima_Vorgabe 0;
BA_ "Fehlerwert" SG_ 1452 HVEM_Energie_Klima_Vorgabe 255;
BA_ "GenSigSendType" SG_ 1452 HVEM_Energie_Klima_Vorgabe_HighR 0;
BA_ "GenSigStartValue" SG_ 1452 HVEM_Energie_Klima_Vorgabe_HighR 6;
BA_ "GenSigSwitchedByIgnition" SG_ 1452 HVEM_Energie_Klima_Vorgabe_HighR 0;
BA_ "Fehlerwert" SG_ 1452 HVEM_Energie_Klima_Vorgabe_HighR 7;
BA_ "GenSigSendType" SG_ 1452 HVEM_HV_Anf 0;
BA_ "GenSigSwitchedByIgnition" SG_ 1452 HVEM_HV_Anf 0;
BA_ "GenSigSendType" SG_ 1452 HVEM_HVK_Aktivitaet 0;
BA_ "GenSigStartValue" SG_ 1452 HVEM_HVK_Aktivitaet 2;
BA_ "GenSigSwitchedByIgnition" SG_ 1452 HVEM_HVK_Aktivitaet 0;
BA_ "GenSigSendType" SG_ 1452 HVEM_IstLeistungNA 0;
BA_ "GenSigStartValue" SG_ 1452 HVEM_IstLeistungNA 510;
BA_ "GenSigSwitchedByIgnition" SG_ 1452 HVEM_IstLeistungNA 0;
BA_ "Fehlerwert" SG_ 1452 HVEM_IstLeistungNA 511;
BA_ "GenSigSendType" SG_ 1452 HVEM_IstStrom_HVVerbraucher 0;
BA_ "GenSigStartValue" SG_ 1452 HVEM_IstStrom_HVVerbraucher 4094;
BA_ "GenSigSwitchedByIgnition" SG_ 1452 HVEM_IstStrom_HVVerbraucher 0;
BA_ "Fehlerwert" SG_ 1452 HVEM_IstStrom_HVVerbraucher 4095;
BA_ "GenSigSendType" SG_ 1452 HVEM_Leistung_Klima_Vorgabe 0;
BA_ "GenSigStartValue" SG_ 1452 HVEM_Leistung_Klima_Vorgabe 254;
BA_ "GenSigSwitchedByIgnition" SG_ 1452 HVEM_Leistung_Klima_Vorgabe 0;
BA_ "Fehlerwert" SG_ 1452 HVEM_Leistung_Klima_Vorgabe 255;
BA_ "GenSigSendType" SG_ 1452 HVEM_MO_MaxLeistungIgnoriert 0;
BA_ "GenSigSwitchedByIgnition" SG_ 1452 HVEM_MO_MaxLeistungIgnoriert 0;
BA_ "GenSigSendType" SG_ 1452 HVEM_Nutzbare_Energie 0;
BA_ "GenSigStartValue" SG_ 1452 HVEM_Nutzbare_Energie 2046;
BA_ "GenSigSwitchedByIgnition" SG_ 1452 HVEM_Nutzbare_Energie 0;
BA_ "Fehlerwert" SG_ 1452 HVEM_Nutzbare_Energie 2047;
BA_ "GenSigSendType" SG_ 1452 HVEM_NVEM_Leistungsvorgabe 0;
BA_ "GenSigStartValue" SG_ 1452 HVEM_NVEM_Leistungsvorgabe 126;
BA_ "GenSigSwitchedByIgnition" SG_ 1452 HVEM_NVEM_Leistungsvorgabe 0;
BA_ "Fehlerwert" SG_ 1452 HVEM_NVEM_Leistungsvorgabe 127;
BA_ "GenSigSendType" SG_ 1452 HVEM_Pruefpuls_Anf 0;
BA_ "GenSigStartValue" SG_ 1452 HVEM_Pruefpuls_Anf 3;
BA_ "GenSigSwitchedByIgnition" SG_ 1452 HVEM_Pruefpuls_Anf 0;
BA_ "GenSigSendType" SG_ 1385 HVEM_Abschaltstatus 3;
BA_ "GenSigStartValue" SG_ 1385 HVEM_Abschaltstatus 7;
BA_ "GenSigSwitchedByIgnition" SG_ 1385 HVEM_Abschaltstatus 0;
BA_ "GenSigSendType" SG_ 1385 HVEM_Anf_ReichweiteNV 3;
BA_ "GenSigSwitchedByIgnition" SG_ 1385 HVEM_Anf_ReichweiteNV 0;
BA_ "Fehlerwert" SG_ 1385 HVEM_Anf_ReichweiteNV 3;
BA_ "GenSigSendType" SG_ 1385 HVEM_Betriebsart 0;
BA_ "GenSigSwitchedByIgnition" SG_ 1385 HVEM_Betriebsart 0;
BA_ "GenSigSendType" SG_ 1385 HVEM_DCDC_Freigabe 0;
BA_ "GenSigSwitchedByIgnition" SG_ 1385 HVEM_DCDC_Freigabe 0;
BA_ "GenSigSendType" SG_ 1385 HVEM_FreigabeBattHeizung 3;
BA_ "GenSigSwitchedByIgnition" SG_ 1385 HVEM_FreigabeBattHeizung 0;
BA_ "Fehlerwert" SG_ 1385 HVEM_FreigabeBattHeizung 3;
BA_ "GenSigSendType" SG_ 1385 HVEM_FreigabeKlimatisierung 3;
BA_ "GenSigStartValue" SG_ 1385 HVEM_FreigabeKlimatisierung 2;
BA_ "GenSigSwitchedByIgnition" SG_ 1385 HVEM_FreigabeKlimatisierung 0;
BA_ "Fehlerwert" SG_ 1385 HVEM_FreigabeKlimatisierung 3;
BA_ "GenSigSendType" SG_ 1385 HVEM_KlimaMaxHVStrom 3;
BA_ "GenSigSwitchedByIgnition" SG_ 1385 HVEM_KlimaMaxHVStrom 0;
BA_ "GenSigSendType" SG_ 1385 HVEM_Ladesteckerentr_Anf 3;
BA_ "GenSigSwitchedByIgnition" SG_ 1385 HVEM_Ladesteckerentr_Anf 0;
BA_ "GenSigSendType" SG_ 1385 HVEM_Leistung_Bat_Kond_Vorgabe 0;
BA_ "GenSigStartValue" SG_ 1385 HVEM_Leistung_Bat_Kond_Vorgabe 254;
BA_ "GenSigSwitchedByIgnition" SG_ 1385 HVEM_Leistung_Bat_Kond_Vorgabe 0;
BA_ "GenSigSendType" SG_ 1385 HVEM_LeistungsAnf 3;
BA_ "GenSigSwitchedByIgnition" SG_ 1385 HVEM_LeistungsAnf 0;
BA_ "GenSigSendType" SG_ 1385 HVEM_MinLeistungNA_Anf 3;
BA_ "GenSigStartValue" SG_ 1385 HVEM_MinLeistungNA_Anf 510;
BA_ "GenSigSwitchedByIgnition" SG_ 1385 HVEM_MinLeistungNA_Anf 0;
BA_ "GenSigSendType" SG_ 1385 HVEM_Nachlad_Status 3;
BA_ "GenSigStartValue" SG_ 1385 HVEM_Nachlad_Status 3;
BA_ "GenSigSwitchedByIgnition" SG_ 1385 HVEM_Nachlad_Status 0;
BA_ "GenSigSendType" SG_ 1385 HVEM_Nachladen_Anf 3;
BA_ "GenSigSwitchedByIgnition" SG_ 1385 HVEM_Nachladen_Anf 0;
BA_ "GenSigSendType" SG_ 1385 HVEM_NVLeistungEmpf 3;
BA_ "GenSigSwitchedByIgnition" SG_ 1385 HVEM_NVLeistungEmpf 0;
BA_ "GenSigSendType" SG_ 1385 HVEM_Text_1 3;
BA_ "GenSigSwitchedByIgnition" SG_ 1385 HVEM_Text_1 0;
BA_ "GenSigSendType" SG_ 1385 HVEM_WunschLeistungNA_Anf 3;
BA_ "GenSigStartValue" SG_ 1385 HVEM_WunschLeistungNA_Anf 510;
BA_ "GenSigSwitchedByIgnition" SG_ 1385 HVEM_WunschLeistungNA_Anf 0;
BA_ "GenSigSendType" SG_ 1385 HVEM_ZusatzMinLeistungNA_Anf 3;
BA_ "GenSigStartValue" SG_ 1385 HVEM_ZusatzMinLeistungNA_Anf 510;
BA_ "GenSigSwitchedByIgnition" SG_ 1385 HVEM_ZusatzMinLeistungNA_Anf 0;
BA_ "GenSigSendType" SG_ 1283 HV_Bordnetz_aktiv 3;
BA_ "GenSigSwitchedByIgnition" SG_ 1283 HV_Bordnetz_aktiv 0;
BA_ "GenSigSendType" SG_ 1283 HV_Bordnetz_Fehler 3;
BA_ "GenSigSwitchedByIgnition" SG_ 1283 HV_Bordnetz_Fehler 0;
BA_ "Fehlerwert" SG_ 1283 HV_Bordnetz_Fehler 1;
BA_ "GenSigSendType" SG_ 1283 HVK_01_BZ 0;
BA_ "GenSigFuncType" SG_ 1283 HVK_01_BZ 1;
BA_ "GenSigSwitchedByIgnition" SG_ 1283 HVK_01_BZ 0;
BA_ "GenSigSendType" SG_ 1283 HVK_01_CRC 0;
BA_ "GenSigFuncType" SG_ 1283 HVK_01_CRC 2;
BA_ "GenSigSwitchedByIgnition" SG_ 1283 HVK_01_CRC 0;
BA_ "GenSigSendType" SG_ 1283 HVK_AktiveEntladung_Anf 3;
BA_ "GenSigSwitchedByIgnition" SG_ 1283 HVK_AktiveEntladung_Anf 0;
BA_ "GenSigSendType" SG_ 1283 HVK_BMS_Sollmodus 3;
BA_ "GenSigStartValue" SG_ 1283 HVK_BMS_Sollmodus 7;
BA_ "GenSigSwitchedByIgnition" SG_ 1283 HVK_BMS_Sollmodus 0;
BA_ "GenSigSendType" SG_ 1283 HVK_DCDC_Sollmodus 3;
BA_ "GenSigStartValue" SG_ 1283 HVK_DCDC_Sollmodus 7;
BA_ "GenSigSwitchedByIgnition" SG_ 1283 HVK_DCDC_Sollmodus 0;
BA_ "GenSigSendType" SG_ 1283 HVK_EKK_Sollmodus 3;
BA_ "GenSigStartValue" SG_ 1283 HVK_EKK_Sollmodus 7;
BA_ "GenSigSwitchedByIgnition" SG_ 1283 HVK_EKK_Sollmodus 0;
BA_ "GenSigSendType" SG_ 1283 HVK_Gesamtst_Spgfreiheit 0;
BA_ "GenSigSwitchedByIgnition" SG_ 1283 HVK_Gesamtst_Spgfreiheit 0;
BA_ "Fehlerwert" SG_ 1283 HVK_Gesamtst_Spgfreiheit 3;
BA_ "GenSigSendType" SG_ 1283 HVK_HV_Netz_Warnungen 3;
BA_ "GenSigSwitchedByIgnition" SG_ 1283 HVK_HV_Netz_Warnungen 0;
BA_ "GenSigSendType" SG_ 1283 HVK_HVEM_Freigabe 3;
BA_ "GenSigStartValue" SG_ 1283 HVK_HVEM_Freigabe 2;
BA_ "GenSigSwitchedByIgnition" SG_ 1283 HVK_HVEM_Freigabe 0;
BA_ "GenSigSendType" SG_ 1283 HVK_HVLM_Sollmodus 3;
BA_ "GenSigStartValue" SG_ 1283 HVK_HVLM_Sollmodus 7;
BA_ "GenSigSwitchedByIgnition" SG_ 1283 HVK_HVLM_Sollmodus 0;
BA_ "GenSigSendType" SG_ 1283 HVK_HVPTC_Sollmodus 3;
BA_ "GenSigStartValue" SG_ 1283 HVK_HVPTC_Sollmodus 7;
BA_ "GenSigSwitchedByIgnition" SG_ 1283 HVK_HVPTC_Sollmodus 0;
BA_ "GenSigSendType" SG_ 1283 HVK_Iso_Messung_Start 0;
BA_ "GenSigSwitchedByIgnition" SG_ 1283 HVK_Iso_Messung_Start 0;
BA_ "GenSigSendType" SG_ 1283 HVK_Istmodus_Anf 3;
BA_ "GenSigSwitchedByIgnition" SG_ 1283 HVK_Istmodus_Anf 0;
BA_ "GenSigSendType" SG_ 1283 HVK_Ladebereit 3;
BA_ "GenSigSwitchedByIgnition" SG_ 1283 HVK_Ladebereit 0;
BA_ "GenSigSendType" SG_ 1283 HVK_Notabschaltung_Anf 3;
BA_ "GenSigSwitchedByIgnition" SG_ 1283 HVK_Notabschaltung_Anf 0;
BA_ "GenSigSendType" SG_ 1283 HVK_PPulsFreigabe 0;
BA_ "GenSigStartValue" SG_ 1283 HVK_PPulsFreigabe 3;
BA_ "GenSigSwitchedByIgnition" SG_ 1283 HVK_PPulsFreigabe 0;
BA_ "GenSigSendType" SG_ 1283 HVK_TN1_Sollmodus 3;
BA_ "GenSigStartValue" SG_ 1283 HVK_TN1_Sollmodus 3;
BA_ "GenSigSwitchedByIgnition" SG_ 1283 HVK_TN1_Sollmodus 0;
BA_ "GenSigSendType" SG_ 1283 HVK_Vorladung_aktiv 3;
BA_ "GenSigSwitchedByIgnition" SG_ 1283 HVK_Vorladung_aktiv 0;
BA_ "GenSigSendType" SG_ 2331595857 HVK_BMS_DC_Ladeschuetze_Soll 0;
BA_ "GenSigStartValue" SG_ 2331595857 HVK_BMS_DC_Ladeschuetze_Soll 6;
BA_ "GenSigSwitchedByIgnition" SG_ 2331595857 HVK_BMS_DC_Ladeschuetze_Soll 0;
BA_ "GenSigSendType" SG_ 2331595857 HVK_BMS_Hauptschuetze_Soll 0;
BA_ "GenSigStartValue" SG_ 2331595857 HVK_BMS_Hauptschuetze_Soll 6;
BA_ "GenSigSwitchedByIgnition" SG_ 2331595857 HVK_BMS_Hauptschuetze_Soll 0;
BA_ "GenSigSendType" SG_ 2331595857 HVK_DC_PruefpulsStatus 3;
BA_ "GenSigStartValue" SG_ 2331595857 HVK_DC_PruefpulsStatus 3;
BA_ "GenSigSwitchedByIgnition" SG_ 2331595857 HVK_DC_PruefpulsStatus 0;
BA_ "GenSigSendType" SG_ 2463978813 HVL_01_BZ 0;
BA_ "GenSigFuncType" SG_ 2463978813 HVL_01_BZ 1;
BA_ "GenSigSwitchedByIgnition" SG_ 2463978813 HVL_01_BZ 0;
BA_ "GenSigSendType" SG_ 2463978813 HVL_01_CRC 0;
BA_ "GenSigFuncType" SG_ 2463978813 HVL_01_CRC 2;
BA_ "GenSigSwitchedByIgnition" SG_ 2463978813 HVL_01_CRC 0;
BA_ "GenSigSendType" SG_ 2463978813 HVL_HVK_Fehler_DCAbschaltung 0;
BA_ "GenSigSwitchedByIgnition" SG_ 2463978813 HVL_HVK_Fehler_DCAbschaltung 0;
BA_ "GenSigSendType" SG_ 2463978813 HVL_Kuehltemperatur 0;
BA_ "GenSigStartValue" SG_ 2463978813 HVL_Kuehltemperatur 254;
BA_ "GenSigSwitchedByIgnition" SG_ 2463978813 HVL_Kuehltemperatur 0;
BA_ "Fehlerwert" SG_ 2463978813 HVL_Kuehltemperatur 255;
BA_ "GenSigSendType" SG_ 2463978813 HVL_LadeAnforderung 3;
BA_ "GenSigSwitchedByIgnition" SG_ 2463978813 HVL_LadeAnforderung 0;
BA_ "GenSigSendType" SG_ 2463978813 HVL_OBG_Typ_verbaut 0;
BA_ "GenSigStartValue" SG_ 2463978813 HVL_OBG_Typ_verbaut 7;
BA_ "GenSigSwitchedByIgnition" SG_ 2463978813 HVL_OBG_Typ_verbaut 0;
BA_ "GenSigSendType" SG_ 2463978813 HVL_OCC_IstModus 0;
BA_ "GenSigStartValue" SG_ 2463978813 HVL_OCC_IstModus 6;
BA_ "GenSigSwitchedByIgnition" SG_ 2463978813 HVL_OCC_IstModus 0;
BA_ "Fehlerwert" SG_ 2463978813 HVL_OCC_IstModus 7;
BA_ "GenSigSendType" SG_ 2463978813 HVL_Status_EoHVL 0;
BA_ "GenSigSwitchedByIgnition" SG_ 2463978813 HVL_Status_EoHVL 0;
BA_ "Fehlerwert" SG_ 2463978813 HVL_Status_EoHVL 3;
BA_ "GenSigSendType" SG_ 2463978813 HVL_Status_Spgfreiheit 0;
BA_ "GenSigSwitchedByIgnition" SG_ 2463978813 HVL_Status_Spgfreiheit 0;
BA_ "Fehlerwert" SG_ 2463978813 HVL_Status_Spgfreiheit 3;
BA_ "GenSigSendType" SG_ 2463978813 HVL_Steckerstatus 0;
BA_ "GenSigSwitchedByIgnition" SG_ 2463978813 HVL_Steckerstatus 0;
BA_ "Fehlerwert" SG_ 2463978813 HVL_Steckerstatus 3;
BA_ "GenSigSendType" SG_ 2463978689 HVLM_BCAM_Aktiv 0;
BA_ "GenSigSwitchedByIgnition" SG_ 2463978689 HVLM_BCAM_Aktiv 0;
BA_ "GenSigSendType" SG_ 2463978689 HVLM_BCCM_SoC 0;
BA_ "GenSigStartValue" SG_ 2463978689 HVLM_BCCM_SoC 6;
BA_ "GenSigSwitchedByIgnition" SG_ 2463978689 HVLM_BCCM_SoC 0;
BA_ "Fehlerwert" SG_ 2463978689 HVLM_BCCM_SoC 15;
BA_ "GenSigSendType" SG_ 2463978689 HVLM_BCCMKundenfreigabe_Status 0;
BA_ "GenSigSwitchedByIgnition" SG_ 2463978689 HVLM_BCCMKundenfreigabe_Status 0;
BA_ "GenSigSendType" SG_ 2463978689 HVLM_FreigabeLeistungNebenverbr 0;
BA_ "GenSigStartValue" SG_ 2463978689 HVLM_FreigabeLeistungNebenverbr 510;
BA_ "GenSigSwitchedByIgnition" SG_ 2463978689 HVLM_FreigabeLeistungNebenverbr 0;
BA_ "Fehlerwert" SG_ 2463978689 HVLM_FreigabeLeistungNebenverbr 511;
BA_ "GenSigSendType" SG_ 2463978689 HVLM_IstKonsWunschHVBat 0;
BA_ "GenSigSwitchedByIgnition" SG_ 2463978689 HVLM_IstKonsWunschHVBat 0;
BA_ "GenSigSendType" SG_ 2463978689 HVLM_IstStrom_02 0;
BA_ "GenSigStartValue" SG_ 2463978689 HVLM_IstStrom_02 8190;
BA_ "GenSigSwitchedByIgnition" SG_ 2463978689 HVLM_IstStrom_02 0;
BA_ "Fehlerwert" SG_ 2463978689 HVLM_IstStrom_02 8191;
BA_ "GenSigSendType" SG_ 2463978689 HVLM_SollSoCKonservierung 0;
BA_ "GenSigStartValue" SG_ 2463978689 HVLM_SollSoCKonservierung 126;
BA_ "GenSigSwitchedByIgnition" SG_ 2463978689 HVLM_SollSoCKonservierung 0;
BA_ "Fehlerwert" SG_ 2463978689 HVLM_SollSoCKonservierung 127;
BA_ "GenSigSendType" SG_ 626 HVLM_Aktive_Ladeart 3;
BA_ "GenSigSwitchedByIgnition" SG_ 626 HVLM_Aktive_Ladeart 0;
BA_ "Fehlerwert" SG_ 626 HVLM_Aktive_Ladeart 7;
BA_ "GenSigSendType" SG_ 626 HVLM_Anforderung_HMS 0;
BA_ "GenSigSwitchedByIgnition" SG_ 626 HVLM_Anforderung_HMS 0;
BA_ "GenSigSendType" SG_ 626 HVLM_AWC_VerbautStatus 0;
BA_ "GenSigSwitchedByIgnition" SG_ 626 HVLM_AWC_VerbautStatus 0;
BA_ "Fehlerwert" SG_ 626 HVLM_AWC_VerbautStatus 3;
BA_ "GenSigSendType" SG_ 626 HVLM_DC_Aufstartmodus 0;
BA_ "GenSigSwitchedByIgnition" SG_ 626 HVLM_DC_Aufstartmodus 0;
BA_ "GenSigSendType" SG_ 626 HVLM_Intensitaet_Lk1 3;
BA_ "GenSigStartValue" SG_ 626 HVLM_Intensitaet_Lk1 126;
BA_ "GenSigSwitchedByIgnition" SG_ 626 HVLM_Intensitaet_Lk1 0;
BA_ "Fehlerwert" SG_ 626 HVLM_Intensitaet_Lk1 127;
BA_ "GenSigSendType" SG_ 626 HVLM_Intensitaet_Lk2 3;
BA_ "GenSigStartValue" SG_ 626 HVLM_Intensitaet_Lk2 126;
BA_ "GenSigSwitchedByIgnition" SG_ 626 HVLM_Intensitaet_Lk2 0;
BA_ "Fehlerwert" SG_ 626 HVLM_Intensitaet_Lk2 127;
BA_ "GenSigSendType" SG_ 626 HVLM_Laden_ISO_Messung_Anf 0;
BA_ "GenSigStartValue" SG_ 626 HVLM_Laden_ISO_Messung_Anf 1;
BA_ "GenSigSwitchedByIgnition" SG_ 626 HVLM_Laden_ISO_Messung_Anf 0;
BA_ "GenSigSendType" SG_ 626 HVLM_Ladeszenario 3;
BA_ "GenSigStartValue" SG_ 626 HVLM_Ladeszenario 30;
BA_ "GenSigSwitchedByIgnition" SG_ 626 HVLM_Ladeszenario 0;
BA_ "Fehlerwert" SG_ 626 HVLM_Ladeszenario 31;
BA_ "GenSigSendType" SG_ 626 HVLM_Ladevorgang_Anf 0;
BA_ "GenSigSwitchedByIgnition" SG_ 626 HVLM_Ladevorgang_Anf 0;
BA_ "GenSigSendType" SG_ 626 HVLM_Parken_beibehalten_HMS 0;
BA_ "GenSigStartValue" SG_ 626 HVLM_Parken_beibehalten_HMS 2;
BA_ "GenSigSwitchedByIgnition" SG_ 626 HVLM_Parken_beibehalten_HMS 0;
BA_ "Fehlerwert" SG_ 626 HVLM_Parken_beibehalten_HMS 3;
BA_ "GenSigSendType" SG_ 626 HVLM_Pulsierstufe 3;
BA_ "GenSigSwitchedByIgnition" SG_ 626 HVLM_Pulsierstufe 0;
BA_ "GenSigSendType" SG_ 626 HVLM_Start_Pulserkennung 0;
BA_ "GenSigSwitchedByIgnition" SG_ 626 HVLM_Start_Pulserkennung 0;
BA_ "GenSigSendType" SG_ 626 HVLM_Steckerstatus_A 3;
BA_ "GenSigSwitchedByIgnition" SG_ 626 HVLM_Steckerstatus_A 0;
BA_ "Fehlerwert" SG_ 626 HVLM_Steckerstatus_A 7;
BA_ "GenSigSendType" SG_ 626 HVLM_Steckerstatus_B 3;
BA_ "GenSigSwitchedByIgnition" SG_ 626 HVLM_Steckerstatus_B 0;
BA_ "Fehlerwert" SG_ 626 HVLM_Steckerstatus_B 7;
BA_ "GenSigSendType" SG_ 626 HVLM_WakeUpZaehlerResetAnf 0;
BA_ "GenSigSwitchedByIgnition" SG_ 626 HVLM_WakeUpZaehlerResetAnf 0;
BA_ "GenSigSendType" SG_ 626 HVLM_ZustandLadeablauf 0;
BA_ "GenSigSwitchedByIgnition" SG_ 626 HVLM_ZustandLadeablauf 0;
BA_ "Fehlerwert" SG_ 626 HVLM_ZustandLadeablauf 3;
BA_ "GenSigSendType" SG_ 268 ImoCord_Auth_Aufforderung_WFS 3;
BA_ "GenSigSwitchedByIgnition" SG_ 268 ImoCord_Auth_Aufforderung_WFS 0;
BA_ "GenSigSwitchedByIgnition" SG_ 19 WFS_IMMO_GSG_CRC 0;
BA_ "GenSigSwitchedByIgnition" SG_ 19 WFS_IMMO_GSG_Data_0 0;
BA_ "GenSigSwitchedByIgnition" SG_ 19 WFS_IMMO_GSG_Data_1 0;
BA_ "GenSigSwitchedByIgnition" SG_ 19 WFS_IMMO_GSG_Data_2 0;
BA_ "GenSigSendType" SG_ 19 WFS_IMMO_GSG_Status 1;
BA_ "GenSigSwitchedByIgnition" SG_ 19 WFS_IMMO_GSG_Status 0;
BA_ "GenSigSwitchedByIgnition" SG_ 17 WFS_IMMO_MSG1_CRC 0;
BA_ "GenSigSwitchedByIgnition" SG_ 17 WFS_IMMO_MSG1_Data_0 0;
BA_ "GenSigSwitchedByIgnition" SG_ 17 WFS_IMMO_MSG1_Data_1 0;
BA_ "GenSigSwitchedByIgnition" SG_ 17 WFS_IMMO_MSG1_Data_2 0;
BA_ "GenSigSendType" SG_ 17 WFS_IMMO_MSG1_Status 1;
BA_ "GenSigSwitchedByIgnition" SG_ 17 WFS_IMMO_MSG1_Status 0;
BA_ "GenSigSwitchedByIgnition" SG_ 23 WFS_IMMO_MSG3_CRC 0;
BA_ "GenSigSwitchedByIgnition" SG_ 23 WFS_IMMO_MSG3_Data_0 0;
BA_ "GenSigSwitchedByIgnition" SG_ 23 WFS_IMMO_MSG3_Data_1 0;
BA_ "GenSigSwitchedByIgnition" SG_ 23 WFS_IMMO_MSG3_Data_2 0;
BA_ "GenSigSendType" SG_ 23 WFS_IMMO_MSG3_Status 1;
BA_ "GenSigSwitchedByIgnition" SG_ 23 WFS_IMMO_MSG3_Status 0;
BA_ "GenSigSwitchedByIgnition" SG_ 25 WFS_IMMO_MSG4_CRC 0;
BA_ "GenSigSwitchedByIgnition" SG_ 25 WFS_IMMO_MSG4_Data_0 0;
BA_ "GenSigSwitchedByIgnition" SG_ 25 WFS_IMMO_MSG4_Data_1 0;
BA_ "GenSigSwitchedByIgnition" SG_ 25 WFS_IMMO_MSG4_Data_2 0;
BA_ "GenSigSendType" SG_ 25 WFS_IMMO_MSG4_Status 1;
BA_ "GenSigSwitchedByIgnition" SG_ 25 WFS_IMMO_MSG4_Status 0;
BA_ "GenSigSendType" SG_ 312 IPA_01_BZ 0;
BA_ "GenSigFuncType" SG_ 312 IPA_01_BZ 1;
BA_ "GenSigSwitchedByIgnition" SG_ 312 IPA_01_BZ 0;
BA_ "GenSigSendType" SG_ 312 IPA_01_CRC 0;
BA_ "GenSigFuncType" SG_ 312 IPA_01_CRC 2;
BA_ "GenSigSwitchedByIgnition" SG_ 312 IPA_01_CRC 0;
BA_ "GenSigSendType" SG_ 312 IPA_Fahrstufenwunsch 0;
BA_ "GenSigSwitchedByIgnition" SG_ 312 IPA_Fahrstufenwunsch 0;
BA_ "GenSigSendType" SG_ 312 IPA_Status 0;
BA_ "GenSigSwitchedByIgnition" SG_ 312 IPA_Status 0;
BA_ "GenSigSendType" SG_ 2527679583 IPA_02_BZ 0;
BA_ "GenSigFuncType" SG_ 2527679583 IPA_02_BZ 1;
BA_ "GenSigSwitchedByIgnition" SG_ 2527679583 IPA_02_BZ 0;
BA_ "GenSigSendType" SG_ 2527679583 IPA_02_CRC 0;
BA_ "GenSigFuncType" SG_ 2527679583 IPA_02_CRC 2;
BA_ "GenSigSwitchedByIgnition" SG_ 2527679583 IPA_02_CRC 0;
BA_ "GenSigActiveRepetitions" SG_ 2527679583 IPA_Akustik_PL_gefunden 5;
BA_ "GenSigSendType" SG_ 2527679583 IPA_Akustik_PL_gefunden 4;
BA_ "GenSigActiveRepetitions" SG_ 2527679583 IPA_Anf_Meldungen 5;
BA_ "GenSigSendType" SG_ 2527679583 IPA_Anf_Meldungen 4;
BA_ "GenSigSwitchedByIgnition" SG_ 2527679583 IPA_Anf_Meldungen 0;
BA_ "GenSigActiveRepetitions" SG_ 2527679583 IPA_PL_Anzeige_links 5;
BA_ "GenSigSendType" SG_ 2527679583 IPA_PL_Anzeige_links 4;
BA_ "GenSigActiveRepetitions" SG_ 2527679583 IPA_PL_Anzeige_rechts 5;
BA_ "GenSigSendType" SG_ 2527679583 IPA_PL_Anzeige_rechts 4;
BA_ "GenSigActiveRepetitions" SG_ 2527679583 Parken_aktives_System_02 5;
BA_ "GenSigSendType" SG_ 2527679583 Parken_aktives_System_02 4;
BA_ "GenSigSwitchedByIgnition" SG_ 2527679583 Parken_aktives_System_02 0;
BA_ "GenSigActiveRepetitions" SG_ 2527679583 Parken_Aktivierungslicht_Anf 5;
BA_ "GenSigSendType" SG_ 2527679583 Parken_Aktivierungslicht_Anf 4;
BA_ "GenSigSwitchedByIgnition" SG_ 2527679583 Parken_Aktivierungslicht_Anf 0;
BA_ "GenSigActiveRepetitions" SG_ 2527679583 Parken_Bestaetigungsblinken_Anf 5;
BA_ "GenSigSendType" SG_ 2527679583 Parken_Bestaetigungsblinken_Anf 4;
BA_ "GenSigSwitchedByIgnition" SG_ 2527679583 Parken_Bestaetigungsblinken_Anf 0;
BA_ "GenSigActiveRepetitions" SG_ 2527679583 Parken_Blinker_li_Anf 5;
BA_ "GenSigSendType" SG_ 2527679583 Parken_Blinker_li_Anf 4;
BA_ "GenSigSwitchedByIgnition" SG_ 2527679583 Parken_Blinker_li_Anf 0;
BA_ "GenSigActiveRepetitions" SG_ 2527679583 Parken_Blinker_re_Anf 5;
BA_ "GenSigSendType" SG_ 2527679583 Parken_Blinker_re_Anf 4;
BA_ "GenSigSwitchedByIgnition" SG_ 2527679583 Parken_Blinker_re_Anf 0;
BA_ "GenSigActiveRepetitions" SG_ 2527679583 Parken_Fahrbereitschaftlicht_Anf 5;
BA_ "GenSigSendType" SG_ 2527679583 Parken_Fahrbereitschaftlicht_Anf 4;
BA_ "GenSigActiveRepetitions" SG_ 2527679583 Parken_Fahrerhinweise_Anf 5;
BA_ "GenSigSendType" SG_ 2527679583 Parken_Fahrerhinweise_Anf 4;
BA_ "GenSigSwitchedByIgnition" SG_ 2527679583 Parken_Fahrerhinweise_Anf 0;
BA_ "GenSigActiveRepetitions" SG_ 2527679583 Parken_Fahrtrichtungslicht_Anf 5;
BA_ "GenSigSendType" SG_ 2527679583 Parken_Fahrtrichtungslicht_Anf 4;
BA_ "GenSigActiveRepetitions" SG_ 2527679583 Parken_FFB_LED_Anf 5;
BA_ "GenSigSendType" SG_ 2527679583 Parken_FFB_LED_Anf 4;
BA_ "GenSigActiveRepetitions" SG_ 2527679583 Parken_Lichtnachlauf_Anf 5;
BA_ "GenSigSendType" SG_ 2527679583 Parken_Lichtnachlauf_Anf 4;
BA_ "GenSigActiveRepetitions" SG_ 2527679583 Parken_Lichtsteuerung_Anf 5;
BA_ "GenSigSendType" SG_ 2527679583 Parken_Lichtsteuerung_Anf 4;
BA_ "GenSigSwitchedByIgnition" SG_ 2527679583 Parken_Lichtsteuerung_Anf 0;
BA_ "GenSigActiveRepetitions" SG_ 2527679583 Parken_Schluesselsuche_Anf 5;
BA_ "GenSigSendType" SG_ 2527679583 Parken_Schluesselsuche_Anf 4;
BA_ "GenSigActiveRepetitions" SG_ 2527679583 Parken_Seitenspiegel_Anf 5;
BA_ "GenSigSendType" SG_ 2527679583 Parken_Seitenspiegel_Anf 4;
BA_ "GenSigActiveRepetitions" SG_ 2527679583 Parken_Wegfahrsperren_Anf 5;
BA_ "GenSigSendType" SG_ 2527679583 Parken_Wegfahrsperren_Anf 4;
BA_ "GenSigActiveRepetitions" SG_ 2527679583 Parken_ZR_Sondermodus_Anf 5;
BA_ "GenSigSendType" SG_ 2527679583 Parken_ZR_Sondermodus_Anf 4;
BA_ "GenSigSwitchedByIgnition" SG_ 2527679583 Parken_ZR_Sondermodus_Anf 0;
BA_ "GenSigActiveRepetitions" SG_ 2527679583 Parken_ZV_Schliessen 5;
BA_ "GenSigSendType" SG_ 2527679583 Parken_ZV_Schliessen 4;
BA_ "GenSigSendType" SG_ 2589283690 HVLE_eTM_max_Vorlauftemperatur 0;
BA_ "GenSigStartValue" SG_ 2589283690 HVLE_eTM_max_Vorlauftemperatur 254;
BA_ "GenSigSwitchedByIgnition" SG_ 2589283690 HVLE_eTM_max_Vorlauftemperatur 0;
BA_ "Fehlerwert" SG_ 2589283690 HVLE_eTM_max_Vorlauftemperatur 255;
BA_ "GenSigSendType" SG_ 2589283690 HVLE_Temperatur 0;
BA_ "GenSigStartValue" SG_ 2589283690 HVLE_Temperatur 254;
BA_ "Fehlerwert" SG_ 2589283690 HVLE_Temperatur 255;
BA_ "GenSigSendType" SG_ 2589283690 HVLE_ThermAuslastungsgrad 0;
BA_ "GenSigStartValue" SG_ 2589283690 HVLE_ThermAuslastungsgrad 254;
BA_ "GenSigSwitchedByIgnition" SG_ 2589283690 HVLE_ThermAuslastungsgrad 0;
BA_ "Fehlerwert" SG_ 2589283690 HVLE_ThermAuslastungsgrad 255;
BA_ "GenSigSendType" SG_ 2589283690 IPB_ThermAuslastungsgrad 0;
BA_ "GenSigSwitchedByIgnition" SG_ 2589283690 IPB_ThermAuslastungsgrad 0;
BA_ "Fehlerwert" SG_ 2589283690 IPB_ThermAuslastungsgrad 255;
BA_ "GenSigSendType" SG_ 2589283690 IPB_Wasser_TEMP_AUS 0;
BA_ "GenSigSwitchedByIgnition" SG_ 2589283690 IPB_Wasser_TEMP_AUS 0;
BA_ "Fehlerwert" SG_ 2589283690 IPB_Wasser_TEMP_AUS 255;
BA_ "GenSigSendType" SG_ 2589283690 IPB_Wasser_TEMP_EIN 0;
BA_ "GenSigSwitchedByIgnition" SG_ 2589283690 IPB_Wasser_TEMP_EIN 0;
BA_ "Fehlerwert" SG_ 2589283690 IPB_Wasser_TEMP_EIN 255;
BA_ "GenSigSendType" SG_ 2589283690 LAD_OBD_Lampe_Anf 0;
BA_ "GenSigSwitchedByIgnition" SG_ 2589283690 LAD_OBD_Lampe_Anf 0;
BA_ "GenSigSendType" SG_ 2589283690 OBDProtocol_Ladegeraet 0;
BA_ "GenSigStartValue" SG_ 2589283690 OBDProtocol_Ladegeraet 254;
BA_ "GenSigSwitchedByIgnition" SG_ 2589283690 OBDProtocol_Ladegeraet 0;
BA_ "Fehlerwert" SG_ 2589283690 OBDProtocol_Ladegeraet 255;
BA_ "GenSigSendType" SG_ 2589283690 TNV_Temperatur 0;
BA_ "GenSigSwitchedByIgnition" SG_ 2589283690 TNV_Temperatur 0;
BA_ "Fehlerwert" SG_ 2589283690 TNV_Temperatur 255;
BA_ "GenSigSendType" SG_ 2589283695 SOK_IPB_03_Signatur 0;
BA_ "GenSigFuncType" SG_ 2589283695 SOK_IPB_03_Signatur 15;
BA_ "GenSigSwitchedByIgnition" SG_ 2589283695 SOK_IPB_03_Signatur 0;
BA_ "GenSigSendType" SG_ 1892 ISO_AGA_Req_Data 3;
BA_ "GenSigFuncType" SG_ 1892 ISO_AGA_Req_Data 9;
BA_ "GenSigSendType" SG_ 1998 ISO_AGA_Resp_Data 3;
BA_ "GenSigFuncType" SG_ 1998 ISO_AGA_Resp_Data 9;
BA_ "GenSigSendType" SG_ 1792 ISO_ALL_01_Req_Data 3;
BA_ "GenSigFuncType" SG_ 1792 ISO_ALL_01_Req_Data 9;
BA_ "GenSigSwitchedByIgnition" SG_ 1792 ISO_ALL_01_Req_Data 0;
BA_ "GenSigSendType" SG_ 1820 ISO_Soundaktor_Req_Data 3;
BA_ "GenSigFuncType" SG_ 1820 ISO_Soundaktor_Req_Data 9;
BA_ "GenSigSendType" SG_ 1926 ISO_Soundaktor_Resp_Data 3;
BA_ "GenSigFuncType" SG_ 1926 ISO_Soundaktor_Resp_Data 9;
BA_ "GenSigSendType" SG_ 2549874812 ISOx_EMotor_01_Req_Data 3;
BA_ "GenSigFuncType" SG_ 2549874812 ISOx_EMotor_01_Req_Data 9;
BA_ "GenSigSwitchedByIgnition" SG_ 2549874812 ISOx_EMotor_01_Req_Data 0;
BA_ "GenSigSendType" SG_ 2621440124 ISOx_EMotor_01_Req_FD_Data 3;
BA_ "GenSigFuncType" SG_ 2621440124 ISOx_EMotor_01_Req_FD_Data 9;
BA_ "GenSigSwitchedByIgnition" SG_ 2621440124 ISOx_EMotor_01_Req_FD_Data 0;
BA_ "GenSigSendType" SG_ 2550005884 ISOx_EMotor_01_Resp_Data 3;
BA_ "GenSigFuncType" SG_ 2550005884 ISOx_EMotor_01_Resp_Data 9;
BA_ "GenSigSwitchedByIgnition" SG_ 2550005884 ISOx_EMotor_01_Resp_Data 0;
BA_ "GenSigSendType" SG_ 2621571196 ISOx_EMotor_01_Resp_FD_Data 3;
BA_ "GenSigFuncType" SG_ 2621571196 ISOx_EMotor_01_Resp_FD_Data 9;
BA_ "GenSigSwitchedByIgnition" SG_ 2621571196 ISOx_EMotor_01_Resp_FD_Data 0;
BA_ "GenSigSendType" SG_ 2549874872 ISOx_EMotor_02_Req_Data 3;
BA_ "GenSigFuncType" SG_ 2549874872 ISOx_EMotor_02_Req_Data 9;
BA_ "GenSigSwitchedByIgnition" SG_ 2549874872 ISOx_EMotor_02_Req_Data 0;
BA_ "GenSigSendType" SG_ 2621440184 ISOx_EMotor_02_Req_FD_Data 3;
BA_ "GenSigFuncType" SG_ 2621440184 ISOx_EMotor_02_Req_FD_Data 9;
BA_ "GenSigSwitchedByIgnition" SG_ 2621440184 ISOx_EMotor_02_Req_FD_Data 0;
BA_ "GenSigSendType" SG_ 2550005944 ISOx_EMotor_02_Resp_Data 3;
BA_ "GenSigFuncType" SG_ 2550005944 ISOx_EMotor_02_Resp_Data 9;
BA_ "GenSigSwitchedByIgnition" SG_ 2550005944 ISOx_EMotor_02_Resp_Data 0;
BA_ "GenSigSendType" SG_ 2621571256 ISOx_EMotor_02_Resp_FD_Data 3;
BA_ "GenSigFuncType" SG_ 2621571256 ISOx_EMotor_02_Resp_FD_Data 9;
BA_ "GenSigSwitchedByIgnition" SG_ 2621571256 ISOx_EMotor_02_Resp_FD_Data 0;
BA_ "GenSigSendType" SG_ 2621505536 ISOx_Funkt_Req_All_FD_Data 3;
BA_ "GenSigFuncType" SG_ 2621505536 ISOx_Funkt_Req_All_FD_Data 9;
BA_ "GenSigSwitchedByIgnition" SG_ 2621505536 ISOx_Funkt_Req_All_FD_Data 0;
BA_ "GenSigSendType" SG_ 2549874807 ISOx_Getriebe_01_Req_Data 3;
BA_ "GenSigFuncType" SG_ 2549874807 ISOx_Getriebe_01_Req_Data 9;
BA_ "GenSigSwitchedByIgnition" SG_ 2549874807 ISOx_Getriebe_01_Req_Data 0;
BA_ "GenSigSendType" SG_ 2621440119 ISOx_Getriebe_01_Req_FD_Data 3;
BA_ "GenSigFuncType" SG_ 2621440119 ISOx_Getriebe_01_Req_FD_Data 9;
BA_ "GenSigSwitchedByIgnition" SG_ 2621440119 ISOx_Getriebe_01_Req_FD_Data 0;
BA_ "GenSigSendType" SG_ 2550005879 ISOx_Getriebe_01_Resp_Data 3;
BA_ "GenSigFuncType" SG_ 2550005879 ISOx_Getriebe_01_Resp_Data 9;
BA_ "GenSigSwitchedByIgnition" SG_ 2550005879 ISOx_Getriebe_01_Resp_Data 0;
BA_ "GenSigSendType" SG_ 2621571191 ISOx_Getriebe_01_Resp_FD_Data 3;
BA_ "GenSigFuncType" SG_ 2621571191 ISOx_Getriebe_01_Resp_FD_Data 9;
BA_ "GenSigSwitchedByIgnition" SG_ 2621571191 ISOx_Getriebe_01_Resp_FD_Data 0;
BA_ "GenSigSendType" SG_ 2550399033 ISOx_LCU_SMH_Req_Data 3;
BA_ "GenSigFuncType" SG_ 2550399033 ISOx_LCU_SMH_Req_Data 9;
BA_ "GenSigSwitchedByIgnition" SG_ 2550399033 ISOx_LCU_SMH_Req_Data 0;
BA_ "GenSigSendType" SG_ 2621702201 ISOx_LCU_SMH_Req_FD_Data 3;
BA_ "GenSigFuncType" SG_ 2621702201 ISOx_LCU_SMH_Req_FD_Data 9;
BA_ "GenSigSwitchedByIgnition" SG_ 2621702201 ISOx_LCU_SMH_Req_FD_Data 0;
BA_REL_ "GenSigTimeoutTime" BU_SG_REL_ Gateway_Max SG_ 270 GE_Status_Kraftschluss 500;
BA_REL_ "GenSigTimeoutTime" BU_SG_REL_ Gateway_Max SG_ 270 GE_StartStopp_Info 500;
BA_REL_ "GenSigTimeoutTime" BU_SG_REL_ Gateway_Max SG_ 509 GE_Fahrprogramm 1000;
BA_REL_ "GenSigTimeoutTime" BU_SG_REL_ Gateway_Max SG_ 1283 HVK_BMS_Sollmodus 1000;
BA_REL_ "GenSigTimeoutTime" BU_SG_REL_ Gateway_Max SG_ 1283 HVK_HVLM_Sollmodus 1000;
BA_REL_ "GenSigTimeoutTime" BU_SG_REL_ Gateway_Max SG_ 1283 HV_Bordnetz_aktiv 1000;
BA_REL_ "GenSigTimeoutTime" BU_SG_REL_ Gateway_Max SG_ 1283 HV_Bordnetz_Fehler 1000;
BA_REL_ "GenSigTimeoutTime" BU_SG_REL_ Gateway_Max SG_ 1283 HVK_HVEM_Freigabe 1000;
BA_REL_ "GenSigTimeoutTime" BU_SG_REL_ Gateway_Max SG_ 1283 HVK_Notabschaltung_Anf 1000;
BA_REL_ "GenSigTimeoutTime" BU_SG_REL_ Gateway_Max SG_ 1283 HVK_Ladebereit 1000;
BA_REL_ "GenSigTimeoutTime" BU_SG_REL_ Getriebe_DQ SG_ 2589283397 GW_Komponentenfehler_13 5000;
BA_REL_ "GenSigTimeoutTime" BU_SG_REL_ Getriebe_DQ SG_ 312 IPA_01_CRC 1000;
BA_REL_ "GenSigTimeoutTime" BU_SG_REL_ Getriebe_DQ SG_ 312 IPA_01_BZ 1000;
BA_REL_ "GenSigTimeoutTime" BU_SG_REL_ Getriebe_DQ SG_ 312 IPA_Fahrstufenwunsch 1000;
BA_REL_ "GenSigTimeoutTime" BU_SG_REL_ Getriebe_DQ SG_ 312 IPA_Status 1000;
BA_REL_ "GenSigTimeoutTime" BU_SG_REL_ Getriebe_DQ SG_ 2527679583 Parken_aktives_System_02 5000;
BA_REL_ "GenSigTimeoutTime" BU_SG_REL_ Motor_konv SG_ 270 Getriebe_50_CRC 500;
BA_REL_ "GenSigTimeoutTime" BU_SG_REL_ Motor_konv SG_ 270 Getriebe_50_BZ 500;
BA_REL_ "GenSigTimeoutTime" BU_SG_REL_ Motor_konv SG_ 270 GE_MMom_Soll_02 500;
BA_REL_ "GenSigTimeoutTime" BU_SG_REL_ Motor_konv SG_ 270 GE_MMom_Vorhalt_02 500;
BA_REL_ "GenSigTimeoutTime" BU_SG_REL_ Motor_konv SG_ 270 GE_Uefkt 500;
BA_REL_ "GenSigTimeoutTime" BU_SG_REL_ Motor_konv SG_ 270 GE2_Fahrstufe 500;
BA_REL_ "GenSigTimeoutTime" BU_SG_REL_ Motor_konv SG_ 270 GE_Schaltablauf 500;
BA_REL_ "GenSigTimeoutTime" BU_SG_REL_ Motor_konv SG_ 270 GE_MMom_Status_02 500;
BA_REL_ "GenSigTimeoutTime" BU_SG_REL_ Motor_konv SG_ 270 GE_Status_Kraftschluss 500;
BA_REL_ "GenSigTimeoutTime" BU_SG_REL_ Motor_konv SG_ 270 GE_MMom_Status 500;
BA_REL_ "GenSigTimeoutTime" BU_SG_REL_ Motor_konv SG_ 270 GE_Freig_MMom_Vorhalt 500;
BA_REL_ "GenSigTimeoutTime" BU_SG_REL_ Motor_konv SG_ 270 GE_Verbot_Ausblendung 500;
BA_REL_ "GenSigTimeoutTime" BU_SG_REL_ Motor_konv SG_ 270 GE_Zielgang 500;
BA_REL_ "GenSigTimeoutTime" BU_SG_REL_ Motor_konv SG_ 270 GE_Fahrstufenwunsch 500;
BA_REL_ "GenSigTimeoutTime" BU_SG_REL_ Motor_konv SG_ 270 GE_Drehzahlmesser_Daempfung 500;
BA_REL_ "GenSigTimeoutTime" BU_SG_REL_ Motor_konv SG_ 270 GE_Schubabschalt_Unt 500;
BA_REL_ "GenSigTimeoutTime" BU_SG_REL_ Motor_konv SG_ 270 GE_Freigabe_Synchro 500;
BA_REL_ "GenSigTimeoutTime" BU_SG_REL_ Motor_konv SG_ 270 GE_Synchro_Wunschdrehz 500;
BA_REL_ "GenSigTimeoutTime" BU_SG_REL_ Motor_konv SG_ 270 GE_Synchro_Zeit 500;
BA_REL_ "GenSigTimeoutTime" BU_SG_REL_ Motor_konv SG_ 270 GE_Mom_Begr_Gradient 500;
BA_REL_ "GenSigTimeoutTime" BU_SG_REL_ Motor_konv SG_ 270 GE_Anheb_Solldrehz_Leerlauf 500;
BA_REL_ "GenSigTimeoutTime" BU_SG_REL_ Motor_konv SG_ 270 GE_Aufnahmemoment 500;
BA_REL_ "GenSigTimeoutTime" BU_SG_REL_ Motor_konv SG_ 270 GE_Synchro_Status_02 500;
BA_REL_ "GenSigTimeoutTime" BU_SG_REL_ Motor_konv SG_ 270 GE_StartStopp_Info 500;
BA_REL_ "GenSigTimeoutTime" BU_SG_REL_ Motor_konv SG_ 270 GE_Langfr_Schutzmom_02 500;
BA_REL_ "GenSigTimeoutTime" BU_SG_REL_ Motor_konv SG_ 270 GE_Verlustmoment 500;
BA_REL_ "GenSigTimeoutTime" BU_SG_REL_ Motor_konv SG_ 270 GE_Anf_Zylabsch 500;
BA_REL_ "GenSigTimeoutTime" BU_SG_REL_ Motor_konv SG_ 270 GE_Eingangsdrehz 500;
BA_REL_ "GenSigTimeoutTime" BU_SG_REL_ Motor_konv SG_ 270 GE_Notlauf 500;
BA_REL_ "GenSigTimeoutTime" BU_SG_REL_ Motor_konv SG_ 270 GE_Freig_Langfr_Schutzmom 500;
BA_REL_ "GenSigTimeoutTime" BU_SG_REL_ Motor_konv SG_ 270 GE_Radmoment 500;
BA_REL_ "GenSigTimeoutTime" BU_SG_REL_ Motor_konv SG_ 270 GE_Abtriebsdrehzahl 500;
BA_REL_ "GenSigTimeoutTime" BU_SG_REL_ Motor_konv SG_ 270 GE_Eingangswellengradient 500;
BA_REL_ "GenSigTimeoutTime" BU_SG_REL_ Motor_konv SG_ 509 Getriebe_51_CRC 1000;
BA_REL_ "GenSigTimeoutTime" BU_SG_REL_ Motor_konv SG_ 509 Getriebe_51_BZ 1000;
BA_REL_ "GenSigTimeoutTime" BU_SG_REL_ Motor_konv SG_ 509 GE_OBD_AbsperrVent 1000;
BA_REL_ "GenSigTimeoutTime" BU_SG_REL_ Motor_konv SG_ 509 GE_amax_moeglich 1000;
BA_REL_ "GenSigTimeoutTime" BU_SG_REL_ Motor_konv SG_ 509 GE_Freigabe_Verfallsinfo_WFS 1000;
BA_REL_ "GenSigTimeoutTime" BU_SG_REL_ Motor_konv SG_ 509 GE_Freigabe_Info_WFS 1000;
BA_REL_ "GenSigTimeoutTime" BU_SG_REL_ Motor_konv SG_ 509 GE_Sperr_Info_WFS 1000;
BA_REL_ "GenSigTimeoutTime" BU_SG_REL_ Motor_konv SG_ 509 GE_LaunchControl 1000;
BA_REL_ "GenSigTimeoutTime" BU_SG_REL_ Motor_konv SG_ 509 GE_Heizwunsch 1000;
BA_REL_ "GenSigTimeoutTime" BU_SG_REL_ Motor_konv SG_ 509 GE_OBD_Status 1000;
BA_REL_ "GenSigTimeoutTime" BU_SG_REL_ Motor_konv SG_ 509 GE_LFR_Adaption 1000;
BA_REL_ "GenSigTimeoutTime" BU_SG_REL_ Motor_konv SG_ 509 GE_Sumpftemperatur 1000;
BA_REL_ "GenSigTimeoutTime" BU_SG_REL_ Motor_konv SG_ 509 GE_Fahrprogramm 1000;
BA_REL_ "GenSigTimeoutTime" BU_SG_REL_ Motor_konv SG_ 509 GE_TippZustand 1000;
BA_REL_ "GenSigTimeoutTime" BU_SG_REL_ Motor_konv SG_ 509 GE_Freilauf_Status 1000;
BA_REL_ "GenSigTimeoutTime" BU_SG_REL_ Motor_konv SG_ 509 GE_Anschleppstart_Freigabe 1000;
BA_REL_ "GenSigTimeoutTime" BU_SG_REL_ Motor_konv SG_ 2589283964 GE_OBD_Status_Auth 5000;
BA_REL_ "GenSigTimeoutTime" BU_SG_REL_ Motor_konv SG_ 2589283964 GE_Indc_StChk 5000;
BA_REL_ "GenSigTimeoutTime" BU_SG_REL_ Motor_konv SG_ 2589283964 GE_Indc_StFail 5000;
BA_REL_ "GenSigTimeoutTime" BU_SG_REL_ Motor_konv SG_ 2589283964 SOK_Getriebe_52_Signatur 5000;
BA_REL_ "GenSigTimeoutTime" BU_SG_REL_ Motor_konv SG_ 299 GRA_ACC_01_CRC 500;
BA_REL_ "GenSigTimeoutTime" BU_SG_REL_ Motor_konv SG_ 299 GRA_ACC_01_BZ 500;
BA_REL_ "GenSigTimeoutTime" BU_SG_REL_ Motor_konv SG_ 299 GRA_Hauptschalter 500;
BA_REL_ "GenSigTimeoutTime" BU_SG_REL_ Motor_konv SG_ 299 GRA_Abbrechen 500;
BA_REL_ "GenSigTimeoutTime" BU_SG_REL_ Motor_konv SG_ 299 GRA_Typ_Hauptschalter 500;
BA_REL_ "GenSigTimeoutTime" BU_SG_REL_ Motor_konv SG_ 299 GRA_Limiter 500;
BA_REL_ "GenSigTimeoutTime" BU_SG_REL_ Motor_konv SG_ 299 GRA_Tip_Setzen 500;
BA_REL_ "GenSigTimeoutTime" BU_SG_REL_ Motor_konv SG_ 299 GRA_Tip_Hoch 500;
BA_REL_ "GenSigTimeoutTime" BU_SG_REL_ Motor_konv SG_ 299 GRA_Tip_Runter 500;
BA_REL_ "GenSigTimeoutTime" BU_SG_REL_ Motor_konv SG_ 299 GRA_Tip_Wiederaufnahme 500;
BA_REL_ "GenSigTimeoutTime" BU_SG_REL_ Motor_konv SG_ 299 GRA_Verstellung_Zeitluecke 500;
BA_REL_ "GenSigTimeoutTime" BU_SG_REL_ Motor_konv SG_ 299 GRA_Codierung 500;
BA_REL_ "GenSigTimeoutTime" BU_SG_REL_ Motor_konv SG_ 299 GRA_Fehler 500;
BA_REL_ "GenSigTimeoutTime" BU_SG_REL_ Motor_konv SG_ 299 GRA_LIM_Taste_verfuegbar 500;
BA_REL_ "GenSigTimeoutTime" BU_SG_REL_ Motor_konv SG_ 299 GRA_Tip_Stufe_2 500;
BA_REL_ "GenSigTimeoutTime" BU_SG_REL_ Motor_konv SG_ 299 GRA_Typ_Bedienteil 500;
BA_REL_ "GenSigTimeoutTime" BU_SG_REL_ Motor_konv SG_ 299 GRA_PIT_Limiter 500;
BA_REL_ "GenSigTimeoutTime" BU_SG_REL_ Motor_konv SG_ 2589283454 SOK_GW_CVN_Komp_02_Signatur 5000;
BA_REL_ "GenSigTimeoutTime" BU_SG_REL_ Motor_konv SG_ 2589283397 GW_CAL_ID_Index_01 5000;
BA_REL_ "GenSigTimeoutTime" BU_SG_REL_ Motor_konv SG_ 2589283397 GW_CAL_ID_Index_02 5000;
BA_REL_ "GenSigTimeoutTime" BU_SG_REL_ Motor_konv SG_ 2589283397 GW_CAL_ID_Index_03 5000;
BA_REL_ "GenSigTimeoutTime" BU_SG_REL_ Motor_konv SG_ 2589283397 GW_CAL_ID_Index_04 5000;
BA_REL_ "GenSigTimeoutTime" BU_SG_REL_ Motor_konv SG_ 2589283397 GW_CAL_ID_Index_05 5000;
BA_REL_ "GenSigTimeoutTime" BU_SG_REL_ Motor_konv SG_ 2589283397 GW_CAL_ID_Index_06 5000;
BA_REL_ "GenSigTimeoutTime" BU_SG_REL_ Motor_konv SG_ 2589283397 GW_CAL_ID_Index_07 5000;
BA_REL_ "GenSigTimeoutTime" BU_SG_REL_ Motor_konv SG_ 2589283397 GW_CAL_ID_Index_08 5000;
BA_REL_ "GenSigTimeoutTime" BU_SG_REL_ Motor_konv SG_ 2589283397 GW_CAL_ID_Index_09 5000;
BA_REL_ "GenSigTimeoutTime" BU_SG_REL_ Motor_konv SG_ 2589283397 GW_CAL_ID_Index_10 5000;
BA_REL_ "GenSigTimeoutTime" BU_SG_REL_ Motor_konv SG_ 2589283397 GW_CAL_ID_Index_11 5000;
BA_REL_ "GenSigTimeoutTime" BU_SG_REL_ Motor_konv SG_ 2589283397 GW_CAL_ID_Index_12 5000;
BA_REL_ "GenSigTimeoutTime" BU_SG_REL_ Motor_konv SG_ 2589283397 GW_CAL_ID_Index_13 5000;
BA_REL_ "GenSigTimeoutTime" BU_SG_REL_ Motor_konv SG_ 2589283397 GW_CAL_ID_Index_14 5000;
BA_REL_ "GenSigTimeoutTime" BU_SG_REL_ Motor_konv SG_ 2589283397 GW_CAL_ID_Index_15 5000;
BA_REL_ "GenSigTimeoutTime" BU_SG_REL_ Motor_konv SG_ 2589283397 GW_CAL_ID_Index_16 5000;
BA_REL_ "GenSigTimeoutTime" BU_SG_REL_ Motor_konv SG_ 2589283397 GW_KomponentenFehler_01 5000;
BA_REL_ "GenSigTimeoutTime" BU_SG_REL_ Motor_konv SG_ 2589283397 GW_Komponentenfehler_02 5000;
BA_REL_ "GenSigTimeoutTime" BU_SG_REL_ Motor_konv SG_ 2589283397 GW_Komponentenfehler_03 5000;
BA_REL_ "GenSigTimeoutTime" BU_SG_REL_ Motor_konv SG_ 2589283397 GW_Komponentenfehler_04 5000;
BA_REL_ "GenSigTimeoutTime" BU_SG_REL_ Motor_konv SG_ 2589283397 GW_Komponentenfehler_05 5000;
BA_REL_ "GenSigTimeoutTime" BU_SG_REL_ Motor_konv SG_ 2589283397 GW_Komponentenfehler_06 5000;
BA_REL_ "GenSigTimeoutTime" BU_SG_REL_ Motor_konv SG_ 2589283397 GW_Komponentenfehler_07 5000;
BA_REL_ "GenSigTimeoutTime" BU_SG_REL_ Motor_konv SG_ 2589283397 GW_Komponentenfehler_08 5000;
BA_REL_ "GenSigTimeoutTime" BU_SG_REL_ Motor_konv SG_ 2589283397 GW_Komponentenfehler_09 5000;
BA_REL_ "GenSigTimeoutTime" BU_SG_REL_ Motor_konv SG_ 2589283397 GW_Komponentenfehler_10 5000;
BA_REL_ "GenSigTimeoutTime" BU_SG_REL_ Motor_konv SG_ 2589283397 GW_Komponentenfehler_11 5000;
BA_REL_ "GenSigTimeoutTime" BU_SG_REL_ Motor_konv SG_ 2589283397 GW_Komponentenfehler_12 5000;
BA_REL_ "GenSigTimeoutTime" BU_SG_REL_ Motor_konv SG_ 2589283397 GW_Komponentenfehler_13 5000;
BA_REL_ "GenSigTimeoutTime" BU_SG_REL_ Motor_konv SG_ 2589283397 GW_Komponentenfehler_14 5000;
BA_REL_ "GenSigTimeoutTime" BU_SG_REL_ Motor_konv SG_ 2589283397 GW_Komponentenfehler_15 5000;
BA_REL_ "GenSigTimeoutTime" BU_SG_REL_ Motor_konv SG_ 2589283397 GW_Komponentenfehler_16 5000;
BA_REL_ "GenSigTimeoutTime" BU_SG_REL_ Motor_konv SG_ 2589283397 GW_CVN 5000;
BA_REL_ "GenSigTimeoutTime" BU_SG_REL_ Motor_konv SG_ 2589283397 GW_Komponentenfehler_17 5000;
BA_REL_ "GenSigTimeoutTime" BU_SG_REL_ Motor_konv SG_ 2589283397 GW_Komponentenfehler_18 5000;
BA_REL_ "GenSigTimeoutTime" BU_SG_REL_ Motor_konv SG_ 2589283397 GW_Komponentenfehler_19 5000;
BA_REL_ "GenSigTimeoutTime" BU_SG_REL_ Motor_konv SG_ 2589283397 GW_Komponentenfehler_20 5000;
BA_REL_ "GenSigTimeoutTime" BU_SG_REL_ Motor_konv SG_ 2589283397 GW_Komponentenfehler_21 5000;
BA_REL_ "GenSigTimeoutTime" BU_SG_REL_ Motor_konv SG_ 2589283397 GW_Komponentenfehler_22 5000;
BA_REL_ "GenSigTimeoutTime" BU_SG_REL_ Motor_konv SG_ 2589283397 GW_Komponentenfehler_23 5000;
BA_REL_ "GenSigTimeoutTime" BU_SG_REL_ Motor_konv SG_ 2589283397 GW_Komponentenfehler_24 5000;
BA_REL_ "GenSigTimeoutTime" BU_SG_REL_ Motor_konv SG_ 2589283397 GW_Komponentenfehler_25 5000;
BA_REL_ "GenSigTimeoutTime" BU_SG_REL_ Motor_konv SG_ 2589283397 GW_Komponentenfehler_26 5000;
BA_REL_ "GenSigTimeoutTime" BU_SG_REL_ Motor_konv SG_ 2589283397 GW_Komponentenfehler_27 5000;
BA_REL_ "GenSigTimeoutTime" BU_SG_REL_ Motor_konv SG_ 2589283397 GW_Komponentenfehler_28 5000;
BA_REL_ "GenSigTimeoutTime" BU_SG_REL_ Motor_konv SG_ 2589283397 GW_Komponentenfehler_29 5000;
BA_REL_ "GenSigTimeoutTime" BU_SG_REL_ Motor_konv SG_ 2589283397 GW_Komponentenfehler_30 5000;
BA_REL_ "GenSigTimeoutTime" BU_SG_REL_ Motor_konv SG_ 2589283397 GW_Komponentenfehler_31 5000;
BA_REL_ "GenSigTimeoutTime" BU_SG_REL_ Motor_konv SG_ 2589283397 GW_Komponentenfehler_32 5000;
BA_REL_ "GenSigTimeoutTime" BU_SG_REL_ Motor_konv SG_ 2589283397 GW_Komponentenfehler_33 5000;
BA_REL_ "GenSigTimeoutTime" BU_SG_REL_ Motor_konv SG_ 2589283397 GW_Komponentenfehler_34 5000;
BA_REL_ "GenSigTimeoutTime" BU_SG_REL_ Motor_konv SG_ 2589283397 GW_Komponentenfehler_35 5000;
BA_REL_ "GenSigTimeoutTime" BU_SG_REL_ Motor_konv SG_ 2589283397 GW_Komponentenfehler_36 5000;
BA_REL_ "GenSigTimeoutTime" BU_SG_REL_ Motor_konv SG_ 2589283397 GW_Komponentenfehler_37 5000;
BA_REL_ "GenSigTimeoutTime" BU_SG_REL_ Motor_konv SG_ 2589283397 GW_Komponentenfehler_38 5000;
BA_REL_ "GenSigTimeoutTime" BU_SG_REL_ Motor_konv SG_ 2589283397 GW_Komponentenfehler_39 5000;
BA_REL_ "GenSigTimeoutTime" BU_SG_REL_ Motor_konv SG_ 2589283397 GW_Komponentenfehler_40 5000;
BA_REL_ "GenSigTimeoutTime" BU_SG_REL_ Motor_konv SG_ 2589283397 GW_Komponentenfehler_41 5000;
BA_REL_ "GenSigTimeoutTime" BU_SG_REL_ Motor_konv SG_ 2589283397 GW_Komponentenfehler_42 5000;
BA_REL_ "GenSigTimeoutTime" BU_SG_REL_ Motor_konv SG_ 2589283397 GW_Komponentenfehler_43 5000;
BA_REL_ "GenSigTimeoutTime" BU_SG_REL_ Motor_konv SG_ 2589283397 GW_Komponentenfehler_44 5000;
BA_REL_ "GenSigTimeoutTime" BU_SG_REL_ Motor_konv SG_ 2589283397 GW_Komponentenfehler_45 5000;
BA_REL_ "GenSigTimeoutTime" BU_SG_REL_ Motor_konv SG_ 2589283397 GW_Komponentenfehler_46 5000;
BA_REL_ "GenSigTimeoutTime" BU_SG_REL_ Motor_konv SG_ 2589283397 GW_Komponentenfehler_47 5000;
BA_REL_ "GenSigTimeoutTime" BU_SG_REL_ Motor_konv SG_ 2589283397 GW_Komponentenfehler_VLD 5000;
BA_REL_ "GenSigTimeoutTime" BU_SG_REL_ Motor_konv SG_ 2589283397 GW_CVN_VLD 5000;
BA_REL_ "GenSigTimeoutTime" BU_SG_REL_ Motor_konv SG_ 2589284072 GW_Komponentenfehler_48 5000;
BA_REL_ "GenSigTimeoutTime" BU_SG_REL_ Motor_konv SG_ 2589284072 GW_Komponentenfehler_49 5000;
BA_REL_ "GenSigTimeoutTime" BU_SG_REL_ Motor_konv SG_ 2589284072 GW_Komponentenfehler_50 5000;
BA_REL_ "GenSigTimeoutTime" BU_SG_REL_ Motor_konv SG_ 2589284072 GW_Komponentenfehler_51 5000;
BA_REL_ "GenSigTimeoutTime" BU_SG_REL_ Motor_konv SG_ 2589284072 GW_Komponentenfehler_52 5000;
BA_REL_ "GenSigTimeoutTime" BU_SG_REL_ Motor_konv SG_ 2589284072 GW_Komponentenfehler_53 5000;
BA_REL_ "GenSigTimeoutTime" BU_SG_REL_ Motor_konv SG_ 2589284072 GW_Komponentenfehler_54 5000;
BA_REL_ "GenSigTimeoutTime" BU_SG_REL_ Motor_konv SG_ 2589284072 GW_Komponentenfehler_55 5000;
BA_REL_ "GenSigTimeoutTime" BU_SG_REL_ Motor_konv SG_ 2589284072 GW_Komponentenfehler_56 5000;
BA_REL_ "GenSigTimeoutTime" BU_SG_REL_ Motor_konv SG_ 2589284072 GW_Komponentenfehler_57 5000;
BA_REL_ "GenSigTimeoutTime" BU_SG_REL_ Motor_konv SG_ 2589284072 GW_Komponentenfehler_58 5000;
BA_REL_ "GenSigTimeoutTime" BU_SG_REL_ Motor_konv SG_ 2589284072 GW_Komponentenfehler_59 5000;
BA_REL_ "GenSigTimeoutTime" BU_SG_REL_ Motor_konv SG_ 2589284072 GW_Komponentenfehler_60 5000;
BA_REL_ "GenSigTimeoutTime" BU_SG_REL_ Motor_konv SG_ 2589284072 GW_Komponentenfehler_61 5000;
BA_REL_ "GenSigTimeoutTime" BU_SG_REL_ Motor_konv SG_ 2589284072 GW_Komponentenfehler_62 5000;
BA_REL_ "GenSigTimeoutTime" BU_SG_REL_ Motor_konv SG_ 2589284072 GW_Komponentenfehler_63 5000;
BA_REL_ "GenSigTimeoutTime" BU_SG_REL_ Motor_konv SG_ 2589284072 GW_Komponentenfehler_64 5000;
BA_REL_ "GenSigTimeoutTime" BU_SG_REL_ Motor_konv SG_ 2589284072 SOK_GW_CVN_Komp_03_Signatur 5000;
BA_REL_ "GenSigTimeoutTime" BU_SG_REL_ Motor_konv SG_ 312 IPA_01_CRC 1000;
BA_REL_ "GenSigTimeoutTime" BU_SG_REL_ Motor_konv SG_ 312 IPA_01_BZ 1000;
BA_REL_ "GenSigTimeoutTime" BU_SG_REL_ Motor_konv SG_ 312 IPA_Status 1000;
BA_REL_ "GenSigTimeoutTime" BU_SG_REL_ Motor_konv SG_ 2527679583 Parken_aktives_System_02 5000;
VAL_ 270 GE_MMom_Soll_02 1022 "keine_Anforderung_Init" 1023 "Fehler" ;
VAL_ 270 GE_MMom_Vorhalt_02 1022 "Init" 1023 "Fehler" ;
VAL_ 270 GE_Uefkt 1023 "Fehler" ;
VAL_ 270 GE2_Fahrstufe 0 "Zwischenstellung" 1 "Init" 5 "Position_P" 6 "Position_R" 7 "Position_N" 8 "Position_D" 9 "Position_S" 10 "Effizienz" 13 "Tipp_in_S" 14 "Tipp_in_D" 15 "Fehler" ;
VAL_ 270 GE2_Ursache_Fahrstufe_N 0 "Fahrstufe_N_mit_Fahrerwunsch" 1 "Fahrstufe_N_ohne_Fahrerwunsch" ;
VAL_ 270 GE_Schaltablauf 0 "keine_Schaltung" 1 "Momentenueberschneidung" 2 "Befuellphase" 3 "Drehzahlueberfuehrung" ;
VAL_ 270 GE_Uefkt_unplausibel 0 "Uefkt_plausibel" 1 "Uefkt_unplausibel" ;
VAL_ 270 GE_MMom_Status_02 0 "kein_Eingriff" 1 "abs_reduzierender_Eingriff_auf_Gesamt_Antrieb_nur_schneller_Pfad" 2 "abs_erhoehender_Eingriff_auf_Gesamt_Antrieb" 3 "relativer_Eingriff_auf_Gesamt_Antrieb" 4 "relativer_Eingriff_auf_E_Maschine" 5 "abs_red_Eingr_auf_Gesamt_Antrieb_nur_Luftpfad" 6 "abs_red_Eingr_auf_Gesamt_Antrieb_Luft-_und_schnellen_Pfad" 7 "abs_Eingriff_auf_Gesamtantrieb_erhoehend_und_reduzierend" ;
VAL_ 270 GE_Status_Kraftschluss 0 "offen_kein_Kraftschluss" 1 "offen_mit_Kraftschluss" 2 "schlupfend_geregelt" 3 "abgesichert_offen_kein_Kraftschl" 4 "geschlossen_mit_Mikroschlupf" 5 "geschlossen_mit_Ueberanpressung" 6 "sonstige_Fehler" 7 "fehlerhaft_geschlossen" ;
VAL_ 270 GE_MMom_Status 0 "keine Anforderung" 1 "reduzierender Getriebeeingriff" 2 "erhöhender Getriebeeingriff" 3 "Änderung mit Sprung" ;
VAL_ 270 GE_Freig_MMom_Vorhalt 0 "nicht_freigegeben" 1 "freigegeben" ;
VAL_ 270 GE_Verbot_Ausblendung 0 "kein_Verbot" 1 "Verbot" ;
VAL_ 270 GE_Zielgang 0 "Gang P/N (ausgekuppelt)" 1 "Gang 1" 2 "Gang 2" 3 "Gang 3" 4 "Gang 4" 5 "Gang 5" 6 "Gang 6" 7 "Gang 7" 8 "Gang R" 11 "Gang 8" 12 "Gang 9" 13 "Gang10" 14 "Istgang nicht definiert" 15 "Fehler" ;
VAL_ 270 GE_Fahrstufenwunsch 0 "Zwischenstellung" 1 "Init" 5 "Position_P" 6 "Position_R" 7 "Position_N" 8 "Position_D" 9 "Position_S" 10 "Effizienz" 13 "Tipp_in_S" 14 "Tipp_in_D" 15 "Fehler" ;
VAL_ 270 GE_Drehzahlmesser_Daempfung 0 "normale Dämpfung" 1 "dynamische Dämpfung" ;
VAL_ 270 GE_Schubabschalt_Unt 0 "inaktiv" 1 "aktiv" ;
VAL_ 270 GE_Freigabe_Synchro 0 "inaktiv" 1 "aktiv" ;
VAL_ 270 GE_Synchro_Wunschdrehz 0 "Init_kein_Eingriff" 511 "Fehler" ;
VAL_ 270 GE_Synchro_Zeit 255 "Fehler" ;
VAL_ 270 GE_Mom_Begr_Gradient 255 "Init" ;
VAL_ 270 GE_Anheb_Solldrehz_Leerlauf 255 "Fehler" ;
VAL_ 270 GE_Aufnahmemoment 1022 "Init_bzw_Wert_nicht_ermittelbar" 1023 "Fehler" ;
VAL_ 270 GE_Synchro_Status_02 0 "kein_Eingriff" 1 "Eingr_Gesamtantrieb_Param1" 2 "Eingr_Gesamtantrieb_Param2" 3 "Eingr_Gesamtantrieb_Param3" 4 "Eingr_Gesamtantrieb_Param4" 5 "Eingr_auf_E-Maschine" 6 "Drehzahlbegrenzung" 7 "Eingr_Gesamtantrieb_Param5" 8 "Eingr_Gesamtantrieb_Param6" 9 "Eingr_Gesamtantrieb_Param7" 10 "Eingr_Gesamtantrieb_Param8" 11 "Vorgest_Einspritzausblendung" ;
VAL_ 270 GE_StartStopp_Info 0 "Motorlauf_nicht_notwendig_(Stoppfreigabe)" 1 "Motoranlauf_nicht_zwingend_notwendig_(Stoppverbot,keine_Startanforderung)" 2 "Motoranlauf_zwingend_notwendig_(Startanforderung)" 3 "Systemfehler" ;
VAL_ 270 GE_Langfr_Schutzmom_02 510 "Init" 511 "Fehler" ;
VAL_ 270 GE_Entkopplung_Status 0 "keine_Entkopplung" 1 "Entkopplungsvorgang_gestartet" 2 "Entkopplungszustand_erreicht" 3 "Entkopplung_nicht_moeglich" ;
VAL_ 270 GE_Verlustmoment 255 "Fehler" ;
VAL_ 270 GE_Anf_Zylabsch 0 "Umschaltung_erlaubt" 1 "Umschaltung_verboten" 3 "VMB_Empfehlung" ;
VAL_ 270 GE_Grenzkriechmoment 62 "Init" 63 "Fehler" ;
VAL_ 270 GE_Eingangsdrehz 16382 "Init" 16383 "Fehler" ;
VAL_ 270 GE_Notlauf 0 "kein Notlauf / Init" 1 "Getriebe im Notlauf" ;
VAL_ 270 GE_Freig_Langfr_Schutzmom 0 "nicht_freigegeben" 1 "freigegeben" ;
VAL_ 270 GE_HYB_Fehlerstatus 0 "kein_Fehler" 1 "kein_Hydraulikdruck" 2 "Anforderung_N_gleich_0" 3 "beide_Fehler" ;
VAL_ 270 GE_HYB_DZ_Eingriff 0 "kein_Drehzahleingriff" 1 "Slip_Start" 2 "Low_Speed_Modus" ;
VAL_ 270 GE_HYB_Freigabe_K0 0 "Freigabe_K0_oeffnen" 1 "Freigabe_K0_schliessen" ;
VAL_ 270 GE_HYB_MaxMomK0 0 "keine_Reduktion" 1 "Reduktionsstufe_1" 2 "Reduktionsstufe_2" 3 "Reduktionsstufe_3" ;
VAL_ 270 GE_HYB_Freig_VM_EM_Stop 0 "VM_EM_darf_nicht_stoppen" 1 "VM_EM_darf_stoppen" ;
VAL_ 270 GE_HYB_Wiederstart 0 "kein_Wiederstart_aktiv" 1 "Wiederstart_aktiv" ;
VAL_ 270 GE_HYB_Filt_MomAufbau 0 "keine_Beeinflussung_der_Filterung_durch_Getriebe" 1 "multiplikative_Konstante_fuer_MSG" 2 "multiplikative_Konstante_fuer_MSG" 3 "multiplikative_Konstante_fuer_MSG" 4 "multiplikative_Konstante_fuer_MSG" 5 "multiplikative_Konstante_fuer_MSG" 6 "multiplikative_Konstante_fuer_MSG" 7 "multiplikative_Konstante_fuer_MSG" ;
VAL_ 270 GE_HYB_nK0 255 "Fehler" ;
VAL_ 270 GE_HYB_IstStatus_K0 0 "auf" 1 "Uebergang" 2 "zu" 3 "Fehler" ;
VAL_ 270 GE_HYB_VM_Soll_Moment 254 "kein_Eingriff" 255 "Fehler" ;
VAL_ 270 GE_HYB_Sportfaktor 0 "nicht_sportlich" ;
VAL_ 270 GE_HYB_Freigabe_LL_Reg 0 "keine_DZ_reg_erlaubt" 1 "LL_Reg_freigegeben" ;
VAL_ 270 GE_HYB_VM_akt_halten 0 "keine_Empfehlung" 1 "VM_aktiv_halten_starten" ;
VAL_ 270 GE_HYB_StartAnf 0 "keine_Startanforderung" 1 "Startanforderung" ;
VAL_ 270 GE_HYB_VM_Startkontr 0 "VM_StartAnf_nicht_freigegeben" 1 "VM_StartAnf_freigegeben" ;
VAL_ 270 GE_Radmoment 65534 "Init" 65535 "Fehler" ;
VAL_ 270 GE_Abtriebsdrehzahl 65534 "Init" 65535 "Fehler" ;
VAL_ 270 GE_Eingangswellengradient 65534 "Init" 65535 "Fehler" ;
VAL_ 509 GE_OBD_AbsperrVent 0 "kein Fehler / Init / nicht verbaut" 1 "KS- (Kurzschluss nach minus)" 2 "KS+ (Kurzschluss nach plus)" 3 "OC (Leitungsunterbrechung)" 4 "OOR+ (Signal zu gross)" 5 "OOR- (Signal zu klein)" 6 "RC+ (Signal unplausibel zu gross)" 7 "RC- (Signal unplausibel zu klein)" 8 "KS+/OC (Kurzschluss nach plus/Unterbrechung)" 9 "KS-/OC  (Kurzschluss nach minus/Unterbrechung)" 10 "KS-/KS+  (Kurzschluss nach minus/plus)" 11 "KS-/KS+/OC (Kurzschluss nach minus/plus/Unterbrechung)" 12 "Position_unbekannt" 13 "Failsafe_Position" 14 "Referenzfahrt_aktiv" 15 "frei" ;
VAL_ 509 GE_amax_moeglich 511 "nicht_definiert" ;
VAL_ 509 GE_Charisma_FahrPr 0 "keine_Funktion" 1 "Programm_1" 2 "Programm_2" 3 "Programm_3" 4 "Programm_4" 5 "Programm_5" 6 "Programm_6" 7 "Programm_7" 8 "Programm_8" 9 "Programm_9" 10 "Programm_10" 11 "Programm_11" 12 "Programm_12" 13 "Programm_13" 14 "Programm_14" 15 "Programm_15" ;
VAL_ 509 GE_Charisma_Status 0 "Init" 1 "verfuegbar" 2 "nicht_verfuegbar" 3 "asynchron_durch_Fahrerwunsch" ;
VAL_ 509 GE_Freigabe_Verfallsinfo_WFS 0 "Aus" 1 "Ein" ;
VAL_ 509 Freilauf_Charisma_FahrPr 0 "keine_Funktion" 1 "Programm_1" 2 "Programm_2" 3 "Programm_3" 4 "Programm_4" 5 "Programm_5" 6 "Programm_6" 7 "Programm_7" 8 "Programm_8" 9 "Programm_9" 10 "Programm_10" 11 "Programm_11" 12 "Programm_12" 13 "Programm_13" 14 "Programm_14" 15 "Programm_15" ;
VAL_ 509 Freilauf_Charisma_Status 0 "Init" 1 "verfuegbar" 2 "nicht_verfuegbar" 3 "asynchron_durch_Fahrerwunsch" ;
VAL_ 509 GE_Freigabe_Info_WFS 0 "ungueltig" 1 "gueltig" ;
VAL_ 509 GE_Sperr_Info_WFS 0 "nicht_gesperrt" 1 "gesperrt" ;
VAL_ 509 GE_Zustand_Kuppltemp 0 "Init" 1 "Kupplungstemp_normal" 2 "Kupplungstemp_hoch" 3 "Kupplungsschutz_aktivieren" ;
VAL_ 509 GE_Codierung_MSG 0 "Codierung iO / Init" 1 "Codierung niO" ;
VAL_ 509 GE_LaunchControl 0 "inaktiv" 1 "aktiv" ;
VAL_ 509 GE_Heizwunsch 0 "maximaler_Waermebedarf" 1 "kein_Waermebedarf" 2 "Kuehlbedarf" 3 "Notfall_(maximaler_Kuehlbedarf)" ;
VAL_ 509 GE_OBD_Status 0 "MIL aus" 1 "MIL ein" ;
VAL_ 509 GE_LFR_Adaption 0 "fuer_Adaption_geeignet" 1 "fuer_Adaption_nicht_geeignet" ;
VAL_ 509 GE_Sumpftemperatur 255 "Fehler" ;
VAL_ 509 GE_Schleuderoeltemperatur 254 "Init" 255 "Fehler" ;
VAL_ 509 GE_Weckleitung_aktiv 0 "inaktiv" 1 "aktiv" ;
VAL_ 509 GE_Fahrprogramm 0 "Init" 1 "nicht_belegt" 2 "Normal" 3 "Sport" 4 "Offroad" 5 "Efficiency" 6 "Sport_Plus" 7 "Sport_Response" 10 "Snow" 11 "Gravel" 12 "Mud_Ruts" 13 "Sand_Dune" ;
VAL_ 509 GE_TippZustand 0 "Init_Kein_Tipp" 1 "Tipp_permanent" 2 "Tipp_temporaer" ;
VAL_ 509 GE_Freilauf_Status 0 "Freilauf_inaktiv_aber_moeglich" 1 "Freilauf_aktiv" 2 "Freilauf_nicht_moegl_1Verhinderer" 3 "Freilauf_nicht_moegl_gr_1Verhinderer" 7 "Fehler" ;
VAL_ 509 GE_Grundeinstellung 0 "inaktiv" 1 "aktiv" ;
VAL_ 509 GE_Anschleppstart_Freigabe 0 "keine_Freigabe" 1 "Freigabe" ;
VAL_ 509 GE_Strombedarf_erh 0 "keine_Anforderung" 1 "erhoehte_Anforderung" ;
VAL_ 509 GE_Parken_WFS_Status 0 "Limitierung_Inaktiv" 1 "Limitierung_Aktiv" 2 "Abbruch" ;
VAL_ 509 FSA_Fehlerstatus_Parksperre 0 "Init" 1 "Parksperre_iO" 2 "Parksperre_eingeschraenkt" 3 "Parksperre_defekt" ;
VAL_ 509 GE_SpannungsAnf 0 "keine_Anforderung" 1 "Anforderung_Stufe1" 2 "Anforderung_Stufe2" 3 "Anforderung_Stufe3" ;
VAL_ 509 GE_QBit_Sumpftemperatur 0 "gueltiger_Wert" 1 "Ersatz_Init_oder_Fehlerwert" ;
VAL_ 509 GE_Grundeinstell_Drehrichtung_EM 0 "keine_Vorgabe" 1 "rueckwaerts" ;
VAL_ 509 GE_Veto_Rollfaehigkeit 0 "kein_Veto__Rollfaehigkeit_moegl" 1 "Veto__Rollfaehigkeit_nicht_moegl" ;
VAL_ 509 GE_Parken_beibehalten_HMS 0 "Parken_nicht_beibehalten" 1 "Parken_beibehalten" 2 "Init" 3 "Fehler" ;
VAL_ 509 GE_Anforderung_HMS 0 "keine_Anforderung" 1 "halten" 2 "parken" 3 "halten_Standby" 4 "anfahren" 5 "Loesen_ueber_Rampe" ;
VAL_ 509 GE_Betaetigung_Hold 0 "kein_Hold" 1 "Hold_aktivieren" ;
VAL_ 2589283964 GE_OBD_Status_Auth 0 "MIL aus" 1 "MIL ein" ;
VAL_ 2589283964 GE_Indc_StChk 0 "Test_Completed" 1 "Test_Not_Completed" ;
VAL_ 2589283964 GE_Indc_StFail 0 "Passive" 1 "Active" ;
VAL_ 299 GRA_Hauptschalter 0 "Aus_Taster_nicht_betaetigt" 1 "Ein_Taster_betaetigt" ;
VAL_ 299 GRA_Abbrechen 0 "nicht_betaetigt" 1 "betaetigt" ;
VAL_ 299 GRA_Typ_Hauptschalter 0 "gerasteter_Lenkstockschalter" 1 "getasteter_Lenkstockschalter" ;
VAL_ 299 GRA_Limiter 0 "nicht_betaetigt" 1 "betaetigt" ;
VAL_ 299 GRA_Tip_Setzen 0 "nicht_betaetigt" 1 "betaetigt" ;
VAL_ 299 GRA_Tip_Hoch 0 "nicht_betaetigt" 1 "betaetigt" ;
VAL_ 299 GRA_Tip_Runter 0 "nicht_betaetigt" 1 "betaetigt" ;
VAL_ 299 GRA_Tip_Wiederaufnahme 0 "nicht_betaetigt" 1 "betaetigt" ;
VAL_ 299 GRA_Verstellung_Zeitluecke 0 "Taste_nicht_betaetigt" 1 "Dist_minus_1" 2 "Dist_plus_1" 3 "Dist_Toggle" ;
VAL_ 299 GRA_Codierung 0 "kein_Hebel" 1 "GRA_Hebel" 2 "ACC_Hebel" 3 "Limiter_Only" ;
VAL_ 299 GRA_Fehler 0 "kein_Fehler" 1 "Fehler" ;
VAL_ 299 GRA_LIM_Taste_verfuegbar 0 "Limiter_Taste_nicht_vorhanden" 1 "Limiter_Taste_vorhanden" ;
VAL_ 299 GRA_Tip_Stufe_2 0 "Tip_Stufe_1_keine_Betaetigung" 1 "Tip_Stufe_2" ;
VAL_ 299 GRA_Typ_Bedienteil 0 "Init" 1 "4_Positions_Bedienteil" 2 "6_Positions_Bedienteil" 3 "8_Positions_Bedienteil" 4 "PAG_5_Positions_Bedienteil" 5 "VW_MFL_Gen2" 6 "VW_MFL_Gen3" 7 "PAG_DX1_Bedienteil" ;
VAL_ 299 GRA_TravelAssist 0 "nicht_betaetigt" 1 "betaetigt" ;
VAL_ 299 GRA_PIT_Limiter 0 "nicht_betaetigt" 1 "betaetigt" ;
VAL_ 2589283397 GW_CAL_ID_Index_01 63 "Init" ;
VAL_ 2589283397 GW_CAL_ID_Index_02 63 "Init" ;
VAL_ 2589283397 GW_CAL_ID_Index_03 63 "Init" ;
VAL_ 2589283397 GW_CAL_ID_Index_04 63 "Init" ;
VAL_ 2589283397 GW_CAL_ID_Index_05 63 "Init" ;
VAL_ 2589283397 GW_CAL_ID_Index_06 63 "Init" ;
VAL_ 2589283397 GW_CAL_ID_Index_07 63 "Init" ;
VAL_ 2589283397 GW_CAL_ID_Index_08 63 "Init" ;
VAL_ 2589283397 GW_CAL_ID_Index_09 63 "Init" ;
VAL_ 2589283397 GW_CAL_ID_Index_10 63 "Init" ;
VAL_ 2589283397 GW_CAL_ID_Index_11 63 "Init" ;
VAL_ 2589283397 GW_CAL_ID_Index_12 63 "Init" ;
VAL_ 2589283397 GW_CAL_ID_Index_13 63 "Init" ;
VAL_ 2589283397 GW_CAL_ID_Index_14 63 "Init" ;
VAL_ 2589283397 GW_CAL_ID_Index_15 63 "Init" ;
VAL_ 2589283397 GW_CAL_ID_Index_16 63 "Init" ;
VAL_ 2589283397 GW_KomponentenFehler_01 0 "TestComplete_PASS" 1 "TestComplete_FAIL" 2 "TestNotComplete_PASS" ;
VAL_ 2589283397 GW_Komponentenfehler_02 0 "TestComplete_PASS" 1 "TestComplete_FAIL" 2 "TestNotComplete_PASS" ;
VAL_ 2589283397 GW_Komponentenfehler_03 0 "TestComplete_PASS" 1 "TestComplete_FAIL" 2 "TestNotComplete_PASS" ;
VAL_ 2589283397 GW_Komponentenfehler_04 0 "TestComplete_PASS" 1 "TestComplete_FAIL" 2 "TestNotComplete_PASS" ;
VAL_ 2589283397 GW_Komponentenfehler_05 0 "TestComplete_PASS" 1 "TestComplete_FAIL" 2 "TestNotComplete_PASS" ;
VAL_ 2589283397 GW_Komponentenfehler_06 0 "TestComplete_PASS" 1 "TestComplete_FAIL" 2 "TestNotComplete_PASS" ;
VAL_ 2589283397 GW_Komponentenfehler_07 0 "TestComplete_PASS" 1 "TestComplete_FAIL" 2 "TestNotComplete_PASS" ;
VAL_ 2589283397 GW_Komponentenfehler_08 0 "TestComplete_PASS" 1 "TestComplete_FAIL" 2 "TestNotComplete_PASS" ;
VAL_ 2589283397 GW_Komponentenfehler_09 0 "TestComplete_PASS" 1 "TestComplete_FAIL" 2 "TestNotComplete_PASS" ;
VAL_ 2589283397 GW_Komponentenfehler_10 0 "TestComplete_PASS" 1 "TestComplete_FAIL" 2 "TestNotComplete_PASS" ;
VAL_ 2589283397 GW_Komponentenfehler_11 0 "TestComplete_PASS" 1 "TestComplete_FAIL" 2 "TestNotComplete_PASS" ;
VAL_ 2589283397 GW_Komponentenfehler_12 0 "TestComplete_PASS" 1 "TestComplete_FAIL" 2 "TestNotComplete_PASS" ;
VAL_ 2589283397 GW_Komponentenfehler_13 0 "TestComplete_PASS" 1 "TestComplete_FAIL" 2 "TestNotComplete_PASS" ;
VAL_ 2589283397 GW_Komponentenfehler_14 0 "TestComplete_PASS" 1 "TestComplete_FAIL" 2 "TestNotComplete_PASS" ;
VAL_ 2589283397 GW_Komponentenfehler_15 0 "TestComplete_PASS" 1 "TestComplete_FAIL" 2 "TestNotComplete_PASS" ;
VAL_ 2589283397 GW_Komponentenfehler_16 0 "TestComplete_PASS" 1 "TestComplete_FAIL" 2 "TestNotComplete_PASS" ;
VAL_ 2589283397 GW_CVN 0 "Init" ;
VAL_ 2589283397 GW_Komponentenfehler_17 0 "TestComplete_PASS" 1 "TestComplete_FAIL" 2 "TestNotComplete_PASS" ;
VAL_ 2589283397 GW_Komponentenfehler_18 0 "TestComplete_PASS" 1 "TestComplete_FAIL" 2 "TestNotComplete_PASS" ;
VAL_ 2589283397 GW_Komponentenfehler_19 0 "TestComplete_PASS" 1 "TestComplete_FAIL" 2 "TestNotComplete_PASS" ;
VAL_ 2589283397 GW_Komponentenfehler_20 0 "TestComplete_PASS" 1 "TestComplete_FAIL" 2 "TestNotComplete_PASS" ;
VAL_ 2589283397 GW_Komponentenfehler_21 0 "TestComplete_PASS" 1 "TestComplete_FAIL" 2 "TestNotComplete_PASS" ;
VAL_ 2589283397 GW_Komponentenfehler_22 0 "TestComplete_PASS" 1 "TestComplete_FAIL" 2 "TestNotComplete_PASS" ;
VAL_ 2589283397 GW_Komponentenfehler_23 0 "TestComplete_PASS" 1 "TestComplete_FAIL" 2 "TestNotComplete_PASS" ;
VAL_ 2589283397 GW_Komponentenfehler_24 0 "TestComplete_PASS" 1 "TestComplete_FAIL" 2 "TestNotComplete_PASS" ;
VAL_ 2589283397 GW_Komponentenfehler_25 0 "TestComplete_PASS" 1 "TestComplete_FAIL" 2 "TestNotComplete_PASS" ;
VAL_ 2589283397 GW_Komponentenfehler_26 0 "TestComplete_PASS" 1 "TestComplete_FAIL" 2 "TestNotComplete_PASS" ;
VAL_ 2589283397 GW_Komponentenfehler_27 0 "TestComplete_PASS" 1 "TestComplete_FAIL" 2 "TestNotComplete_PASS" ;
VAL_ 2589283397 GW_Komponentenfehler_28 0 "TestComplete_PASS" 1 "TestComplete_FAIL" 2 "TestNotComplete_PASS" ;
VAL_ 2589283397 GW_Komponentenfehler_29 0 "TestComplete_PASS" 1 "TestComplete_FAIL" 2 "TestNotComplete_PASS" ;
VAL_ 2589283397 GW_Komponentenfehler_30 0 "TestComplete_PASS" 1 "TestComplete_FAIL" 2 "TestNotComplete_PASS" ;
VAL_ 2589283397 GW_Komponentenfehler_31 0 "TestComplete_PASS" 1 "TestComplete_FAIL" 2 "TestNotComplete_PASS" ;
VAL_ 2589283397 GW_Komponentenfehler_32 0 "TestComplete_PASS" 1 "TestComplete_FAIL" 2 "TestNotComplete_PASS" ;
VAL_ 2589283397 GW_Komponentenfehler_33 0 "TestComplete_PASS" 1 "TestComplete_FAIL" 2 "TestNotComplete_PASS" ;
VAL_ 2589283397 GW_Komponentenfehler_34 0 "TestComplete_PASS" 1 "TestComplete_FAIL" 2 "TestNotComplete_PASS" ;
VAL_ 2589283397 GW_Komponentenfehler_35 0 "TestComplete_PASS" 1 "TestComplete_FAIL" 2 "TestNotComplete_PASS" ;
VAL_ 2589283397 GW_Komponentenfehler_36 0 "TestComplete_PASS" 1 "TestComplete_FAIL" 2 "TestNotComplete_PASS" ;
VAL_ 2589283397 GW_Komponentenfehler_37 0 "TestComplete_PASS" 1 "TestComplete_FAIL" 2 "TestNotComplete_PASS" ;
VAL_ 2589283397 GW_Komponentenfehler_38 0 "TestComplete_PASS" 1 "TestComplete_FAIL" 2 "TestNotComplete_PASS" ;
VAL_ 2589283397 GW_Komponentenfehler_39 0 "TestComplete_PASS" 1 "TestComplete_FAIL" 2 "TestNotComplete_PASS" ;
VAL_ 2589283397 GW_Komponentenfehler_40 0 "TestComplete_PASS" 1 "TestComplete_FAIL" 2 "TestNotComplete_PASS" ;
VAL_ 2589283397 GW_Komponentenfehler_41 0 "TestComplete_PASS" 1 "TestComplete_FAIL" 2 "TestNotComplete_PASS" ;
VAL_ 2589283397 GW_Komponentenfehler_42 0 "TestComplete_PASS" 1 "TestComplete_FAIL" 2 "TestNotComplete_PASS" ;
VAL_ 2589283397 GW_Komponentenfehler_43 0 "TestComplete_PASS" 1 "TestComplete_FAIL" 2 "TestNotComplete_PASS" ;
VAL_ 2589283397 GW_Komponentenfehler_44 0 "TestComplete_PASS" 1 "TestComplete_FAIL" 2 "TestNotComplete_PASS" ;
VAL_ 2589283397 GW_Komponentenfehler_45 0 "TestComplete_PASS" 1 "TestComplete_FAIL" 2 "TestNotComplete_PASS" ;
VAL_ 2589283397 GW_Komponentenfehler_46 0 "TestComplete_PASS" 1 "TestComplete_FAIL" 2 "TestNotComplete_PASS" ;
VAL_ 2589283397 GW_Komponentenfehler_47 0 "TestComplete_PASS" 1 "TestComplete_FAIL" 2 "TestNotComplete_PASS" ;
VAL_ 2589283397 GW_Komponentenfehler_VLD 0 "ungueltig" 1 "gueltig" ;
VAL_ 2589283397 GW_CVN_VLD 0 "ungueltig" 1 "gueltig" ;
VAL_ 2589284072 GW_Komponentenfehler_48 0 "TestComplete_PASS" 1 "TestComplete_FAIL" 2 "TestNotComplete_PASS" ;
VAL_ 2589284072 GW_Komponentenfehler_49 0 "TestComplete_PASS" 1 "TestComplete_FAIL" 2 "TestNotComplete_PASS" ;
VAL_ 2589284072 GW_Komponentenfehler_50 0 "TestComplete_PASS" 1 "TestComplete_FAIL" 2 "TestNotComplete_PASS" ;
VAL_ 2589284072 GW_Komponentenfehler_51 0 "TestComplete_PASS" 1 "TestComplete_FAIL" 2 "TestNotComplete_PASS" ;
VAL_ 2589284072 GW_Komponentenfehler_52 0 "TestComplete_PASS" 1 "TestComplete_FAIL" 2 "TestNotComplete_PASS" ;
VAL_ 2589284072 GW_Komponentenfehler_53 0 "TestComplete_PASS" 1 "TestComplete_FAIL" 2 "TestNotComplete_PASS" ;
VAL_ 2589284072 GW_Komponentenfehler_54 0 "TestComplete_PASS" 1 "TestComplete_FAIL" 2 "TestNotComplete_PASS" ;
VAL_ 2589284072 GW_Komponentenfehler_55 0 "TestComplete_PASS" 1 "TestComplete_FAIL" 2 "TestNotComplete_PASS" ;
VAL_ 2589284072 GW_Komponentenfehler_56 0 "TestComplete_PASS" 1 "TestComplete_FAIL" 2 "TestNotComplete_PASS" ;
VAL_ 2589284072 GW_Komponentenfehler_57 0 "TestComplete_PASS" 1 "TestComplete_FAIL" 2 "TestNotComplete_PASS" ;
VAL_ 2589284072 GW_Komponentenfehler_58 0 "TestComplete_PASS" 1 "TestComplete_FAIL" 2 "TestNotComplete_PASS" ;
VAL_ 2589284072 GW_Komponentenfehler_59 0 "TestComplete_PASS" 1 "TestComplete_FAIL" 2 "TestNotComplete_PASS" ;
VAL_ 2589284072 GW_Komponentenfehler_60 0 "TestComplete_PASS" 1 "TestComplete_FAIL" 2 "TestNotComplete_PASS" ;
VAL_ 2589284072 GW_Komponentenfehler_61 0 "TestComplete_PASS" 1 "TestComplete_FAIL" 2 "TestNotComplete_PASS" ;
VAL_ 2589284072 GW_Komponentenfehler_62 0 "TestComplete_PASS" 1 "TestComplete_FAIL" 2 "TestNotComplete_PASS" ;
VAL_ 2589284072 GW_Komponentenfehler_63 0 "TestComplete_PASS" 1 "TestComplete_FAIL" 2 "TestNotComplete_PASS" ;
VAL_ 2589284072 GW_Komponentenfehler_64 0 "TestComplete_PASS" 1 "TestComplete_FAIL" 2 "TestNotComplete_PASS" ;
VAL_ 1452 HVEM_IstStrom_HVVerbraucher 4094 "Init" 4095 "Fehler" ;
VAL_ 1452 HVEM_Energie_Klima_Vorgabe_HighR 6 "Init" 7 "Fehler" ;
VAL_ 1452 HVEM_IstLeistungNA 510 "Init" 511 "Fehler" ;
VAL_ 1452 HVEM_Leistung_Klima_Vorgabe 254 "Init" 255 "Fehler" ;
VAL_ 1452 HVEM_Nutzbare_Energie 2045 "Max" 2046 "Init" 2047 "Fehler" ;
VAL_ 1452 HVEM_Energie_Klima_Vorgabe 254 "Init" 255 "Fehler" ;
VAL_ 1452 HVEM_HVK_Aktivitaet 0 "keine_Aktivitaet" 1 "Aktivitaet" 2 "Init" ;
VAL_ 1452 HVEM_Pruefpuls_Anf 0 "Keine_Anforderung" 1 "Anforderung" 2 "Reserved" 3 "Init" ;
VAL_ 1452 HVEM_NVEM_Leistungsvorgabe 126 "Init" 127 "Fehler" ;
VAL_ 1452 HVEM_HV_Anf 0 "keine_Anforderung" 1 "HV_angefordert" ;
VAL_ 1452 HVEM_MO_MaxLeistungIgnoriert 0 "Max_Leistung_nicht_ignoriert" 1 "Max_Leistung_ignoriert" ;
VAL_ 1385 HVEM_ZusatzMinLeistungNA_Anf 510 "Init" ;
VAL_ 1385 HVEM_Betriebsart 0 "Standby" 1 "HV_Aktiv" 3 "Fahrbereit" 4 "HV_Laden" 5 "Autonom" ;
VAL_ 1385 HVEM_DCDC_Freigabe 0 "keine_Freigabe" 1 "Freigabe" ;
VAL_ 1385 HVEM_Ladesteckerentr_Anf 0 "keine_Anforderung" 1 "Anf_Ladestecker_Entr" ;
VAL_ 1385 HVEM_LeistungsAnf 0 "nicht_angefordert" 1 "angefordert" ;
VAL_ 1385 HVEM_Nachlad_Status 0 "nicht_moeglich__Fehler" 1 "moeglich__begonnen" 2 "Beendet" 3 "Init" ;
VAL_ 1385 HVEM_Abschaltstatus 0 "100" 1 "75" 2 "50" 3 "25" 7 "Init" ;
VAL_ 1385 HVEM_Anf_ReichweiteNV 0 "keine_Massnahme_notwendig" 1 "Reduktion_Stufe_1" 2 "Reduktion_Stufe_2" 3 "Fehler" ;
VAL_ 1385 HVEM_WunschLeistungNA_Anf 510 "Init" ;
VAL_ 1385 HVEM_Text_1 0 "kein_Text" 1 "Text" ;
VAL_ 1385 HVEM_Nachladen_Anf 0 "keine_Anforderung" 1 "Nachladen_angefordert" ;
VAL_ 1385 HVEM_FreigabeKlimatisierung 0 "keine_Freigabe" 1 "Freigabe" 2 "Init" 3 "Fehler" ;
VAL_ 1385 HVEM_FreigabeBattHeizung 0 "keine_Freigabe" 1 "Freigabe" 2 "Init" 3 "Fehler" ;
VAL_ 1385 HVEM_MinLeistungNA_Anf 510 "Init" ;
VAL_ 1385 HVEM_Leistung_Bat_Kond_Vorgabe 254 "Init" ;
VAL_ 1283 HVK_Istmodus_Anf 0 "nicht_angefordert" 1 "angefordert" ;
VAL_ 1283 HVK_TN1_Sollmodus 0 "HV_Off" 1 "HV_On" 2 "reserviert" 3 "Initialisierung" ;
VAL_ 1283 HVK_Vorladung_aktiv 0 "Vorladung_nicht_aktiv" 1 "Vorladung_aktiv" ;
VAL_ 1283 HVK_BMS_Sollmodus 0 "HV_Off" 1 "HV_On" 3 "AC_Laden_erw" 4 "AC_Laden" 6 "DC_Laden" 7 "Init" ;
VAL_ 1283 HVK_DCDC_Sollmodus 0 "Standby" 1 "HV_On_Vorladen" 2 "Tiefsetzen" 3 "Hochsetzen" 4 "Pruefpuls_12V" 6 "Pruefpuls_DC_Laden" 7 "Initialisierung" ;
VAL_ 1283 HVK_EKK_Sollmodus 0 "Keine_Freigabe" 1 "Freigabe" 2 "Freigabe_ausgesetzt" 7 "Init" ;
VAL_ 1283 HVK_HVPTC_Sollmodus 0 "Keine_Freigabe" 1 "Freigabe" 2 "Freigabe_ausgesetzt" 7 "Init" ;
VAL_ 1283 HVK_HVLM_Sollmodus 0 "keine_Freigabe" 1 "Freigabe_Lademanager" 2 "Vorladung_AC_Pfad" 7 "Init" ;
VAL_ 1283 HVK_HV_Netz_Warnungen 0 "Keine_Warnung" 1 "Warntext_HV_Netz_Anf" 2 "Fehlertext_HV_Netz_Anf" 3 "Warnung_Kein_Wiederstart_moeglich" ;
VAL_ 1283 HV_Bordnetz_aktiv 0 "inaktiv" 1 "aktiv" ;
VAL_ 1283 HV_Bordnetz_Fehler 0 "kein_Fehler" 1 "Fehler" ;
VAL_ 1283 HVK_Gesamtst_Spgfreiheit 0 "Funktion_Init__ohne_Funktion" 1 "HV_System_spannungsfrei" 2 "HV_System_nicht_spannungsfrei" 3 "Fehler" ;
VAL_ 1283 HVK_AktiveEntladung_Anf 0 "nicht_angefordert" 1 "angefordert" ;
VAL_ 1283 HVK_HVEM_Freigabe 0 "keine_Freigabe" 1 "Freigabe" 2 "Init" ;
VAL_ 1283 HVK_Notabschaltung_Anf 0 "keine_Anforderung_Notabschaltung" 1 "Anforderung_Notabschaltung" 2 "Reserve" 3 "Init" ;
VAL_ 1283 HVK_Iso_Messung_Start 0 "keine_Messung" 1 "Messung_HV_Netz_1" 2 "Messung_HV_Netz_2" 4 "deaktiviert" ;
VAL_ 1283 HVK_Ladebereit 0 "Init_oder_nicht_Ladebereit" 1 "AC_Ladebereit" 2 "DC_Ladebereit" 3 "AC_und_DC_Ladebereit" 4 "Induktiv_Ladebereit" 5 "AC_und_Induktiv_Ladebereit" 6 "DC_und_Induktiv_Ladebereit" 7 "AC_DC_und_Induktiv_Ladebereit" ;
VAL_ 1283 HVK_PPulsFreigabe 0 "keine_Freigabe" 1 "Freigabe" 2 "Reserve" 3 "Init" ;
VAL_ 2331595857 HVK_BMS_DC_Ladeschuetze_Soll 0 "auf" 1 "zu" 2 "reserviert" 3 "reserviert" 4 "reserviert" 5 "reserviert" 6 "Init" 7 "reserviert" ;
VAL_ 2331595857 HVK_BMS_Hauptschuetze_Soll 0 "auf" 1 "zu" 2 "reserviert" 3 "reserviert" 4 "reserviert" 5 "reserviert" 6 "Init" 7 "reserviert" ;
VAL_ 2331595857 HVK_DC_PruefpulsStatus 0 "Pruefpuls_inaktiv" 1 "Pruefpuls_aktiv" 2 "Pruefspannung_erreicht" 3 "Init" ;
VAL_ 2463978813 HVL_Steckerstatus 0 "Init" 1 "kein_Stecker_erkannt" 2 "Stecker_erkannt" 3 "Fehler" ;
VAL_ 2463978813 HVL_Status_EoHVL 0 "Init" 1 "Keine_offene_HV_Leitung_erkannt" 2 "offene_HV_Leitung_erkannt" 3 "Fehler" ;
VAL_ 2463978813 HVL_Kuehltemperatur 254 "Init" 255 "Fehler" ;
VAL_ 2463978813 HVL_LadeAnforderung 0 "Laden_nicht_angefordert" 1 "AC_Laden_Angefordert" 2 "DC_Laden_Angefordert" 3 "AC_und_DC_Angefordert" 4 "Induktiv_Laden_Angef" 5 "AC_und_Induktiv_Angef" 6 "DC_und_Induktiv_Angef" 7 "AC_DC_und_Induktiv_Angef" ;
VAL_ 2463978813 HVL_HVK_Fehler_DCAbschaltung 0 "keine_Anforderung_Init" 1 "Anforderung_DC_Notabschaltung" ;
VAL_ 2463978813 HVL_Status_Spgfreiheit 0 "Init__ohne_Funktion" 1 "HV_Komponente_Spannungsfrei" 2 "HV_Komponente_nichtSpannungsfrei" 3 "Fehler" ;
VAL_ 2463978813 HVL_OCC_IstModus 0 "Standby" 1 "Netzladung_aktiv" 2 "Rueckspeisung_aktiv" 3 "reserve" 4 "reserve" 5 "reserve" 6 "Init" 7 "Fehler" ;
VAL_ 2463978813 HVL_OBG_Typ_verbaut 0 "IPB_galvanisch_nichtGetrennt" 1 "SAC" 2 "OCC" 3 "IPB_galvanisch_getrennt" 4 "SAC_galvanisch_getrennt" 5 "Reserve" 6 "Reserve" 7 "Init" ;
VAL_ 2463978689 HVLM_SollSoCKonservierung 126 "Init" 127 "Fehler" ;
VAL_ 2463978689 HVLM_BCCMKundenfreigabe_Status 0 "keine_Freigabe" 1 "Freigabe_alle_Stufen" 2 "Freigabe_eine_Stufe" 3 "Freigabe_zwei_Stufen" 4 "Freigabe_drei_Stufen" 5 "Reserve" 6 "Reserve" 7 "In_Funktion_nicht_enthalten" ;
VAL_ 2463978689 HVLM_BCCM_SoC 14 "Init" 15 "Fehler" ;
VAL_ 2463978689 HVLM_IstKonsWunschHVBat 0 "kein_Konservierungswunsch" 1 "Konservierungswunsch" ;
VAL_ 2463978689 HVLM_BCAM_Aktiv 0 "inaktiv" 1 "aktiv" ;
VAL_ 2463978689 HVLM_FreigabeLeistungNebenverbr 511 "Fehler" ;
VAL_ 2463978689 HVLM_IstStrom_02 8190 "Init" 8191 "Fehler" ;
VAL_ 626 HVLM_Aktive_Ladeart 0 "Kein_Laden_aktiv" 1 "AC_Laden_aktiv" 2 "DC_Laden_aktiv" 3 "AWC" 4 "Reserve" 5 "Reserve" 6 "Reserve" 7 "Fehler" ;
VAL_ 626 HVLM_Pulsierstufe 0 "keine_Anforderung" 1 "Stufe_0" 2 "Stufe_1" 3 "Stufe_2" 4 "Stufe_3" 5 "Stufe_4" 6 "Stufe_5" 7 "Stufe_6" ;
VAL_ 626 HVLM_Intensitaet_Lk2 126 "Init" 127 "Fehler" ;
VAL_ 626 HVLM_Anforderung_HMS 0 "keine_Anforderung" 1 "halten" 2 "parken" 3 "halten_Standby" 4 "anfahren" 5 "Loesen_ueber_Rampe" ;
VAL_ 626 HVLM_Parken_beibehalten_HMS 0 "Parken_nicht_beibehalten" 1 "Parken_beibehalten" 2 "Init" 3 "Fehler" ;
VAL_ 626 HVLM_WakeUpZaehlerResetAnf 0 "keine_Anforderung" 1 "Reset_Zaehler" ;
VAL_ 626 HVLM_AWC_VerbautStatus 0 "Init" 1 "nicht_verbaut" 2 "verbaut" 3 "Fehler" ;
VAL_ 626 HVLM_Steckerstatus_A 0 "Init" 1 "kein_Stecker_erkannt" 2 "Stecker_steckt_nicht_verriegelt" 3 "Stecker_steckt_und_verriegelt" 7 "Fehler" ;
VAL_ 626 HVLM_Steckerstatus_B 0 "Init" 1 "kein_Stecker_erkannt" 2 "Stecker_steckt_nicht_verriegelt" 3 "Stecker_steckt_und_verriegelt" 7 "Fehler" ;
VAL_ 626 HVLM_Start_Pulserkennung 0 "keine_Anforderung" 1 "Pulserkennung_starten" ;
VAL_ 626 HVLM_ZustandLadeablauf 0 "Init" 1 "Stby_Ladevorbed_erfuellt" 2 "Stby_Ladevorbed_nicht_erfuellt" 3 "Fehler" 4 "Laden_starten" 5 "Laden_beenden" 6 "HVBatterie_Laden" 7 "HVBatterie_Entladen" 8 "Erhaltungsladen" ;
VAL_ 626 HVLM_DC_Aufstartmodus 0 "keine_Anforderung" 1 "Angleich_Fahrzeug" 2 "Angleich_LS_1" 3 "Angleich_LS_2" ;
VAL_ 626 HVLM_Ladeszenario 0 "Aus" 1 "Timerladen_abgeschlossen" 2 "Sofortladen_abgeschlossen" 3 "Optimiertes_Laden_abgeschlossen" 4 "Timerladen_aktiv" 5 "Sofortladen_aktiv" 6 "Optimiertes_Laden_aktiv" 7 "Timerladen_warten" 8 "Optimiertes_Laden_warten" 9 "Keine_Netzspannung" 10 "Fehler_Verriegelung" 11 "Fehler_Ladesytem" 12 "Init_Ladekommunikation" 15 "Notladen" 16 "Ladeunterbrechung_Kunde" 17 "Stecker_abziehbar" 18 "Kompatibilitaets_Umschaltung_aktiv" 30 "Init" 31 "Fehler" ;
VAL_ 626 HVLM_Ladevorgang_Anf 0 "Laden_nicht_angefordert" 1 "AC_Laden_Angefordert" 2 "DC_Laden_Angefordert" 3 "AC_und_DC_Angefordert" 4 "Induktiv_Laden_Angef" 5 "AC_und_Induktiv_Angef" 6 "DC_und_Induktiv_Angef" 7 "AC_DC_und_Induktiv_Angef" ;
VAL_ 626 HVLM_Intensitaet_Lk1 126 "Init" 127 "Fehler" ;
VAL_ 626 HVLM_Laden_ISO_Messung_Anf 0 "Anforderung" 1 "keine_Anforderung" ;
VAL_ 268 ImoCord_Auth_Aufforderung_WFS 0 "nicht_anfordern" 1 "anfordern" ;
VAL_ 19 WFS_IMMO_GSG_Data_0 0 "Init" ;
VAL_ 19 WFS_IMMO_GSG_Data_1 0 "Init" ;
VAL_ 19 WFS_IMMO_GSG_Data_2 0 "Init" ;
VAL_ 17 WFS_IMMO_MSG1_Data_0 0 "Init" ;
VAL_ 17 WFS_IMMO_MSG1_Data_1 0 "Init" ;
VAL_ 17 WFS_IMMO_MSG1_Data_2 0 "Init" ;
VAL_ 23 WFS_IMMO_MSG3_Data_0 0 "Init" ;
VAL_ 23 WFS_IMMO_MSG3_Data_1 0 "Init" ;
VAL_ 23 WFS_IMMO_MSG3_Data_2 0 "Init" ;
VAL_ 25 WFS_IMMO_MSG4_Data_0 0 "Init" ;
VAL_ 25 WFS_IMMO_MSG4_Data_1 0 "Init" ;
VAL_ 25 WFS_IMMO_MSG4_Data_2 0 "Init" ;
VAL_ 312 IPA_Fahrstufenwunsch 0 "Init" 1 "Fahrstufe_beibehalten" 2 "Position_R" 3 "Position_D" 4 "Position_N" ;
VAL_ 312 IPA_Status 0 "Init" 4 "IPA_Anzeige_Aktiv" 5 "IPA_Fahreruebernahme" 6 "IPA_Aktiv" 7 "IPA_Standby" 8 "IPA_Funktionsbereit" 9 "IPA_PP_Aktivierung" 10 "IPA_Abbruch" 11 "IPA_Aktivierend" 15 "IPA_PP_Start" ;
VAL_ 2527679583 IPA_PL_Anzeige_links 0 "keine_PL_erkannt" 1 "links_Quer" 2 "links_Laengs" 3 "reserviert" ;
VAL_ 2527679583 IPA_PL_Anzeige_rechts 0 "keine_PL_erkannt" 1 "rechts_Quer" 2 "rechts_Laengs" 3 "reserviert" ;
VAL_ 2527679583 Parken_Seitenspiegel_Anf 0 "Keine_Anforderung" 1 "Seitenspiegel_anklappen" 2 "Seitenspiegel_abklappen" ;
VAL_ 2527679583 Parken_ZV_Schliessen 0 "Keine_Anforderung" 1 "ZV_verriegeln" 2 "ZV_safen" ;
VAL_ 2527679583 Parken_aktives_System_02 0 "Init" 1 "Keine_Aktivitaet" 2 "RPA" 3 "IPA" 4 "MA" 5 "TP" 6 "rTP" 7 "AAA" 8 "rAAA" 9 "ARA_1" 10 "PLA" 11 "RBF" 12 "PHP" 13 "RA" ;
VAL_ 2527679583 Parken_ZR_Sondermodus_Anf 0 "Init" 1 "Keine_Anforderung" 2 "Anforderung_Sondermodus" ;
VAL_ 2527679583 Parken_Schluesselsuche_Anf 0 "keine_Anforderung" 1 "Anforderung_Schluesselsuche" ;
VAL_ 2527679583 Parken_FFB_LED_Anf 0 "keine_Anforderung" 1 "Abbruch_Fehler" 2 "Bereit_OK" 3 "Beendet" ;
VAL_ 2527679583 Parken_Wegfahrsperren_Anf 0 "keine_Anforderung" 1 "Anforderung_Fahreruebernahme" 2 "Anforderung_Fahreruebergabe" ;
VAL_ 2527679583 Parken_Aktivierungslicht_Anf 0 "keine_Anforderung" 1 "Aktivierungslicht" ;
VAL_ 2527679583 Parken_Fahrtrichtungslicht_Anf 0 "keine_Anforderung" 1 "Vorwaerts" 2 "Rueckwaerts" ;
VAL_ 2527679583 Parken_Lichtnachlauf_Anf 0 "keine_Anforderung" 1 "Anforderung_Lichtnachlauf" ;
VAL_ 2527679583 IPA_Akustik_PL_gefunden 0 "keinen_Ton_ausgeben" 1 "Ton_ausgeben" ;
VAL_ 2527679583 Parken_Blinker_li_Anf 0 "keine_Anforderung" 1 "Blinker_links_aktivieren" ;
VAL_ 2527679583 Parken_Blinker_re_Anf 0 "keine_Anforderung" 1 "Blinker_rechts_aktivieren" ;
VAL_ 2527679583 Parken_Fahrerhinweise_Anf 0 "keine_Anforderung" 1 "Fahrerhinweise_anzeigen" ;
VAL_ 2527679583 Parken_Bestaetigungsblinken_Anf 0 "keine_Anforderung" 1 "Erfolgsblinken_Einparken" 2 "Abbruchsblinken" 3 "Erfolgsblinken_Ausparken" ;
VAL_ 2527679583 Parken_Fahrbereitschaftlicht_Anf 0 "keine_Anforderung" 1 "Fahrbereitschaftslicht" ;
VAL_ 2527679583 Parken_Lichtsteuerung_Anf 0 "keine_Anforderung" 1 "Automatik_Lichtmodus_aktivieren" ;
VAL_ 2527679583 IPA_Anf_Meldungen 0 "keine Meldung" 1 "beendet" 2 "Fahrinf_Bremse_FT_betaetigen" 3 "Suche_fortsetzen_ESC_Eingriff" 4 "n_a_temp_ESC_deaktiviert" 5 "n_a_temp_Anhaengerbetrieb" 6 "Suche_Zeitlimit_ueberschritten" 7 "Undefined" 8 "Fahrinf_PaLueSu_aufschalten" 9 "RPARemoteWunschAbgebrochen" 10 "IPAGeschwindigkeitReduzieren" 11 "IPARPAAktivierung2" 12 "AP_nicht_moeglich" 13 "RPAGarageStart" 14 "n_a_temp_Tuer_Heckklappe_offen" 15 "Stby_Tuer_Heckklappe_schliessen" 16 "PP_aktiv_nur_aussen_bedienbar" 17 "RPAUebergabe2" 18 "n_a_Offroad_Modus" 19 "PP_Schluessel_oder_App_bedienen" 20 "RPAUebergabe1" 21 "PP_Schluessel_bedienen" 22 "IPAAbbruchSuchfahrt" 23 "Systemstoerung_Service" 24 "n_a_temp_Sensorsicht" 25 "IPAAbbruchSuchfahrtLadestecke" 26 "IPAPausierenWeiterfahrt" 27 "n_a_temp_FAS_aktiv" 28 "PP_BT_unterbrochen" 29 "Hindernis_in_Fahrtrichtung" 30 "IPAAusparkenBlinker" 31 "RPAUebernahme" 32 "Suche_Rangierflaeche_zu_klein" 33 "n_a_temp_Drive_Select" 34 "IPAAktivierung1" 35 "Fahrinf_Fahrtrichtungswechsel" 36 "RPARemoteWunsch" 37 "GP_Fzgposition_vor_Garage" 38 "GP_RT_Garage_oeffnen" 39 "GP_Kein_Zuparken" 40 "Suche_Fahrinfo_beachten" 41 "GP_Fzgposition_freie_Parkflaeche" 42 "GP_n_a_temp_Laser" 43 "Geschwindigkeitsueberschreitung" 44 "Fahrinf_Weiter_vorfahren" 45 "RPAAktivierung1" 46 "Fahrinf_Anhalten" 47 "GP_AP_nicht_moeglich_Fahrweg" 48 "PP_Gang_Schluesselauthentifizier" 49 "Fahrhinweis_FT_betaetigen" 50 "PP_aktiv_Hinweis_FUEN" 128 "Disclaimer_LP_rechts" 129 "Disclaimer_LP_links" 130 "Disclaimer_RQ_rechts" 131 "Disclaimer_RQ_links" 132 "Disclaimer_VQ_rechts" 133 "Disclaimer_VQ_links" 134 "Disclaimer_AP_rechts" 135 "Disclaimer_AP_links" 136 "IPARPAAktivierung3" 137 "IPAAbbruchLenkeingriff" 138 "IPAAbbruchAnhaenger" 139 "IPARPAAktivierung4" 140 "IPAAbbruchZeitlimit" 141 "IPAFahrzeugAusgeparkt" 142 "IPAFahrzeugEingeparkt" 143 "IPAPausieren" 144 "IPAAbbruchESC" 145 "Stby_Verkehr_erkannt" 146 "MAAbbruchLenkeingriff" 147 "IPAAbbruchSchaltung" 148 "IPAAbbruchParklueckeKlein" 149 "IPABordsteinheber2" 150 "IPAAbbruchSensorsicht" 151 "Beendet_Stoerung_Fzgverbindung" 152 "Beendet_selbst_bremsen" 153 "IPAAbbruchFahrdynamischerEing" 154 "IPAAbbruchFalscheBewegungsric" 155 "IPAAbbruchDiETaSchliesskreuz" 156 "IPAPausierenHindernis" 157 "FUEN_moeglich" 158 "IPABordsteinheber4" 159 "IPAAbbruchOffroadModus" 160 "IPABordsteinheber5" 161 "PP_Fehler_Schluesselautorisier" 162 "IPABordsteinheber6" 163 "IPABordsteinheber7" 164 "Stby_FT_oder_RT_betaetigen" 165 "Stby_Hindernis_Richtungswechsel" 166 "Stby_erhoehter_Fahrwiderstand" 167 "Abbruch_EPB_aktiviert" 168 "Abbruch_MO_nicht_bereit" 169 "IPAAbbruchPDC" 170 "Abbruch_Gurtschloss_gesteckt" 171 "IPAAbbruchGeschwindigkeitHoch" 172 "IPAPausierenTueren" 173 "IPAAbbruchNotstopp" 174 "IPAAbbruchFahrerabwesenheit" 175 "IPAAbbruchSystempartner" 176 "PosOK_Lenkrad_loslassen_Bremse" 177 "PosOK_Lenkrad_loslassen_FT" 178 "Wiederaufnahme_FT_betaetigen" 179 "IPABordsteinheber9" 180 "IPAAbbruchKlemme15Aus" 181 "IPABordsteinheber8" 192 "TPA_aborted_deviated_from_trajec" 193 "TPA_aborted_limited_visibility" 194 "TPA_aborted_localization_failure" 195 "TPA_aborted_System_error" 196 "TPA_aborted_TPA_canceled" 197 "TPA_unavlbl_localization_failure" 198 "TPA_unavlbl_limited_visibility" 199 "TPA_unavlbl_System_error" 200 "TPA_temp_unavailable" 201 "rTPA_nicht_verfuegbar_TPA_bis_ZP" 202 "TPA_PP_belegt_TPA_Altern" 203 "TPA_PP_belegt_IPA_0_Altern" 204 "TPA_PP_belegt_IPA_1_Altern" 205 "TPA_PP_belegt_IPA_mehr_Altern" 206 "TPA_ausgerichtetes_Parken_aktiv" 207 "TPA_Ausparken_eingeschraenkt" ;
VAL_ 2589283690 LAD_OBD_Lampe_Anf 1 "MIL_Request" ;
VAL_ 2589283690 IPB_ThermAuslastungsgrad 101 "Notkuehlung" 254 "Init" 255 "Fehler" ;
VAL_ 2589283690 TNV_Temperatur 254 "Init" 255 "Fehler" ;
VAL_ 2589283690 IPB_Wasser_TEMP_EIN 254 "Init" 255 "Fehler" ;
VAL_ 2589283690 IPB_Wasser_TEMP_AUS 254 "Init" 255 "Fehler" ;
VAL_ 2589283690 HVLE_Temperatur 254 "Init" 255 "Fehler" ;
VAL_ 2589283690 HVLE_ThermAuslastungsgrad 101 "Notkuehlung" 254 "InitWert" 255 "Fehler" ;
VAL_ 2589283690 HVLE_eTM_max_Vorlauftemperatur 254 "Init" 255 "Fehler" ;
VAL_ 2589283690 OBDProtocol_Ladegeraet 0 "OBDonUDS" 1 "OBDclassic" 16 "NoOBD" 254 "Init" 255 "Fehler" ;
